AUTOSAR XML (schema 00044)
package /MICROSAR/NvM_swc/DataTypes
  impl type NvM_RequestResultType: compu {0=NVM_REQ_OK, 1=NVM_REQ_NOT_OK, 2=NVM_REQ_PENDING, 3=NVM_REQ_INTEGRITY_FAILED, 4=NVM_REQ_BLOCK_SKIPPED, 5=NVM_REQ_NV_INVALIDATED, 6=NVM_REQ_CANCELED, 7=NVM_REQ_REDUNDANCY_FAILED, 8=NVM_REQ_RESTORED_FROM_ROM}, range raw 0..8, implementation-data-type=uint8
  impl type NvM_BlockIdType: range raw 1..32767, implementation-data-type=uint16
  impl type NvM_ServiceIdType: compu {6=NVM_READ_BLOCK, 7=NVM_WRITE_BLOCK, 8=NVM_RESTORE_BLOCK_DEFAULTS, 9=NVM_ERASE_BLOCK, 11=NVM_INVALIDATE_NV_BLOCK, 12=NVM_READ_ALL}, range raw 6..12, implementation-data-type=uint8
package /MICROSAR/NvM_swc/Interfaces
  client server interface NvMAdministration: is-service=true, service-kind=NON-VOLATILE-RAM-MANAGER
    operation SetBlockProtection: possible-error=NvMAdministration/E_NOT_OK
      arg ProtectionEnabled: type=boolean, direction=IN
    error E_NOT_OK: error-code=1
  client server interface NvMService_AC3_SRBS_DS_Defs: is-service=true, service-kind=NON-VOLATILE-RAM-MANAGER
    9 x operation, all with possible-error=NvMService_AC3_SRBS_DS_Defs/E_NOT_OK:
      GetErrorStatus
        arg ErrorStatus: type=NvM_RequestResultType, direction=OUT
      SetRamBlockStatus
        arg RamBlockStatus: type=boolean, direction=IN
      ReadBlock
        arg DstPtr: type=dtRef_VOID, direction=IN
      WriteBlock
        arg SrcPtr: type=dtRef_const_VOID, direction=IN
      RestoreBlockDefaults
        arg DstPtr: type=dtRef_VOID, direction=IN
      SetDataIndex
        arg DataIndex: type=uint8, direction=IN
      GetDataIndex
        arg DataIndex: type=uint8, direction=OUT
      InvalidateNvBlock
      EraseBlock
    error E_NOT_OK: error-code=1
  client server interface NvMNotifyJobFinished: is-service=true, service-kind=NON-VOLATILE-RAM-MANAGER
    operation JobFinished
      arg ServiceId: type=NvM_ServiceIdType, direction=IN
      arg JobResult: type=NvM_RequestResultType, direction=IN
package /MICROSAR/NvM_swc/ComponentTypes
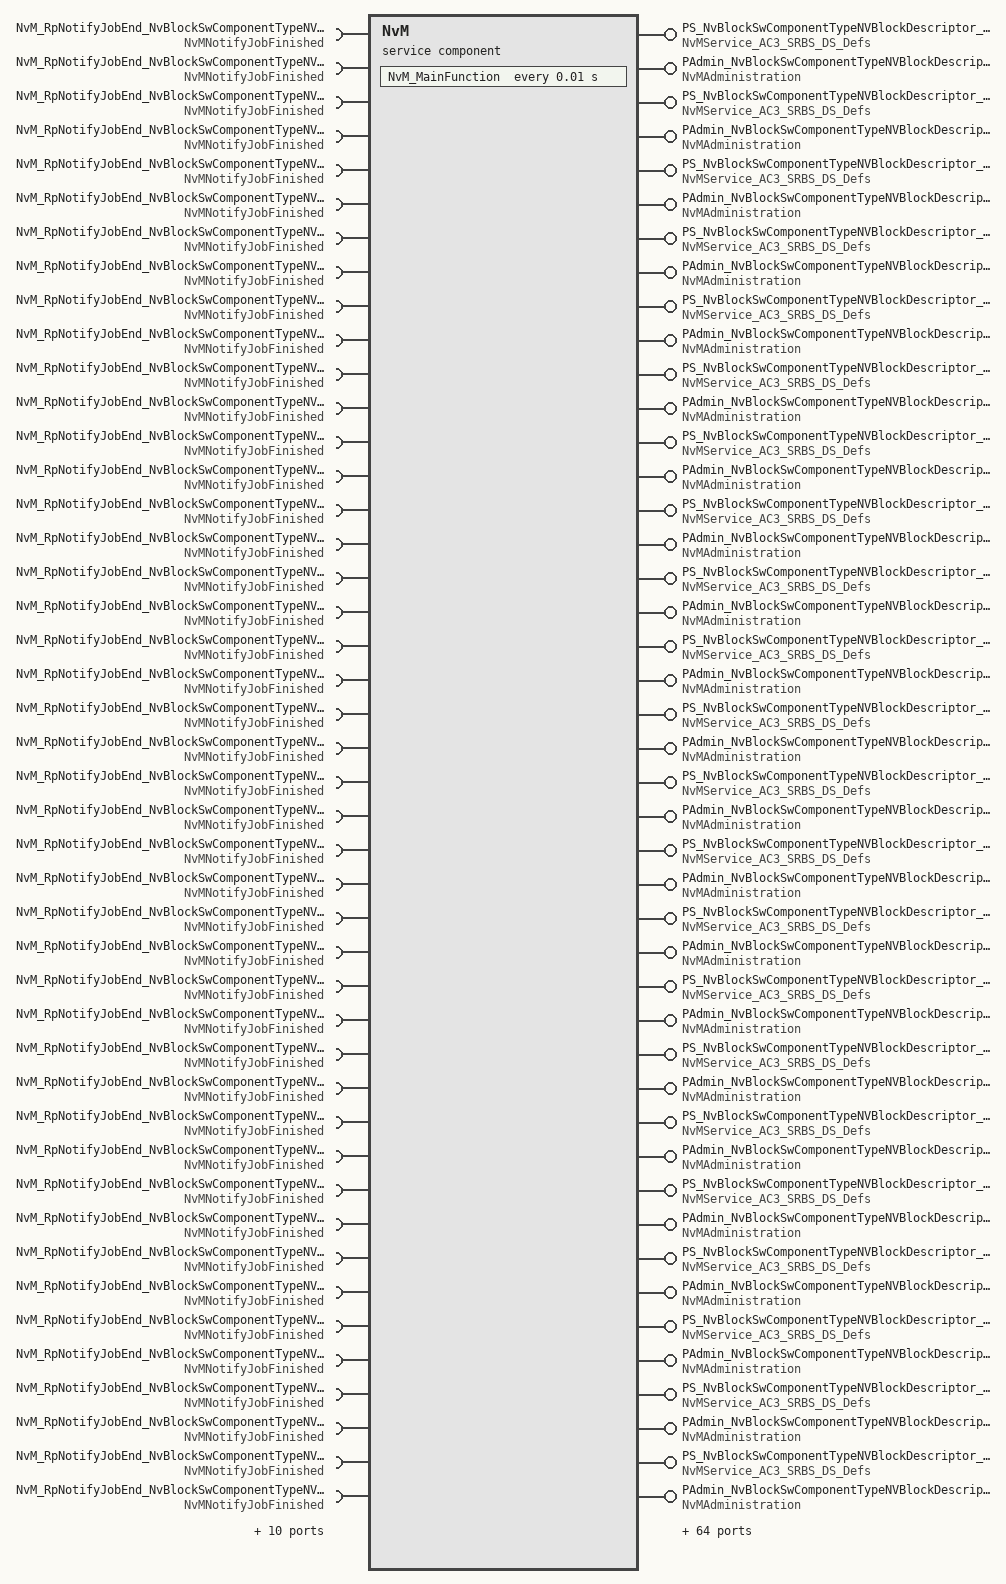
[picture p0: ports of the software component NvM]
  service sw component type NvM: category=SERVICE_COMPONENT
    108 x provide port:
      PS_NvBlockSwComponentTypeNVBlockDescriptor_BsConst_Audio: provided-interface=NvMService_AC3_SRBS_DS_Defs
      PAdmin_NvBlockSwComponentTypeNVBlockDescriptor_BsConst_Audio: provided-interface=NvMAdministration
      PS_NvBlockSwComponentTypeNVBlockDescriptor_BsConst_Communication: provided-interface=NvMService_AC3_SRBS_DS_Defs
      PAdmin_NvBlockSwComponentTypeNVBlockDescriptor_BsConst_Communication: provided-interface=NvMAdministration
      PS_NvBlockSwComponentTypeNVBlockDescriptor_BsConst_EngOffTimer: provided-interface=NvMService_AC3_SRBS_DS_Defs
      PAdmin_NvBlockSwComponentTypeNVBlockDescriptor_BsConst_EngOffTimer: provided-interface=NvMAdministration
      PS_NvBlockSwComponentTypeNVBlockDescriptor_BsConst_FuelGauge: provided-interface=NvMService_AC3_SRBS_DS_Defs
      PAdmin_NvBlockSwComponentTypeNVBlockDescriptor_BsConst_FuelGauge: provided-interface=NvMAdministration
      PS_NvBlockSwComponentTypeNVBlockDescriptor_BsConst_OilGauge: provided-interface=NvMService_AC3_SRBS_DS_Defs
      PAdmin_NvBlockSwComponentTypeNVBlockDescriptor_BsConst_OilGauge: provided-interface=NvMAdministration
      PS_NvBlockSwComponentTypeNVBlockDescriptor_BsConst_Power: provided-interface=NvMService_AC3_SRBS_DS_Defs
      PAdmin_NvBlockSwComponentTypeNVBlockDescriptor_BsConst_Power: provided-interface=NvMAdministration
      PS_NvBlockSwComponentTypeNVBlockDescriptor_BsConst_PowerGauge: provided-interface=NvMService_AC3_SRBS_DS_Defs
      PAdmin_NvBlockSwComponentTypeNVBlockDescriptor_BsConst_PowerGauge: provided-interface=NvMAdministration
      PS_NvBlockSwComponentTypeNVBlockDescriptor_BsConst_RealTimeClock: provided-interface=NvMService_AC3_SRBS_DS_Defs
      PAdmin_NvBlockSwComponentTypeNVBlockDescriptor_BsConst_RealTimeClock: provided-interface=NvMAdministration
      PS_NvBlockSwComponentTypeNVBlockDescriptor_BsConst_ServiceReminder: provided-interface=NvMService_AC3_SRBS_DS_Defs
      PAdmin_NvBlockSwComponentTypeNVBlockDescriptor_BsConst_ServiceReminder: provided-interface=NvMAdministration
      PS_NvBlockSwComponentTypeNVBlockDescriptor_BsConst_SpeedoGauge: provided-interface=NvMService_AC3_SRBS_DS_Defs
      PAdmin_NvBlockSwComponentTypeNVBlockDescriptor_BsConst_SpeedoGauge: provided-interface=NvMAdministration
      PS_NvBlockSwComponentTypeNVBlockDescriptor_BsConst_TachoGauge: provided-interface=NvMService_AC3_SRBS_DS_Defs
      PAdmin_NvBlockSwComponentTypeNVBlockDescriptor_BsConst_TachoGauge: provided-interface=NvMAdministration
      PS_NvBlockSwComponentTypeNVBlockDescriptor_BsConst_TempGauge: provided-interface=NvMService_AC3_SRBS_DS_Defs
      PAdmin_NvBlockSwComponentTypeNVBlockDescriptor_BsConst_TempGauge: provided-interface=NvMAdministration
      PS_NvBlockSwComponentTypeNVBlockDescriptor_BsConst_TripComputer: provided-interface=NvMService_AC3_SRBS_DS_Defs
      PAdmin_NvBlockSwComponentTypeNVBlockDescriptor_BsConst_TripComputer: provided-interface=NvMAdministration
      PS_NvBlockSwComponentTypeNVBlockDescriptor_BsConst_Warning: provided-interface=NvMService_AC3_SRBS_DS_Defs
      PAdmin_NvBlockSwComponentTypeNVBlockDescriptor_BsConst_Warning: provided-interface=NvMAdministration
      PS_NvBlockSwComponentTypeNVBlockDescriptor_BsCys_Certicificate: provided-interface=NvMService_AC3_SRBS_DS_Defs
      PAdmin_NvBlockSwComponentTypeNVBlockDescriptor_BsCys_Certicificate: provided-interface=NvMAdministration
      PS_NvBlockSwComponentTypeNVBlockDescriptor_BsDiag_Dtc: provided-interface=NvMService_AC3_SRBS_DS_Defs
      PAdmin_NvBlockSwComponentTypeNVBlockDescriptor_BsDiag_Dtc: provided-interface=NvMAdministration
      PS_NvBlockSwComponentTypeNVBlockDescriptor_BsDiag_ErrorRecord: provided-interface=NvMService_AC3_SRBS_DS_Defs
      PAdmin_NvBlockSwComponentTypeNVBlockDescriptor_BsDiag_ErrorRecord: provided-interface=NvMAdministration
      PS_NvBlockSwComponentTypeNVBlockDescriptor_BsReten_Audio: provided-interface=NvMService_AC3_SRBS_DS_Defs
      PAdmin_NvBlockSwComponentTypeNVBlockDescriptor_BsReten_Audio: provided-interface=NvMAdministration
      PS_NvBlockSwComponentTypeNVBlockDescriptor_BsReten_Communication: provided-interface=NvMService_AC3_SRBS_DS_Defs
      PAdmin_NvBlockSwComponentTypeNVBlockDescriptor_BsReten_Communication: provided-interface=NvMAdministration
      PS_NvBlockSwComponentTypeNVBlockDescriptor_BsReten_Display: provided-interface=NvMService_AC3_SRBS_DS_Defs
      PAdmin_NvBlockSwComponentTypeNVBlockDescriptor_BsReten_Display: provided-interface=NvMAdministration
      PS_NvBlockSwComponentTypeNVBlockDescriptor_BsReten_Gauges: provided-interface=NvMService_AC3_SRBS_DS_Defs
      PAdmin_NvBlockSwComponentTypeNVBlockDescriptor_BsReten_Gauges: provided-interface=NvMAdministration
      PS_NvBlockSwComponentTypeNVBlockDescriptor_BsReten_Illumination: provided-interface=NvMService_AC3_SRBS_DS_Defs
      PAdmin_NvBlockSwComponentTypeNVBlockDescriptor_BsReten_Illumination: provided-interface=NvMAdministration
      PS_NvBlockSwComponentTypeNVBlockDescriptor_BsReten_Odometer: provided-interface=NvMService_AC3_SRBS_DS_Defs
      PAdmin_NvBlockSwComponentTypeNVBlockDescriptor_BsReten_Odometer: provided-interface=NvMAdministration
      PS_NvBlockSwComponentTypeNVBlockDescriptor_BsReten_Personalization: provided-interface=NvMService_AC3_SRBS_DS_Defs
      PAdmin_NvBlockSwComponentTypeNVBlockDescriptor_BsReten_Personalization: provided-interface=NvMAdministration
      PS_NvBlockSwComponentTypeNVBlockDescriptor_BsReten_Power: provided-interface=NvMService_AC3_SRBS_DS_Defs
      PAdmin_NvBlockSwComponentTypeNVBlockDescriptor_BsReten_Power: provided-interface=NvMAdministration
      PS_NvBlockSwComponentTypeNVBlockDescriptor_BsReten_RealTimeClock: provided-interface=NvMService_AC3_SRBS_DS_Defs
      PAdmin_NvBlockSwComponentTypeNVBlockDescriptor_BsReten_RealTimeClock: provided-interface=NvMAdministration
      PS_NvBlockSwComponentTypeNVBlockDescriptor_BsReten_Tripcomputer: provided-interface=NvMService_AC3_SRBS_DS_Defs
      PAdmin_NvBlockSwComponentTypeNVBlockDescriptor_BsReten_Tripcomputer: provided-interface=NvMAdministration
      PS_NvBlockSwComponentTypeNVBlockDescriptor_BsReten_Warning: provided-interface=NvMService_AC3_SRBS_DS_Defs
      PAdmin_NvBlockSwComponentTypeNVBlockDescriptor_BsReten_Warning: provided-interface=NvMAdministration
      PS_NvBlockSwComponentTypeNVBlockDescriptor_BsRt_CusDlt: provided-interface=NvMService_AC3_SRBS_DS_Defs
      PAdmin_NvBlockSwComponentTypeNVBlockDescriptor_BsRt_CusDlt: provided-interface=NvMAdministration
      PS_NvBlockSwComponentTypeNVBlockDescriptor_BsRt_FuelGauge: provided-interface=NvMService_AC3_SRBS_DS_Defs
      PAdmin_NvBlockSwComponentTypeNVBlockDescriptor_BsRt_FuelGauge: provided-interface=NvMAdministration
      PS_NvBlockSwComponentTypeNVBlockDescriptor_BsRt_Illumination: provided-interface=NvMService_AC3_SRBS_DS_Defs
      PAdmin_NvBlockSwComponentTypeNVBlockDescriptor_BsRt_Illumination: provided-interface=NvMAdministration
      PS_NvBlockSwComponentTypeNVBlockDescriptor_BsRt_Odometer: provided-interface=NvMService_AC3_SRBS_DS_Defs
      PAdmin_NvBlockSwComponentTypeNVBlockDescriptor_BsRt_Odometer: provided-interface=NvMAdministration
      PS_NvBlockSwComponentTypeNVBlockDescriptor_BsRt_OilGauge: provided-interface=NvMService_AC3_SRBS_DS_Defs
      PAdmin_NvBlockSwComponentTypeNVBlockDescriptor_BsRt_OilGauge: provided-interface=NvMAdministration
      PS_NvBlockSwComponentTypeNVBlockDescriptor_BsRt_Personalization: provided-interface=NvMService_AC3_SRBS_DS_Defs
      PAdmin_NvBlockSwComponentTypeNVBlockDescriptor_BsRt_Personalization: provided-interface=NvMAdministration
      PS_NvBlockSwComponentTypeNVBlockDescriptor_BsRt_PowerGauge: provided-interface=NvMService_AC3_SRBS_DS_Defs
      PAdmin_NvBlockSwComponentTypeNVBlockDescriptor_BsRt_PowerGauge: provided-interface=NvMAdministration
      PS_NvBlockSwComponentTypeNVBlockDescriptor_BsRt_RealTimeClock: provided-interface=NvMService_AC3_SRBS_DS_Defs
      PAdmin_NvBlockSwComponentTypeNVBlockDescriptor_BsRt_RealTimeClock: provided-interface=NvMAdministration
      PS_NvBlockSwComponentTypeNVBlockDescriptor_BsRt_SpeedoGauge: provided-interface=NvMService_AC3_SRBS_DS_Defs
      PAdmin_NvBlockSwComponentTypeNVBlockDescriptor_BsRt_SpeedoGauge: provided-interface=NvMAdministration
      PS_NvBlockSwComponentTypeNVBlockDescriptor_BsRt_TachoGauge: provided-interface=NvMService_AC3_SRBS_DS_Defs
      PAdmin_NvBlockSwComponentTypeNVBlockDescriptor_BsRt_TachoGauge: provided-interface=NvMAdministration
      PS_NvBlockSwComponentTypeNVBlockDescriptor_BsRt_TempGauge: provided-interface=NvMService_AC3_SRBS_DS_Defs
      PAdmin_NvBlockSwComponentTypeNVBlockDescriptor_BsRt_TempGauge: provided-interface=NvMAdministration
      PS_NvBlockSwComponentTypeNVBlockDescriptor_BsRt_TripComputer: provided-interface=NvMService_AC3_SRBS_DS_Defs
      PAdmin_NvBlockSwComponentTypeNVBlockDescriptor_BsRt_TripComputer: provided-interface=NvMAdministration
      PS_NvBlockSwComponentTypeNVBlockDescriptor_BsRt_Warning: provided-interface=NvMService_AC3_SRBS_DS_Defs
      PAdmin_NvBlockSwComponentTypeNVBlockDescriptor_BsRt_Warning: provided-interface=NvMAdministration
      PS_NvBlockSwComponentTypeNVBlockDescriptor_BsShare_EcuPartNumber: provided-interface=NvMService_AC3_SRBS_DS_Defs
      PAdmin_NvBlockSwComponentTypeNVBlockDescriptor_BsShare_EcuPartNumber: provided-interface=NvMAdministration
      PS_NvBlockSwComponentTypeNVBlockDescriptor_BsShare_SwUpdFotaFinPrint: provided-interface=NvMService_AC3_SRBS_DS_Defs
      PAdmin_NvBlockSwComponentTypeNVBlockDescriptor_BsShare_SwUpdFotaFinPrint: provided-interface=NvMAdministration
      PS_NvBlockSwComponentTypeNVBlockDescriptor_BsShare_SwUpdFotaMode: provided-interface=NvMService_AC3_SRBS_DS_Defs
      PAdmin_NvBlockSwComponentTypeNVBlockDescriptor_BsShare_SwUpdFotaMode: provided-interface=NvMAdministration
      PS_NvBlockSwComponentTypeNVBlockDescriptor_BsShare_SwUpdFotaStatus: provided-interface=NvMService_AC3_SRBS_DS_Defs
      PAdmin_NvBlockSwComponentTypeNVBlockDescriptor_BsShare_SwUpdFotaStatus: provided-interface=NvMAdministration
      PS_NvBlockSwComponentTypeNVBlockDescriptor_BsShare_SwUpdFotadecrypt: provided-interface=NvMService_AC3_SRBS_DS_Defs
      PAdmin_NvBlockSwComponentTypeNVBlockDescriptor_BsShare_SwUpdFotadecrypt: provided-interface=NvMAdministration
      PS_NvBlockSwComponentTypeNVBlockDescriptor_BsShare_SwUpdReflash: provided-interface=NvMService_AC3_SRBS_DS_Defs
      PAdmin_NvBlockSwComponentTypeNVBlockDescriptor_BsShare_SwUpdReflash: provided-interface=NvMAdministration
      PS_NvBlockSwComponentTypeNVBlockDescriptor_BsShare_VehicleConfig: provided-interface=NvMService_AC3_SRBS_DS_Defs
      PAdmin_NvBlockSwComponentTypeNVBlockDescriptor_BsShare_VehicleConfig: provided-interface=NvMAdministration
      PS_NvBlockSwComponentTypeNVBlockDescriptor_BsShare_VisMeet: provided-interface=NvMService_AC3_SRBS_DS_Defs
      PAdmin_NvBlockSwComponentTypeNVBlockDescriptor_BsShare_VisMeet: provided-interface=NvMAdministration
      PS_NvBlockSwComponentTypeNVBlockDescriptor_RefCys_Certicificate: provided-interface=NvMService_AC3_SRBS_DS_Defs
      PAdmin_NvBlockSwComponentTypeNVBlockDescriptor_RefCys_Certicificate: provided-interface=NvMAdministration
      PS_NvBlockSwComponentTypeNVBlockDescriptor_RefCys_Certicificate1: provided-interface=NvMService_AC3_SRBS_DS_Defs
      PAdmin_NvBlockSwComponentTypeNVBlockDescriptor_RefCys_Certicificate1: provided-interface=NvMAdministration
      PS_NvBlockSwComponentTypeNVBlockDescriptor_BsConst_Illumination: provided-interface=NvMService_AC3_SRBS_DS_Defs
      PAdmin_NvBlockSwComponentTypeNVBlockDescriptor_BsConst_Illumination: provided-interface=NvMAdministration
      PS_NvBlockSwComponentTypeNVBlockDescriptor_BsConst_Illumination_Copy1: provided-interface=NvMService_AC3_SRBS_DS_Defs
      PAdmin_NvBlockSwComponentTypeNVBlockDescriptor_BsConst_Illumination_Copy1: provided-interface=NvMAdministration
      PS_NvBlockSwComponentTypeNVBlockDescriptor_BsConst_Illumination_Copy2: provided-interface=NvMService_AC3_SRBS_DS_Defs
      PAdmin_NvBlockSwComponentTypeNVBlockDescriptor_BsConst_Illumination_Copy2: provided-interface=NvMAdministration
    54 x require port, all with required-interface=NvMNotifyJobFinished:
      NvM_RpNotifyJobEnd_NvBlockSwComponentTypeNVBlockDescriptor_BsConst_Audio
      NvM_RpNotifyJobEnd_NvBlockSwComponentTypeNVBlockDescriptor_BsConst_Communication
      NvM_RpNotifyJobEnd_NvBlockSwComponentTypeNVBlockDescriptor_BsConst_EngOffTimer
      NvM_RpNotifyJobEnd_NvBlockSwComponentTypeNVBlockDescriptor_BsConst_FuelGauge
      NvM_RpNotifyJobEnd_NvBlockSwComponentTypeNVBlockDescriptor_BsConst_Illumination
      NvM_RpNotifyJobEnd_NvBlockSwComponentTypeNVBlockDescriptor_BsConst_Illumination_Copy1
      NvM_RpNotifyJobEnd_NvBlockSwComponentTypeNVBlockDescriptor_BsConst_Illumination_Copy2
      NvM_RpNotifyJobEnd_NvBlockSwComponentTypeNVBlockDescriptor_BsConst_OilGauge
      NvM_RpNotifyJobEnd_NvBlockSwComponentTypeNVBlockDescriptor_BsConst_Power
      NvM_RpNotifyJobEnd_NvBlockSwComponentTypeNVBlockDescriptor_BsConst_PowerGauge
      NvM_RpNotifyJobEnd_NvBlockSwComponentTypeNVBlockDescriptor_BsConst_RealTimeClock
      NvM_RpNotifyJobEnd_NvBlockSwComponentTypeNVBlockDescriptor_BsConst_ServiceReminder
      NvM_RpNotifyJobEnd_NvBlockSwComponentTypeNVBlockDescriptor_BsConst_SpeedoGauge
      NvM_RpNotifyJobEnd_NvBlockSwComponentTypeNVBlockDescriptor_BsConst_TachoGauge
      NvM_RpNotifyJobEnd_NvBlockSwComponentTypeNVBlockDescriptor_BsConst_TempGauge
      NvM_RpNotifyJobEnd_NvBlockSwComponentTypeNVBlockDescriptor_BsConst_TripComputer
      NvM_RpNotifyJobEnd_NvBlockSwComponentTypeNVBlockDescriptor_BsConst_Warning
      NvM_RpNotifyJobEnd_NvBlockSwComponentTypeNVBlockDescriptor_BsCys_Certicificate
      NvM_RpNotifyJobEnd_NvBlockSwComponentTypeNVBlockDescriptor_BsDiag_Dtc
      NvM_RpNotifyJobEnd_NvBlockSwComponentTypeNVBlockDescriptor_BsDiag_ErrorRecord
      NvM_RpNotifyJobEnd_NvBlockSwComponentTypeNVBlockDescriptor_BsReten_Audio
      NvM_RpNotifyJobEnd_NvBlockSwComponentTypeNVBlockDescriptor_BsReten_Communication
      NvM_RpNotifyJobEnd_NvBlockSwComponentTypeNVBlockDescriptor_BsReten_Display
      NvM_RpNotifyJobEnd_NvBlockSwComponentTypeNVBlockDescriptor_BsReten_Gauges
      NvM_RpNotifyJobEnd_NvBlockSwComponentTypeNVBlockDescriptor_BsReten_Illumination
      NvM_RpNotifyJobEnd_NvBlockSwComponentTypeNVBlockDescriptor_BsReten_Odometer
      NvM_RpNotifyJobEnd_NvBlockSwComponentTypeNVBlockDescriptor_BsReten_Personalization
      NvM_RpNotifyJobEnd_NvBlockSwComponentTypeNVBlockDescriptor_BsReten_Power
      NvM_RpNotifyJobEnd_NvBlockSwComponentTypeNVBlockDescriptor_BsReten_RealTimeClock
      NvM_RpNotifyJobEnd_NvBlockSwComponentTypeNVBlockDescriptor_BsReten_Tripcomputer
      NvM_RpNotifyJobEnd_NvBlockSwComponentTypeNVBlockDescriptor_BsReten_Warning
      NvM_RpNotifyJobEnd_NvBlockSwComponentTypeNVBlockDescriptor_BsRt_CusDlt
      NvM_RpNotifyJobEnd_NvBlockSwComponentTypeNVBlockDescriptor_BsRt_FuelGauge
      NvM_RpNotifyJobEnd_NvBlockSwComponentTypeNVBlockDescriptor_BsRt_Illumination
      NvM_RpNotifyJobEnd_NvBlockSwComponentTypeNVBlockDescriptor_BsRt_Odometer
      NvM_RpNotifyJobEnd_NvBlockSwComponentTypeNVBlockDescriptor_BsRt_OilGauge
      NvM_RpNotifyJobEnd_NvBlockSwComponentTypeNVBlockDescriptor_BsRt_Personalization
      NvM_RpNotifyJobEnd_NvBlockSwComponentTypeNVBlockDescriptor_BsRt_PowerGauge
      NvM_RpNotifyJobEnd_NvBlockSwComponentTypeNVBlockDescriptor_BsRt_RealTimeClock
      NvM_RpNotifyJobEnd_NvBlockSwComponentTypeNVBlockDescriptor_BsRt_SpeedoGauge
      NvM_RpNotifyJobEnd_NvBlockSwComponentTypeNVBlockDescriptor_BsRt_TachoGauge
      NvM_RpNotifyJobEnd_NvBlockSwComponentTypeNVBlockDescriptor_BsRt_TempGauge
      NvM_RpNotifyJobEnd_NvBlockSwComponentTypeNVBlockDescriptor_BsRt_TripComputer
      NvM_RpNotifyJobEnd_NvBlockSwComponentTypeNVBlockDescriptor_BsRt_Warning
      NvM_RpNotifyJobEnd_NvBlockSwComponentTypeNVBlockDescriptor_BsShare_EcuPartNumber
      NvM_RpNotifyJobEnd_NvBlockSwComponentTypeNVBlockDescriptor_BsShare_SwUpdFotaFinPrint
      NvM_RpNotifyJobEnd_NvBlockSwComponentTypeNVBlockDescriptor_BsShare_SwUpdFotaMode
      NvM_RpNotifyJobEnd_NvBlockSwComponentTypeNVBlockDescriptor_BsShare_SwUpdFotaStatus
      NvM_RpNotifyJobEnd_NvBlockSwComponentTypeNVBlockDescriptor_BsShare_SwUpdFotadecrypt
      NvM_RpNotifyJobEnd_NvBlockSwComponentTypeNVBlockDescriptor_BsShare_SwUpdReflash
      NvM_RpNotifyJobEnd_NvBlockSwComponentTypeNVBlockDescriptor_BsShare_VehicleConfig
      NvM_RpNotifyJobEnd_NvBlockSwComponentTypeNVBlockDescriptor_BsShare_VisMeet
      NvM_RpNotifyJobEnd_NvBlockSwComponentTypeNVBlockDescriptor_RefCys_Certicificate
      NvM_RpNotifyJobEnd_NvBlockSwComponentTypeNVBlockDescriptor_RefCys_Certicificate1
    behavior NvMInternalBehavior: handle-termination-and-restart=NO-SUPPORT
      timing event Timer_NvM_MainFunction: start-on-event=NvM_MainFunction, period=0.01
      540 x operation invoked event:
        OpEventGetErrorStatus_GetErrorStatus_PS_NvBlockSwComponentTypeNVBlockDescriptor_BsConst_Audio: start-on-event=GetErrorStatus, operation=PS_NvBlockSwComponentTypeNVBlockDescriptor_BsConst_Audio.GetErrorStatus
        OpEventGetErrorStatus_GetErrorStatus_PS_NvBlockSwComponentTypeNVBlockDescriptor_BsConst_Communication: start-on-event=GetErrorStatus, operation=PS_NvBlockSwComponentTypeNVBlockDescriptor_BsConst_Communication.GetErrorStatus
        OpEventGetErrorStatus_GetErrorStatus_PS_NvBlockSwComponentTypeNVBlockDescriptor_BsConst_EngOffTimer: start-on-event=GetErrorStatus, operation=PS_NvBlockSwComponentTypeNVBlockDescriptor_BsConst_EngOffTimer.GetErrorStatus
        OpEventGetErrorStatus_GetErrorStatus_PS_NvBlockSwComponentTypeNVBlockDescriptor_BsConst_FuelGauge: start-on-event=GetErrorStatus, operation=PS_NvBlockSwComponentTypeNVBlockDescriptor_BsConst_FuelGauge.GetErrorStatus
        OpEventGetErrorStatus_GetErrorStatus_PS_NvBlockSwComponentTypeNVBlockDescriptor_BsConst_OilGauge: start-on-event=GetErrorStatus, operation=PS_NvBlockSwComponentTypeNVBlockDescriptor_BsConst_OilGauge.GetErrorStatus
        OpEventGetErrorStatus_GetErrorStatus_PS_NvBlockSwComponentTypeNVBlockDescriptor_BsConst_Power: start-on-event=GetErrorStatus, operation=PS_NvBlockSwComponentTypeNVBlockDescriptor_BsConst_Power.GetErrorStatus
        OpEventGetErrorStatus_GetErrorStatus_PS_NvBlockSwComponentTypeNVBlockDescriptor_BsConst_PowerGauge: start-on-event=GetErrorStatus, operation=PS_NvBlockSwComponentTypeNVBlockDescriptor_BsConst_PowerGauge.GetErrorStatus
        OpEventGetErrorStatus_GetErrorStatus_PS_NvBlockSwComponentTypeNVBlockDescriptor_BsConst_RealTimeClock: start-on-event=GetErrorStatus, operation=PS_NvBlockSwComponentTypeNVBlockDescriptor_BsConst_RealTimeClock.GetErrorStatus
        OpEventGetErrorStatus_GetErrorStatus_PS_NvBlockSwComponentTypeNVBlockDescriptor_BsConst_ServiceReminder: start-on-event=GetErrorStatus, operation=PS_NvBlockSwComponentTypeNVBlockDescriptor_BsConst_ServiceReminder.GetErrorStatus
        OpEventGetErrorStatus_GetErrorStatus_PS_NvBlockSwComponentTypeNVBlockDescriptor_BsConst_SpeedoGauge: start-on-event=GetErrorStatus, operation=PS_NvBlockSwComponentTypeNVBlockDescriptor_BsConst_SpeedoGauge.GetErrorStatus
        OpEventGetErrorStatus_GetErrorStatus_PS_NvBlockSwComponentTypeNVBlockDescriptor_BsConst_TachoGauge: start-on-event=GetErrorStatus, operation=PS_NvBlockSwComponentTypeNVBlockDescriptor_BsConst_TachoGauge.GetErrorStatus
        OpEventGetErrorStatus_GetErrorStatus_PS_NvBlockSwComponentTypeNVBlockDescriptor_BsConst_TempGauge: start-on-event=GetErrorStatus, operation=PS_NvBlockSwComponentTypeNVBlockDescriptor_BsConst_TempGauge.GetErrorStatus
        OpEventGetErrorStatus_GetErrorStatus_PS_NvBlockSwComponentTypeNVBlockDescriptor_BsConst_TripComputer: start-on-event=GetErrorStatus, operation=PS_NvBlockSwComponentTypeNVBlockDescriptor_BsConst_TripComputer.GetErrorStatus
        OpEventGetErrorStatus_GetErrorStatus_PS_NvBlockSwComponentTypeNVBlockDescriptor_BsConst_Warning: start-on-event=GetErrorStatus, operation=PS_NvBlockSwComponentTypeNVBlockDescriptor_BsConst_Warning.GetErrorStatus
        OpEventGetErrorStatus_GetErrorStatus_PS_NvBlockSwComponentTypeNVBlockDescriptor_BsCys_Certicificate: start-on-event=GetErrorStatus, operation=PS_NvBlockSwComponentTypeNVBlockDescriptor_BsCys_Certicificate.GetErrorStatus
        OpEventGetErrorStatus_GetErrorStatus_PS_NvBlockSwComponentTypeNVBlockDescriptor_BsDiag_Dtc: start-on-event=GetErrorStatus, operation=PS_NvBlockSwComponentTypeNVBlockDescriptor_BsDiag_Dtc.GetErrorStatus
        OpEventGetErrorStatus_GetErrorStatus_PS_NvBlockSwComponentTypeNVBlockDescriptor_BsDiag_ErrorRecord: start-on-event=GetErrorStatus, operation=PS_NvBlockSwComponentTypeNVBlockDescriptor_BsDiag_ErrorRecord.GetErrorStatus
        OpEventGetErrorStatus_GetErrorStatus_PS_NvBlockSwComponentTypeNVBlockDescriptor_BsReten_Audio: start-on-event=GetErrorStatus, operation=PS_NvBlockSwComponentTypeNVBlockDescriptor_BsReten_Audio.GetErrorStatus
        OpEventGetErrorStatus_GetErrorStatus_PS_NvBlockSwComponentTypeNVBlockDescriptor_BsReten_Communication: start-on-event=GetErrorStatus, operation=PS_NvBlockSwComponentTypeNVBlockDescriptor_BsReten_Communication.GetErrorStatus
        OpEventGetErrorStatus_GetErrorStatus_PS_NvBlockSwComponentTypeNVBlockDescriptor_BsReten_Display: start-on-event=GetErrorStatus, operation=PS_NvBlockSwComponentTypeNVBlockDescriptor_BsReten_Display.GetErrorStatus
        OpEventGetErrorStatus_GetErrorStatus_PS_NvBlockSwComponentTypeNVBlockDescriptor_BsReten_Gauges: start-on-event=GetErrorStatus, operation=PS_NvBlockSwComponentTypeNVBlockDescriptor_BsReten_Gauges.GetErrorStatus
        OpEventGetErrorStatus_GetErrorStatus_PS_NvBlockSwComponentTypeNVBlockDescriptor_BsReten_Illumination: start-on-event=GetErrorStatus, operation=PS_NvBlockSwComponentTypeNVBlockDescriptor_BsReten_Illumination.GetErrorStatus
        OpEventGetErrorStatus_GetErrorStatus_PS_NvBlockSwComponentTypeNVBlockDescriptor_BsReten_Odometer: start-on-event=GetErrorStatus, operation=PS_NvBlockSwComponentTypeNVBlockDescriptor_BsReten_Odometer.GetErrorStatus
        OpEventGetErrorStatus_GetErrorStatus_PS_NvBlockSwComponentTypeNVBlockDescriptor_BsReten_Personalization: start-on-event=GetErrorStatus, operation=PS_NvBlockSwComponentTypeNVBlockDescriptor_BsReten_Personalization.GetErrorStatus
        OpEventGetErrorStatus_GetErrorStatus_PS_NvBlockSwComponentTypeNVBlockDescriptor_BsReten_Power: start-on-event=GetErrorStatus, operation=PS_NvBlockSwComponentTypeNVBlockDescriptor_BsReten_Power.GetErrorStatus
        OpEventGetErrorStatus_GetErrorStatus_PS_NvBlockSwComponentTypeNVBlockDescriptor_BsReten_RealTimeClock: start-on-event=GetErrorStatus, operation=PS_NvBlockSwComponentTypeNVBlockDescriptor_BsReten_RealTimeClock.GetErrorStatus
        OpEventGetErrorStatus_GetErrorStatus_PS_NvBlockSwComponentTypeNVBlockDescriptor_BsReten_Tripcomputer: start-on-event=GetErrorStatus, operation=PS_NvBlockSwComponentTypeNVBlockDescriptor_BsReten_Tripcomputer.GetErrorStatus
        OpEventGetErrorStatus_GetErrorStatus_PS_NvBlockSwComponentTypeNVBlockDescriptor_BsReten_Warning: start-on-event=GetErrorStatus, operation=PS_NvBlockSwComponentTypeNVBlockDescriptor_BsReten_Warning.GetErrorStatus
        OpEventGetErrorStatus_GetErrorStatus_PS_NvBlockSwComponentTypeNVBlockDescriptor_BsRt_CusDlt: start-on-event=GetErrorStatus, operation=PS_NvBlockSwComponentTypeNVBlockDescriptor_BsRt_CusDlt.GetErrorStatus
        OpEventGetErrorStatus_GetErrorStatus_PS_NvBlockSwComponentTypeNVBlockDescriptor_BsRt_FuelGauge: start-on-event=GetErrorStatus, operation=PS_NvBlockSwComponentTypeNVBlockDescriptor_BsRt_FuelGauge.GetErrorStatus
        OpEventGetErrorStatus_GetErrorStatus_PS_NvBlockSwComponentTypeNVBlockDescriptor_BsRt_Illumination: start-on-event=GetErrorStatus, operation=PS_NvBlockSwComponentTypeNVBlockDescriptor_BsRt_Illumination.GetErrorStatus
        OpEventGetErrorStatus_GetErrorStatus_PS_NvBlockSwComponentTypeNVBlockDescriptor_BsRt_Odometer: start-on-event=GetErrorStatus, operation=PS_NvBlockSwComponentTypeNVBlockDescriptor_BsRt_Odometer.GetErrorStatus
        OpEventGetErrorStatus_GetErrorStatus_PS_NvBlockSwComponentTypeNVBlockDescriptor_BsRt_OilGauge: start-on-event=GetErrorStatus, operation=PS_NvBlockSwComponentTypeNVBlockDescriptor_BsRt_OilGauge.GetErrorStatus
        OpEventGetErrorStatus_GetErrorStatus_PS_NvBlockSwComponentTypeNVBlockDescriptor_BsRt_Personalization: start-on-event=GetErrorStatus, operation=PS_NvBlockSwComponentTypeNVBlockDescriptor_BsRt_Personalization.GetErrorStatus
        OpEventGetErrorStatus_GetErrorStatus_PS_NvBlockSwComponentTypeNVBlockDescriptor_BsRt_PowerGauge: start-on-event=GetErrorStatus, operation=PS_NvBlockSwComponentTypeNVBlockDescriptor_BsRt_PowerGauge.GetErrorStatus
        OpEventGetErrorStatus_GetErrorStatus_PS_NvBlockSwComponentTypeNVBlockDescriptor_BsRt_RealTimeClock: start-on-event=GetErrorStatus, operation=PS_NvBlockSwComponentTypeNVBlockDescriptor_BsRt_RealTimeClock.GetErrorStatus
        OpEventGetErrorStatus_GetErrorStatus_PS_NvBlockSwComponentTypeNVBlockDescriptor_BsRt_SpeedoGauge: start-on-event=GetErrorStatus, operation=PS_NvBlockSwComponentTypeNVBlockDescriptor_BsRt_SpeedoGauge.GetErrorStatus
        OpEventGetErrorStatus_GetErrorStatus_PS_NvBlockSwComponentTypeNVBlockDescriptor_BsRt_TachoGauge: start-on-event=GetErrorStatus, operation=PS_NvBlockSwComponentTypeNVBlockDescriptor_BsRt_TachoGauge.GetErrorStatus
        OpEventGetErrorStatus_GetErrorStatus_PS_NvBlockSwComponentTypeNVBlockDescriptor_BsRt_TempGauge: start-on-event=GetErrorStatus, operation=PS_NvBlockSwComponentTypeNVBlockDescriptor_BsRt_TempGauge.GetErrorStatus
        OpEventGetErrorStatus_GetErrorStatus_PS_NvBlockSwComponentTypeNVBlockDescriptor_BsRt_TripComputer: start-on-event=GetErrorStatus, operation=PS_NvBlockSwComponentTypeNVBlockDescriptor_BsRt_TripComputer.GetErrorStatus
        OpEventGetErrorStatus_GetErrorStatus_PS_NvBlockSwComponentTypeNVBlockDescriptor_BsRt_Warning: start-on-event=GetErrorStatus, operation=PS_NvBlockSwComponentTypeNVBlockDescriptor_BsRt_Warning.GetErrorStatus
        OpEventGetErrorStatus_GetErrorStatus_PS_NvBlockSwComponentTypeNVBlockDescriptor_BsShare_EcuPartNumber: start-on-event=GetErrorStatus, operation=PS_NvBlockSwComponentTypeNVBlockDescriptor_BsShare_EcuPartNumber.GetErrorStatus
        OpEventGetErrorStatus_GetErrorStatus_PS_NvBlockSwComponentTypeNVBlockDescriptor_BsShare_SwUpdFotaFinPrint: start-on-event=GetErrorStatus, operation=PS_NvBlockSwComponentTypeNVBlockDescriptor_BsShare_SwUpdFotaFinPrint.GetErrorStatus
        OpEventGetErrorStatus_GetErrorStatus_PS_NvBlockSwComponentTypeNVBlockDescriptor_BsShare_SwUpdFotaMode: start-on-event=GetErrorStatus, operation=PS_NvBlockSwComponentTypeNVBlockDescriptor_BsShare_SwUpdFotaMode.GetErrorStatus
        OpEventGetErrorStatus_GetErrorStatus_PS_NvBlockSwComponentTypeNVBlockDescriptor_BsShare_SwUpdFotaStatus: start-on-event=GetErrorStatus, operation=PS_NvBlockSwComponentTypeNVBlockDescriptor_BsShare_SwUpdFotaStatus.GetErrorStatus
        OpEventGetErrorStatus_GetErrorStatus_PS_NvBlockSwComponentTypeNVBlockDescriptor_BsShare_SwUpdFotadecrypt: start-on-event=GetErrorStatus, operation=PS_NvBlockSwComponentTypeNVBlockDescriptor_BsShare_SwUpdFotadecrypt.GetErrorStatus
        OpEventGetErrorStatus_GetErrorStatus_PS_NvBlockSwComponentTypeNVBlockDescriptor_BsShare_SwUpdReflash: start-on-event=GetErrorStatus, operation=PS_NvBlockSwComponentTypeNVBlockDescriptor_BsShare_SwUpdReflash.GetErrorStatus
        OpEventGetErrorStatus_GetErrorStatus_PS_NvBlockSwComponentTypeNVBlockDescriptor_BsShare_VehicleConfig: start-on-event=GetErrorStatus, operation=PS_NvBlockSwComponentTypeNVBlockDescriptor_BsShare_VehicleConfig.GetErrorStatus
        OpEventGetErrorStatus_GetErrorStatus_PS_NvBlockSwComponentTypeNVBlockDescriptor_BsShare_VisMeet: start-on-event=GetErrorStatus, operation=PS_NvBlockSwComponentTypeNVBlockDescriptor_BsShare_VisMeet.GetErrorStatus
        OpEventGetErrorStatus_GetErrorStatus_PS_NvBlockSwComponentTypeNVBlockDescriptor_RefCys_Certicificate: start-on-event=GetErrorStatus, operation=PS_NvBlockSwComponentTypeNVBlockDescriptor_RefCys_Certicificate.GetErrorStatus
        OpEventGetErrorStatus_GetErrorStatus_PS_NvBlockSwComponentTypeNVBlockDescriptor_RefCys_Certicificate1: start-on-event=GetErrorStatus, operation=PS_NvBlockSwComponentTypeNVBlockDescriptor_RefCys_Certicificate1.GetErrorStatus
        OpEventSetRamBlockStatus_SetRamBlockStatus_PS_NvBlockSwComponentTypeNVBlockDescriptor_BsConst_Audio: start-on-event=SetRamBlockStatus, operation=PS_NvBlockSwComponentTypeNVBlockDescriptor_BsConst_Audio.SetRamBlockStatus
        OpEventSetRamBlockStatus_SetRamBlockStatus_PS_NvBlockSwComponentTypeNVBlockDescriptor_BsConst_Communication: start-on-event=SetRamBlockStatus, operation=PS_NvBlockSwComponentTypeNVBlockDescriptor_BsConst_Communication.SetRamBlockStatus
        OpEventSetRamBlockStatus_SetRamBlockStatus_PS_NvBlockSwComponentTypeNVBlockDescriptor_BsConst_EngOffTimer: start-on-event=SetRamBlockStatus, operation=PS_NvBlockSwComponentTypeNVBlockDescriptor_BsConst_EngOffTimer.SetRamBlockStatus
        OpEventSetRamBlockStatus_SetRamBlockStatus_PS_NvBlockSwComponentTypeNVBlockDescriptor_BsConst_FuelGauge: start-on-event=SetRamBlockStatus, operation=PS_NvBlockSwComponentTypeNVBlockDescriptor_BsConst_FuelGauge.SetRamBlockStatus
        OpEventSetRamBlockStatus_SetRamBlockStatus_PS_NvBlockSwComponentTypeNVBlockDescriptor_BsConst_OilGauge: start-on-event=SetRamBlockStatus, operation=PS_NvBlockSwComponentTypeNVBlockDescriptor_BsConst_OilGauge.SetRamBlockStatus
        OpEventSetRamBlockStatus_SetRamBlockStatus_PS_NvBlockSwComponentTypeNVBlockDescriptor_BsConst_Power: start-on-event=SetRamBlockStatus, operation=PS_NvBlockSwComponentTypeNVBlockDescriptor_BsConst_Power.SetRamBlockStatus
        OpEventSetRamBlockStatus_SetRamBlockStatus_PS_NvBlockSwComponentTypeNVBlockDescriptor_BsConst_PowerGauge: start-on-event=SetRamBlockStatus, operation=PS_NvBlockSwComponentTypeNVBlockDescriptor_BsConst_PowerGauge.SetRamBlockStatus
        OpEventSetRamBlockStatus_SetRamBlockStatus_PS_NvBlockSwComponentTypeNVBlockDescriptor_BsConst_RealTimeClock: start-on-event=SetRamBlockStatus, operation=PS_NvBlockSwComponentTypeNVBlockDescriptor_BsConst_RealTimeClock.SetRamBlockStatus
        OpEventSetRamBlockStatus_SetRamBlockStatus_PS_NvBlockSwComponentTypeNVBlockDescriptor_BsConst_ServiceReminder: start-on-event=SetRamBlockStatus, operation=PS_NvBlockSwComponentTypeNVBlockDescriptor_BsConst_ServiceReminder.SetRamBlockStatus
        OpEventSetRamBlockStatus_SetRamBlockStatus_PS_NvBlockSwComponentTypeNVBlockDescriptor_BsConst_SpeedoGauge: start-on-event=SetRamBlockStatus, operation=PS_NvBlockSwComponentTypeNVBlockDescriptor_BsConst_SpeedoGauge.SetRamBlockStatus
        OpEventSetRamBlockStatus_SetRamBlockStatus_PS_NvBlockSwComponentTypeNVBlockDescriptor_BsConst_TachoGauge: start-on-event=SetRamBlockStatus, operation=PS_NvBlockSwComponentTypeNVBlockDescriptor_BsConst_TachoGauge.SetRamBlockStatus
        OpEventSetRamBlockStatus_SetRamBlockStatus_PS_NvBlockSwComponentTypeNVBlockDescriptor_BsConst_TempGauge: start-on-event=SetRamBlockStatus, operation=PS_NvBlockSwComponentTypeNVBlockDescriptor_BsConst_TempGauge.SetRamBlockStatus
        OpEventSetRamBlockStatus_SetRamBlockStatus_PS_NvBlockSwComponentTypeNVBlockDescriptor_BsConst_TripComputer: start-on-event=SetRamBlockStatus, operation=PS_NvBlockSwComponentTypeNVBlockDescriptor_BsConst_TripComputer.SetRamBlockStatus
        OpEventSetRamBlockStatus_SetRamBlockStatus_PS_NvBlockSwComponentTypeNVBlockDescriptor_BsConst_Warning: start-on-event=SetRamBlockStatus, operation=PS_NvBlockSwComponentTypeNVBlockDescriptor_BsConst_Warning.SetRamBlockStatus
        OpEventSetRamBlockStatus_SetRamBlockStatus_PS_NvBlockSwComponentTypeNVBlockDescriptor_BsCys_Certicificate: start-on-event=SetRamBlockStatus, operation=PS_NvBlockSwComponentTypeNVBlockDescriptor_BsCys_Certicificate.SetRamBlockStatus
        OpEventSetRamBlockStatus_SetRamBlockStatus_PS_NvBlockSwComponentTypeNVBlockDescriptor_BsDiag_Dtc: start-on-event=SetRamBlockStatus, operation=PS_NvBlockSwComponentTypeNVBlockDescriptor_BsDiag_Dtc.SetRamBlockStatus
        OpEventSetRamBlockStatus_SetRamBlockStatus_PS_NvBlockSwComponentTypeNVBlockDescriptor_BsDiag_ErrorRecord: start-on-event=SetRamBlockStatus, operation=PS_NvBlockSwComponentTypeNVBlockDescriptor_BsDiag_ErrorRecord.SetRamBlockStatus
        OpEventSetRamBlockStatus_SetRamBlockStatus_PS_NvBlockSwComponentTypeNVBlockDescriptor_BsReten_Audio: start-on-event=SetRamBlockStatus, operation=PS_NvBlockSwComponentTypeNVBlockDescriptor_BsReten_Audio.SetRamBlockStatus
        OpEventSetRamBlockStatus_SetRamBlockStatus_PS_NvBlockSwComponentTypeNVBlockDescriptor_BsReten_Communication: start-on-event=SetRamBlockStatus, operation=PS_NvBlockSwComponentTypeNVBlockDescriptor_BsReten_Communication.SetRamBlockStatus
        OpEventSetRamBlockStatus_SetRamBlockStatus_PS_NvBlockSwComponentTypeNVBlockDescriptor_BsReten_Display: start-on-event=SetRamBlockStatus, operation=PS_NvBlockSwComponentTypeNVBlockDescriptor_BsReten_Display.SetRamBlockStatus
        OpEventSetRamBlockStatus_SetRamBlockStatus_PS_NvBlockSwComponentTypeNVBlockDescriptor_BsReten_Gauges: start-on-event=SetRamBlockStatus, operation=PS_NvBlockSwComponentTypeNVBlockDescriptor_BsReten_Gauges.SetRamBlockStatus
        OpEventSetRamBlockStatus_SetRamBlockStatus_PS_NvBlockSwComponentTypeNVBlockDescriptor_BsReten_Illumination: start-on-event=SetRamBlockStatus, operation=PS_NvBlockSwComponentTypeNVBlockDescriptor_BsReten_Illumination.SetRamBlockStatus
        OpEventSetRamBlockStatus_SetRamBlockStatus_PS_NvBlockSwComponentTypeNVBlockDescriptor_BsReten_Odometer: start-on-event=SetRamBlockStatus, operation=PS_NvBlockSwComponentTypeNVBlockDescriptor_BsReten_Odometer.SetRamBlockStatus
        OpEventSetRamBlockStatus_SetRamBlockStatus_PS_NvBlockSwComponentTypeNVBlockDescriptor_BsReten_Personalization: start-on-event=SetRamBlockStatus, operation=PS_NvBlockSwComponentTypeNVBlockDescriptor_BsReten_Personalization.SetRamBlockStatus
        OpEventSetRamBlockStatus_SetRamBlockStatus_PS_NvBlockSwComponentTypeNVBlockDescriptor_BsReten_Power: start-on-event=SetRamBlockStatus, operation=PS_NvBlockSwComponentTypeNVBlockDescriptor_BsReten_Power.SetRamBlockStatus
        OpEventSetRamBlockStatus_SetRamBlockStatus_PS_NvBlockSwComponentTypeNVBlockDescriptor_BsReten_RealTimeClock: start-on-event=SetRamBlockStatus, operation=PS_NvBlockSwComponentTypeNVBlockDescriptor_BsReten_RealTimeClock.SetRamBlockStatus
        OpEventSetRamBlockStatus_SetRamBlockStatus_PS_NvBlockSwComponentTypeNVBlockDescriptor_BsReten_Tripcomputer: start-on-event=SetRamBlockStatus, operation=PS_NvBlockSwComponentTypeNVBlockDescriptor_BsReten_Tripcomputer.SetRamBlockStatus
        OpEventSetRamBlockStatus_SetRamBlockStatus_PS_NvBlockSwComponentTypeNVBlockDescriptor_BsReten_Warning: start-on-event=SetRamBlockStatus, operation=PS_NvBlockSwComponentTypeNVBlockDescriptor_BsReten_Warning.SetRamBlockStatus
        OpEventSetRamBlockStatus_SetRamBlockStatus_PS_NvBlockSwComponentTypeNVBlockDescriptor_BsRt_CusDlt: start-on-event=SetRamBlockStatus, operation=PS_NvBlockSwComponentTypeNVBlockDescriptor_BsRt_CusDlt.SetRamBlockStatus
        OpEventSetRamBlockStatus_SetRamBlockStatus_PS_NvBlockSwComponentTypeNVBlockDescriptor_BsRt_FuelGauge: start-on-event=SetRamBlockStatus, operation=PS_NvBlockSwComponentTypeNVBlockDescriptor_BsRt_FuelGauge.SetRamBlockStatus
        OpEventSetRamBlockStatus_SetRamBlockStatus_PS_NvBlockSwComponentTypeNVBlockDescriptor_BsRt_Illumination: start-on-event=SetRamBlockStatus, operation=PS_NvBlockSwComponentTypeNVBlockDescriptor_BsRt_Illumination.SetRamBlockStatus
        OpEventSetRamBlockStatus_SetRamBlockStatus_PS_NvBlockSwComponentTypeNVBlockDescriptor_BsRt_Odometer: start-on-event=SetRamBlockStatus, operation=PS_NvBlockSwComponentTypeNVBlockDescriptor_BsRt_Odometer.SetRamBlockStatus
        OpEventSetRamBlockStatus_SetRamBlockStatus_PS_NvBlockSwComponentTypeNVBlockDescriptor_BsRt_OilGauge: start-on-event=SetRamBlockStatus, operation=PS_NvBlockSwComponentTypeNVBlockDescriptor_BsRt_OilGauge.SetRamBlockStatus
        OpEventSetRamBlockStatus_SetRamBlockStatus_PS_NvBlockSwComponentTypeNVBlockDescriptor_BsRt_Personalization: start-on-event=SetRamBlockStatus, operation=PS_NvBlockSwComponentTypeNVBlockDescriptor_BsRt_Personalization.SetRamBlockStatus
        OpEventSetRamBlockStatus_SetRamBlockStatus_PS_NvBlockSwComponentTypeNVBlockDescriptor_BsRt_PowerGauge: start-on-event=SetRamBlockStatus, operation=PS_NvBlockSwComponentTypeNVBlockDescriptor_BsRt_PowerGauge.SetRamBlockStatus
        OpEventSetRamBlockStatus_SetRamBlockStatus_PS_NvBlockSwComponentTypeNVBlockDescriptor_BsRt_RealTimeClock: start-on-event=SetRamBlockStatus, operation=PS_NvBlockSwComponentTypeNVBlockDescriptor_BsRt_RealTimeClock.SetRamBlockStatus
        OpEventSetRamBlockStatus_SetRamBlockStatus_PS_NvBlockSwComponentTypeNVBlockDescriptor_BsRt_SpeedoGauge: start-on-event=SetRamBlockStatus, operation=PS_NvBlockSwComponentTypeNVBlockDescriptor_BsRt_SpeedoGauge.SetRamBlockStatus
        OpEventSetRamBlockStatus_SetRamBlockStatus_PS_NvBlockSwComponentTypeNVBlockDescriptor_BsRt_TachoGauge: start-on-event=SetRamBlockStatus, operation=PS_NvBlockSwComponentTypeNVBlockDescriptor_BsRt_TachoGauge.SetRamBlockStatus
        OpEventSetRamBlockStatus_SetRamBlockStatus_PS_NvBlockSwComponentTypeNVBlockDescriptor_BsRt_TempGauge: start-on-event=SetRamBlockStatus, operation=PS_NvBlockSwComponentTypeNVBlockDescriptor_BsRt_TempGauge.SetRamBlockStatus
        OpEventSetRamBlockStatus_SetRamBlockStatus_PS_NvBlockSwComponentTypeNVBlockDescriptor_BsRt_TripComputer: start-on-event=SetRamBlockStatus, operation=PS_NvBlockSwComponentTypeNVBlockDescriptor_BsRt_TripComputer.SetRamBlockStatus
        OpEventSetRamBlockStatus_SetRamBlockStatus_PS_NvBlockSwComponentTypeNVBlockDescriptor_BsRt_Warning: start-on-event=SetRamBlockStatus, operation=PS_NvBlockSwComponentTypeNVBlockDescriptor_BsRt_Warning.SetRamBlockStatus
        OpEventSetRamBlockStatus_SetRamBlockStatus_PS_NvBlockSwComponentTypeNVBlockDescriptor_BsShare_EcuPartNumber: start-on-event=SetRamBlockStatus, operation=PS_NvBlockSwComponentTypeNVBlockDescriptor_BsShare_EcuPartNumber.SetRamBlockStatus
        OpEventSetRamBlockStatus_SetRamBlockStatus_PS_NvBlockSwComponentTypeNVBlockDescriptor_BsShare_SwUpdFotaFinPrint: start-on-event=SetRamBlockStatus, operation=PS_NvBlockSwComponentTypeNVBlockDescriptor_BsShare_SwUpdFotaFinPrint.SetRamBlockStatus
        OpEventSetRamBlockStatus_SetRamBlockStatus_PS_NvBlockSwComponentTypeNVBlockDescriptor_BsShare_SwUpdFotaMode: start-on-event=SetRamBlockStatus, operation=PS_NvBlockSwComponentTypeNVBlockDescriptor_BsShare_SwUpdFotaMode.SetRamBlockStatus
        OpEventSetRamBlockStatus_SetRamBlockStatus_PS_NvBlockSwComponentTypeNVBlockDescriptor_BsShare_SwUpdFotaStatus: start-on-event=SetRamBlockStatus, operation=PS_NvBlockSwComponentTypeNVBlockDescriptor_BsShare_SwUpdFotaStatus.SetRamBlockStatus
        OpEventSetRamBlockStatus_SetRamBlockStatus_PS_NvBlockSwComponentTypeNVBlockDescriptor_BsShare_SwUpdFotadecrypt: start-on-event=SetRamBlockStatus, operation=PS_NvBlockSwComponentTypeNVBlockDescriptor_BsShare_SwUpdFotadecrypt.SetRamBlockStatus
        OpEventSetRamBlockStatus_SetRamBlockStatus_PS_NvBlockSwComponentTypeNVBlockDescriptor_BsShare_SwUpdReflash: start-on-event=SetRamBlockStatus, operation=PS_NvBlockSwComponentTypeNVBlockDescriptor_BsShare_SwUpdReflash.SetRamBlockStatus
        OpEventSetRamBlockStatus_SetRamBlockStatus_PS_NvBlockSwComponentTypeNVBlockDescriptor_BsShare_VehicleConfig: start-on-event=SetRamBlockStatus, operation=PS_NvBlockSwComponentTypeNVBlockDescriptor_BsShare_VehicleConfig.SetRamBlockStatus
        OpEventSetRamBlockStatus_SetRamBlockStatus_PS_NvBlockSwComponentTypeNVBlockDescriptor_BsShare_VisMeet: start-on-event=SetRamBlockStatus, operation=PS_NvBlockSwComponentTypeNVBlockDescriptor_BsShare_VisMeet.SetRamBlockStatus
        OpEventSetRamBlockStatus_SetRamBlockStatus_PS_NvBlockSwComponentTypeNVBlockDescriptor_RefCys_Certicificate: start-on-event=SetRamBlockStatus, operation=PS_NvBlockSwComponentTypeNVBlockDescriptor_RefCys_Certicificate.SetRamBlockStatus
        OpEventSetRamBlockStatus_SetRamBlockStatus_PS_NvBlockSwComponentTypeNVBlockDescriptor_RefCys_Certicificate1: start-on-event=SetRamBlockStatus, operation=PS_NvBlockSwComponentTypeNVBlockDescriptor_RefCys_Certicificate1.SetRamBlockStatus
        OpEventReadBlock_ReadBlock_PS_NvBlockSwComponentTypeNVBlockDescriptor_BsConst_Audio: start-on-event=ReadBlock, operation=PS_NvBlockSwComponentTypeNVBlockDescriptor_BsConst_Audio.ReadBlock
        OpEventReadBlock_ReadBlock_PS_NvBlockSwComponentTypeNVBlockDescriptor_BsConst_Communication: start-on-event=ReadBlock, operation=PS_NvBlockSwComponentTypeNVBlockDescriptor_BsConst_Communication.ReadBlock
        OpEventReadBlock_ReadBlock_PS_NvBlockSwComponentTypeNVBlockDescriptor_BsConst_EngOffTimer: start-on-event=ReadBlock, operation=PS_NvBlockSwComponentTypeNVBlockDescriptor_BsConst_EngOffTimer.ReadBlock
        OpEventReadBlock_ReadBlock_PS_NvBlockSwComponentTypeNVBlockDescriptor_BsConst_FuelGauge: start-on-event=ReadBlock, operation=PS_NvBlockSwComponentTypeNVBlockDescriptor_BsConst_FuelGauge.ReadBlock
        OpEventReadBlock_ReadBlock_PS_NvBlockSwComponentTypeNVBlockDescriptor_BsConst_OilGauge: start-on-event=ReadBlock, operation=PS_NvBlockSwComponentTypeNVBlockDescriptor_BsConst_OilGauge.ReadBlock
        OpEventReadBlock_ReadBlock_PS_NvBlockSwComponentTypeNVBlockDescriptor_BsConst_Power: start-on-event=ReadBlock, operation=PS_NvBlockSwComponentTypeNVBlockDescriptor_BsConst_Power.ReadBlock
        OpEventReadBlock_ReadBlock_PS_NvBlockSwComponentTypeNVBlockDescriptor_BsConst_PowerGauge: start-on-event=ReadBlock, operation=PS_NvBlockSwComponentTypeNVBlockDescriptor_BsConst_PowerGauge.ReadBlock
        OpEventReadBlock_ReadBlock_PS_NvBlockSwComponentTypeNVBlockDescriptor_BsConst_RealTimeClock: start-on-event=ReadBlock, operation=PS_NvBlockSwComponentTypeNVBlockDescriptor_BsConst_RealTimeClock.ReadBlock
        OpEventReadBlock_ReadBlock_PS_NvBlockSwComponentTypeNVBlockDescriptor_BsConst_ServiceReminder: start-on-event=ReadBlock, operation=PS_NvBlockSwComponentTypeNVBlockDescriptor_BsConst_ServiceReminder.ReadBlock
        OpEventReadBlock_ReadBlock_PS_NvBlockSwComponentTypeNVBlockDescriptor_BsConst_SpeedoGauge: start-on-event=ReadBlock, operation=PS_NvBlockSwComponentTypeNVBlockDescriptor_BsConst_SpeedoGauge.ReadBlock
        OpEventReadBlock_ReadBlock_PS_NvBlockSwComponentTypeNVBlockDescriptor_BsConst_TachoGauge: start-on-event=ReadBlock, operation=PS_NvBlockSwComponentTypeNVBlockDescriptor_BsConst_TachoGauge.ReadBlock
        OpEventReadBlock_ReadBlock_PS_NvBlockSwComponentTypeNVBlockDescriptor_BsConst_TempGauge: start-on-event=ReadBlock, operation=PS_NvBlockSwComponentTypeNVBlockDescriptor_BsConst_TempGauge.ReadBlock
        OpEventReadBlock_ReadBlock_PS_NvBlockSwComponentTypeNVBlockDescriptor_BsConst_TripComputer: start-on-event=ReadBlock, operation=PS_NvBlockSwComponentTypeNVBlockDescriptor_BsConst_TripComputer.ReadBlock
        OpEventReadBlock_ReadBlock_PS_NvBlockSwComponentTypeNVBlockDescriptor_BsConst_Warning: start-on-event=ReadBlock, operation=PS_NvBlockSwComponentTypeNVBlockDescriptor_BsConst_Warning.ReadBlock
        OpEventReadBlock_ReadBlock_PS_NvBlockSwComponentTypeNVBlockDescriptor_BsCys_Certicificate: start-on-event=ReadBlock, operation=PS_NvBlockSwComponentTypeNVBlockDescriptor_BsCys_Certicificate.ReadBlock
        OpEventReadBlock_ReadBlock_PS_NvBlockSwComponentTypeNVBlockDescriptor_BsDiag_Dtc: start-on-event=ReadBlock, operation=PS_NvBlockSwComponentTypeNVBlockDescriptor_BsDiag_Dtc.ReadBlock
        OpEventReadBlock_ReadBlock_PS_NvBlockSwComponentTypeNVBlockDescriptor_BsDiag_ErrorRecord: start-on-event=ReadBlock, operation=PS_NvBlockSwComponentTypeNVBlockDescriptor_BsDiag_ErrorRecord.ReadBlock
        OpEventReadBlock_ReadBlock_PS_NvBlockSwComponentTypeNVBlockDescriptor_BsReten_Audio: start-on-event=ReadBlock, operation=PS_NvBlockSwComponentTypeNVBlockDescriptor_BsReten_Audio.ReadBlock
        OpEventReadBlock_ReadBlock_PS_NvBlockSwComponentTypeNVBlockDescriptor_BsReten_Communication: start-on-event=ReadBlock, operation=PS_NvBlockSwComponentTypeNVBlockDescriptor_BsReten_Communication.ReadBlock
        OpEventReadBlock_ReadBlock_PS_NvBlockSwComponentTypeNVBlockDescriptor_BsReten_Display: start-on-event=ReadBlock, operation=PS_NvBlockSwComponentTypeNVBlockDescriptor_BsReten_Display.ReadBlock
        OpEventReadBlock_ReadBlock_PS_NvBlockSwComponentTypeNVBlockDescriptor_BsReten_Gauges: start-on-event=ReadBlock, operation=PS_NvBlockSwComponentTypeNVBlockDescriptor_BsReten_Gauges.ReadBlock
        OpEventReadBlock_ReadBlock_PS_NvBlockSwComponentTypeNVBlockDescriptor_BsReten_Illumination: start-on-event=ReadBlock, operation=PS_NvBlockSwComponentTypeNVBlockDescriptor_BsReten_Illumination.ReadBlock
        OpEventReadBlock_ReadBlock_PS_NvBlockSwComponentTypeNVBlockDescriptor_BsReten_Odometer: start-on-event=ReadBlock, operation=PS_NvBlockSwComponentTypeNVBlockDescriptor_BsReten_Odometer.ReadBlock
        OpEventReadBlock_ReadBlock_PS_NvBlockSwComponentTypeNVBlockDescriptor_BsReten_Personalization: start-on-event=ReadBlock, operation=PS_NvBlockSwComponentTypeNVBlockDescriptor_BsReten_Personalization.ReadBlock
        OpEventReadBlock_ReadBlock_PS_NvBlockSwComponentTypeNVBlockDescriptor_BsReten_Power: start-on-event=ReadBlock, operation=PS_NvBlockSwComponentTypeNVBlockDescriptor_BsReten_Power.ReadBlock
        OpEventReadBlock_ReadBlock_PS_NvBlockSwComponentTypeNVBlockDescriptor_BsReten_RealTimeClock: start-on-event=ReadBlock, operation=PS_NvBlockSwComponentTypeNVBlockDescriptor_BsReten_RealTimeClock.ReadBlock
        OpEventReadBlock_ReadBlock_PS_NvBlockSwComponentTypeNVBlockDescriptor_BsReten_Tripcomputer: start-on-event=ReadBlock, operation=PS_NvBlockSwComponentTypeNVBlockDescriptor_BsReten_Tripcomputer.ReadBlock
        OpEventReadBlock_ReadBlock_PS_NvBlockSwComponentTypeNVBlockDescriptor_BsReten_Warning: start-on-event=ReadBlock, operation=PS_NvBlockSwComponentTypeNVBlockDescriptor_BsReten_Warning.ReadBlock
        OpEventReadBlock_ReadBlock_PS_NvBlockSwComponentTypeNVBlockDescriptor_BsRt_CusDlt: start-on-event=ReadBlock, operation=PS_NvBlockSwComponentTypeNVBlockDescriptor_BsRt_CusDlt.ReadBlock
        OpEventReadBlock_ReadBlock_PS_NvBlockSwComponentTypeNVBlockDescriptor_BsRt_FuelGauge: start-on-event=ReadBlock, operation=PS_NvBlockSwComponentTypeNVBlockDescriptor_BsRt_FuelGauge.ReadBlock
        OpEventReadBlock_ReadBlock_PS_NvBlockSwComponentTypeNVBlockDescriptor_BsRt_Illumination: start-on-event=ReadBlock, operation=PS_NvBlockSwComponentTypeNVBlockDescriptor_BsRt_Illumination.ReadBlock
        OpEventReadBlock_ReadBlock_PS_NvBlockSwComponentTypeNVBlockDescriptor_BsRt_Odometer: start-on-event=ReadBlock, operation=PS_NvBlockSwComponentTypeNVBlockDescriptor_BsRt_Odometer.ReadBlock
        OpEventReadBlock_ReadBlock_PS_NvBlockSwComponentTypeNVBlockDescriptor_BsRt_OilGauge: start-on-event=ReadBlock, operation=PS_NvBlockSwComponentTypeNVBlockDescriptor_BsRt_OilGauge.ReadBlock
        OpEventReadBlock_ReadBlock_PS_NvBlockSwComponentTypeNVBlockDescriptor_BsRt_Personalization: start-on-event=ReadBlock, operation=PS_NvBlockSwComponentTypeNVBlockDescriptor_BsRt_Personalization.ReadBlock
        OpEventReadBlock_ReadBlock_PS_NvBlockSwComponentTypeNVBlockDescriptor_BsRt_PowerGauge: start-on-event=ReadBlock, operation=PS_NvBlockSwComponentTypeNVBlockDescriptor_BsRt_PowerGauge.ReadBlock
        OpEventReadBlock_ReadBlock_PS_NvBlockSwComponentTypeNVBlockDescriptor_BsRt_RealTimeClock: start-on-event=ReadBlock, operation=PS_NvBlockSwComponentTypeNVBlockDescriptor_BsRt_RealTimeClock.ReadBlock
        OpEventReadBlock_ReadBlock_PS_NvBlockSwComponentTypeNVBlockDescriptor_BsRt_SpeedoGauge: start-on-event=ReadBlock, operation=PS_NvBlockSwComponentTypeNVBlockDescriptor_BsRt_SpeedoGauge.ReadBlock
        OpEventReadBlock_ReadBlock_PS_NvBlockSwComponentTypeNVBlockDescriptor_BsRt_TachoGauge: start-on-event=ReadBlock, operation=PS_NvBlockSwComponentTypeNVBlockDescriptor_BsRt_TachoGauge.ReadBlock
        OpEventReadBlock_ReadBlock_PS_NvBlockSwComponentTypeNVBlockDescriptor_BsRt_TempGauge: start-on-event=ReadBlock, operation=PS_NvBlockSwComponentTypeNVBlockDescriptor_BsRt_TempGauge.ReadBlock
        OpEventReadBlock_ReadBlock_PS_NvBlockSwComponentTypeNVBlockDescriptor_BsRt_TripComputer: start-on-event=ReadBlock, operation=PS_NvBlockSwComponentTypeNVBlockDescriptor_BsRt_TripComputer.ReadBlock
        OpEventReadBlock_ReadBlock_PS_NvBlockSwComponentTypeNVBlockDescriptor_BsRt_Warning: start-on-event=ReadBlock, operation=PS_NvBlockSwComponentTypeNVBlockDescriptor_BsRt_Warning.ReadBlock
        OpEventReadBlock_ReadBlock_PS_NvBlockSwComponentTypeNVBlockDescriptor_BsShare_EcuPartNumber: start-on-event=ReadBlock, operation=PS_NvBlockSwComponentTypeNVBlockDescriptor_BsShare_EcuPartNumber.ReadBlock
        OpEventReadBlock_ReadBlock_PS_NvBlockSwComponentTypeNVBlockDescriptor_BsShare_SwUpdFotaFinPrint: start-on-event=ReadBlock, operation=PS_NvBlockSwComponentTypeNVBlockDescriptor_BsShare_SwUpdFotaFinPrint.ReadBlock
        OpEventReadBlock_ReadBlock_PS_NvBlockSwComponentTypeNVBlockDescriptor_BsShare_SwUpdFotaMode: start-on-event=ReadBlock, operation=PS_NvBlockSwComponentTypeNVBlockDescriptor_BsShare_SwUpdFotaMode.ReadBlock
        OpEventReadBlock_ReadBlock_PS_NvBlockSwComponentTypeNVBlockDescriptor_BsShare_SwUpdFotaStatus: start-on-event=ReadBlock, operation=PS_NvBlockSwComponentTypeNVBlockDescriptor_BsShare_SwUpdFotaStatus.ReadBlock
        OpEventReadBlock_ReadBlock_PS_NvBlockSwComponentTypeNVBlockDescriptor_BsShare_SwUpdFotadecrypt: start-on-event=ReadBlock, operation=PS_NvBlockSwComponentTypeNVBlockDescriptor_BsShare_SwUpdFotadecrypt.ReadBlock
        OpEventReadBlock_ReadBlock_PS_NvBlockSwComponentTypeNVBlockDescriptor_BsShare_SwUpdReflash: start-on-event=ReadBlock, operation=PS_NvBlockSwComponentTypeNVBlockDescriptor_BsShare_SwUpdReflash.ReadBlock
        OpEventReadBlock_ReadBlock_PS_NvBlockSwComponentTypeNVBlockDescriptor_BsShare_VehicleConfig: start-on-event=ReadBlock, operation=PS_NvBlockSwComponentTypeNVBlockDescriptor_BsShare_VehicleConfig.ReadBlock
        OpEventReadBlock_ReadBlock_PS_NvBlockSwComponentTypeNVBlockDescriptor_BsShare_VisMeet: start-on-event=ReadBlock, operation=PS_NvBlockSwComponentTypeNVBlockDescriptor_BsShare_VisMeet.ReadBlock
        OpEventReadBlock_ReadBlock_PS_NvBlockSwComponentTypeNVBlockDescriptor_RefCys_Certicificate: start-on-event=ReadBlock, operation=PS_NvBlockSwComponentTypeNVBlockDescriptor_RefCys_Certicificate.ReadBlock
        OpEventReadBlock_ReadBlock_PS_NvBlockSwComponentTypeNVBlockDescriptor_RefCys_Certicificate1: start-on-event=ReadBlock, operation=PS_NvBlockSwComponentTypeNVBlockDescriptor_RefCys_Certicificate1.ReadBlock
        OpEventWriteBlock_WriteBlock_PS_NvBlockSwComponentTypeNVBlockDescriptor_BsConst_Audio: start-on-event=WriteBlock, operation=PS_NvBlockSwComponentTypeNVBlockDescriptor_BsConst_Audio.WriteBlock
        OpEventWriteBlock_WriteBlock_PS_NvBlockSwComponentTypeNVBlockDescriptor_BsConst_Communication: start-on-event=WriteBlock, operation=PS_NvBlockSwComponentTypeNVBlockDescriptor_BsConst_Communication.WriteBlock
        OpEventWriteBlock_WriteBlock_PS_NvBlockSwComponentTypeNVBlockDescriptor_BsConst_EngOffTimer: start-on-event=WriteBlock, operation=PS_NvBlockSwComponentTypeNVBlockDescriptor_BsConst_EngOffTimer.WriteBlock
        OpEventWriteBlock_WriteBlock_PS_NvBlockSwComponentTypeNVBlockDescriptor_BsConst_FuelGauge: start-on-event=WriteBlock, operation=PS_NvBlockSwComponentTypeNVBlockDescriptor_BsConst_FuelGauge.WriteBlock
        OpEventWriteBlock_WriteBlock_PS_NvBlockSwComponentTypeNVBlockDescriptor_BsConst_OilGauge: start-on-event=WriteBlock, operation=PS_NvBlockSwComponentTypeNVBlockDescriptor_BsConst_OilGauge.WriteBlock
        OpEventWriteBlock_WriteBlock_PS_NvBlockSwComponentTypeNVBlockDescriptor_BsConst_Power: start-on-event=WriteBlock, operation=PS_NvBlockSwComponentTypeNVBlockDescriptor_BsConst_Power.WriteBlock
        OpEventWriteBlock_WriteBlock_PS_NvBlockSwComponentTypeNVBlockDescriptor_BsConst_PowerGauge: start-on-event=WriteBlock, operation=PS_NvBlockSwComponentTypeNVBlockDescriptor_BsConst_PowerGauge.WriteBlock
        OpEventWriteBlock_WriteBlock_PS_NvBlockSwComponentTypeNVBlockDescriptor_BsConst_RealTimeClock: start-on-event=WriteBlock, operation=PS_NvBlockSwComponentTypeNVBlockDescriptor_BsConst_RealTimeClock.WriteBlock
        OpEventWriteBlock_WriteBlock_PS_NvBlockSwComponentTypeNVBlockDescriptor_BsConst_ServiceReminder: start-on-event=WriteBlock, operation=PS_NvBlockSwComponentTypeNVBlockDescriptor_BsConst_ServiceReminder.WriteBlock
        OpEventWriteBlock_WriteBlock_PS_NvBlockSwComponentTypeNVBlockDescriptor_BsConst_SpeedoGauge: start-on-event=WriteBlock, operation=PS_NvBlockSwComponentTypeNVBlockDescriptor_BsConst_SpeedoGauge.WriteBlock
        OpEventWriteBlock_WriteBlock_PS_NvBlockSwComponentTypeNVBlockDescriptor_BsConst_TachoGauge: start-on-event=WriteBlock, operation=PS_NvBlockSwComponentTypeNVBlockDescriptor_BsConst_TachoGauge.WriteBlock
        OpEventWriteBlock_WriteBlock_PS_NvBlockSwComponentTypeNVBlockDescriptor_BsConst_TempGauge: start-on-event=WriteBlock, operation=PS_NvBlockSwComponentTypeNVBlockDescriptor_BsConst_TempGauge.WriteBlock
        OpEventWriteBlock_WriteBlock_PS_NvBlockSwComponentTypeNVBlockDescriptor_BsConst_TripComputer: start-on-event=WriteBlock, operation=PS_NvBlockSwComponentTypeNVBlockDescriptor_BsConst_TripComputer.WriteBlock
        OpEventWriteBlock_WriteBlock_PS_NvBlockSwComponentTypeNVBlockDescriptor_BsConst_Warning: start-on-event=WriteBlock, operation=PS_NvBlockSwComponentTypeNVBlockDescriptor_BsConst_Warning.WriteBlock
        OpEventWriteBlock_WriteBlock_PS_NvBlockSwComponentTypeNVBlockDescriptor_BsCys_Certicificate: start-on-event=WriteBlock, operation=PS_NvBlockSwComponentTypeNVBlockDescriptor_BsCys_Certicificate.WriteBlock
        OpEventWriteBlock_WriteBlock_PS_NvBlockSwComponentTypeNVBlockDescriptor_BsDiag_Dtc: start-on-event=WriteBlock, operation=PS_NvBlockSwComponentTypeNVBlockDescriptor_BsDiag_Dtc.WriteBlock
        OpEventWriteBlock_WriteBlock_PS_NvBlockSwComponentTypeNVBlockDescriptor_BsDiag_ErrorRecord: start-on-event=WriteBlock, operation=PS_NvBlockSwComponentTypeNVBlockDescriptor_BsDiag_ErrorRecord.WriteBlock
        OpEventWriteBlock_WriteBlock_PS_NvBlockSwComponentTypeNVBlockDescriptor_BsReten_Audio: start-on-event=WriteBlock, operation=PS_NvBlockSwComponentTypeNVBlockDescriptor_BsReten_Audio.WriteBlock
        OpEventWriteBlock_WriteBlock_PS_NvBlockSwComponentTypeNVBlockDescriptor_BsReten_Communication: start-on-event=WriteBlock, operation=PS_NvBlockSwComponentTypeNVBlockDescriptor_BsReten_Communication.WriteBlock
        OpEventWriteBlock_WriteBlock_PS_NvBlockSwComponentTypeNVBlockDescriptor_BsReten_Display: start-on-event=WriteBlock, operation=PS_NvBlockSwComponentTypeNVBlockDescriptor_BsReten_Display.WriteBlock
        OpEventWriteBlock_WriteBlock_PS_NvBlockSwComponentTypeNVBlockDescriptor_BsReten_Gauges: start-on-event=WriteBlock, operation=PS_NvBlockSwComponentTypeNVBlockDescriptor_BsReten_Gauges.WriteBlock
        OpEventWriteBlock_WriteBlock_PS_NvBlockSwComponentTypeNVBlockDescriptor_BsReten_Illumination: start-on-event=WriteBlock, operation=PS_NvBlockSwComponentTypeNVBlockDescriptor_BsReten_Illumination.WriteBlock
        OpEventWriteBlock_WriteBlock_PS_NvBlockSwComponentTypeNVBlockDescriptor_BsReten_Odometer: start-on-event=WriteBlock, operation=PS_NvBlockSwComponentTypeNVBlockDescriptor_BsReten_Odometer.WriteBlock
        OpEventWriteBlock_WriteBlock_PS_NvBlockSwComponentTypeNVBlockDescriptor_BsReten_Personalization: start-on-event=WriteBlock, operation=PS_NvBlockSwComponentTypeNVBlockDescriptor_BsReten_Personalization.WriteBlock
        OpEventWriteBlock_WriteBlock_PS_NvBlockSwComponentTypeNVBlockDescriptor_BsReten_Power: start-on-event=WriteBlock, operation=PS_NvBlockSwComponentTypeNVBlockDescriptor_BsReten_Power.WriteBlock
        OpEventWriteBlock_WriteBlock_PS_NvBlockSwComponentTypeNVBlockDescriptor_BsReten_RealTimeClock: start-on-event=WriteBlock, operation=PS_NvBlockSwComponentTypeNVBlockDescriptor_BsReten_RealTimeClock.WriteBlock
        OpEventWriteBlock_WriteBlock_PS_NvBlockSwComponentTypeNVBlockDescriptor_BsReten_Tripcomputer: start-on-event=WriteBlock, operation=PS_NvBlockSwComponentTypeNVBlockDescriptor_BsReten_Tripcomputer.WriteBlock
        OpEventWriteBlock_WriteBlock_PS_NvBlockSwComponentTypeNVBlockDescriptor_BsReten_Warning: start-on-event=WriteBlock, operation=PS_NvBlockSwComponentTypeNVBlockDescriptor_BsReten_Warning.WriteBlock
        OpEventWriteBlock_WriteBlock_PS_NvBlockSwComponentTypeNVBlockDescriptor_BsRt_CusDlt: start-on-event=WriteBlock, operation=PS_NvBlockSwComponentTypeNVBlockDescriptor_BsRt_CusDlt.WriteBlock
        OpEventWriteBlock_WriteBlock_PS_NvBlockSwComponentTypeNVBlockDescriptor_BsRt_FuelGauge: start-on-event=WriteBlock, operation=PS_NvBlockSwComponentTypeNVBlockDescriptor_BsRt_FuelGauge.WriteBlock
        OpEventWriteBlock_WriteBlock_PS_NvBlockSwComponentTypeNVBlockDescriptor_BsRt_Illumination: start-on-event=WriteBlock, operation=PS_NvBlockSwComponentTypeNVBlockDescriptor_BsRt_Illumination.WriteBlock
        OpEventWriteBlock_WriteBlock_PS_NvBlockSwComponentTypeNVBlockDescriptor_BsRt_Odometer: start-on-event=WriteBlock, operation=PS_NvBlockSwComponentTypeNVBlockDescriptor_BsRt_Odometer.WriteBlock
        OpEventWriteBlock_WriteBlock_PS_NvBlockSwComponentTypeNVBlockDescriptor_BsRt_OilGauge: start-on-event=WriteBlock, operation=PS_NvBlockSwComponentTypeNVBlockDescriptor_BsRt_OilGauge.WriteBlock
        OpEventWriteBlock_WriteBlock_PS_NvBlockSwComponentTypeNVBlockDescriptor_BsRt_Personalization: start-on-event=WriteBlock, operation=PS_NvBlockSwComponentTypeNVBlockDescriptor_BsRt_Personalization.WriteBlock
        OpEventWriteBlock_WriteBlock_PS_NvBlockSwComponentTypeNVBlockDescriptor_BsRt_PowerGauge: start-on-event=WriteBlock, operation=PS_NvBlockSwComponentTypeNVBlockDescriptor_BsRt_PowerGauge.WriteBlock
        OpEventWriteBlock_WriteBlock_PS_NvBlockSwComponentTypeNVBlockDescriptor_BsRt_RealTimeClock: start-on-event=WriteBlock, operation=PS_NvBlockSwComponentTypeNVBlockDescriptor_BsRt_RealTimeClock.WriteBlock
        OpEventWriteBlock_WriteBlock_PS_NvBlockSwComponentTypeNVBlockDescriptor_BsRt_SpeedoGauge: start-on-event=WriteBlock, operation=PS_NvBlockSwComponentTypeNVBlockDescriptor_BsRt_SpeedoGauge.WriteBlock
        OpEventWriteBlock_WriteBlock_PS_NvBlockSwComponentTypeNVBlockDescriptor_BsRt_TachoGauge: start-on-event=WriteBlock, operation=PS_NvBlockSwComponentTypeNVBlockDescriptor_BsRt_TachoGauge.WriteBlock
        OpEventWriteBlock_WriteBlock_PS_NvBlockSwComponentTypeNVBlockDescriptor_BsRt_TempGauge: start-on-event=WriteBlock, operation=PS_NvBlockSwComponentTypeNVBlockDescriptor_BsRt_TempGauge.WriteBlock
        OpEventWriteBlock_WriteBlock_PS_NvBlockSwComponentTypeNVBlockDescriptor_BsRt_TripComputer: start-on-event=WriteBlock, operation=PS_NvBlockSwComponentTypeNVBlockDescriptor_BsRt_TripComputer.WriteBlock
        OpEventWriteBlock_WriteBlock_PS_NvBlockSwComponentTypeNVBlockDescriptor_BsRt_Warning: start-on-event=WriteBlock, operation=PS_NvBlockSwComponentTypeNVBlockDescriptor_BsRt_Warning.WriteBlock
        OpEventWriteBlock_WriteBlock_PS_NvBlockSwComponentTypeNVBlockDescriptor_BsShare_EcuPartNumber: start-on-event=WriteBlock, operation=PS_NvBlockSwComponentTypeNVBlockDescriptor_BsShare_EcuPartNumber.WriteBlock
        OpEventWriteBlock_WriteBlock_PS_NvBlockSwComponentTypeNVBlockDescriptor_BsShare_SwUpdFotaFinPrint: start-on-event=WriteBlock, operation=PS_NvBlockSwComponentTypeNVBlockDescriptor_BsShare_SwUpdFotaFinPrint.WriteBlock
        OpEventWriteBlock_WriteBlock_PS_NvBlockSwComponentTypeNVBlockDescriptor_BsShare_SwUpdFotaMode: start-on-event=WriteBlock, operation=PS_NvBlockSwComponentTypeNVBlockDescriptor_BsShare_SwUpdFotaMode.WriteBlock
        OpEventWriteBlock_WriteBlock_PS_NvBlockSwComponentTypeNVBlockDescriptor_BsShare_SwUpdFotaStatus: start-on-event=WriteBlock, operation=PS_NvBlockSwComponentTypeNVBlockDescriptor_BsShare_SwUpdFotaStatus.WriteBlock
        OpEventWriteBlock_WriteBlock_PS_NvBlockSwComponentTypeNVBlockDescriptor_BsShare_SwUpdFotadecrypt: start-on-event=WriteBlock, operation=PS_NvBlockSwComponentTypeNVBlockDescriptor_BsShare_SwUpdFotadecrypt.WriteBlock
        OpEventWriteBlock_WriteBlock_PS_NvBlockSwComponentTypeNVBlockDescriptor_BsShare_SwUpdReflash: start-on-event=WriteBlock, operation=PS_NvBlockSwComponentTypeNVBlockDescriptor_BsShare_SwUpdReflash.WriteBlock
        OpEventWriteBlock_WriteBlock_PS_NvBlockSwComponentTypeNVBlockDescriptor_BsShare_VehicleConfig: start-on-event=WriteBlock, operation=PS_NvBlockSwComponentTypeNVBlockDescriptor_BsShare_VehicleConfig.WriteBlock
        OpEventWriteBlock_WriteBlock_PS_NvBlockSwComponentTypeNVBlockDescriptor_BsShare_VisMeet: start-on-event=WriteBlock, operation=PS_NvBlockSwComponentTypeNVBlockDescriptor_BsShare_VisMeet.WriteBlock
        OpEventWriteBlock_WriteBlock_PS_NvBlockSwComponentTypeNVBlockDescriptor_RefCys_Certicificate: start-on-event=WriteBlock, operation=PS_NvBlockSwComponentTypeNVBlockDescriptor_RefCys_Certicificate.WriteBlock
        OpEventWriteBlock_WriteBlock_PS_NvBlockSwComponentTypeNVBlockDescriptor_RefCys_Certicificate1: start-on-event=WriteBlock, operation=PS_NvBlockSwComponentTypeNVBlockDescriptor_RefCys_Certicificate1.WriteBlock
        OpEventRestoreBlockDefaults_RestoreBlockDefaults_PS_NvBlockSwComponentTypeNVBlockDescriptor_BsConst_Audio: start-on-event=RestoreBlockDefaults, operation=PS_NvBlockSwComponentTypeNVBlockDescriptor_BsConst_Audio.RestoreBlockDefaults
        OpEventRestoreBlockDefaults_RestoreBlockDefaults_PS_NvBlockSwComponentTypeNVBlockDescriptor_BsConst_Communication: start-on-event=RestoreBlockDefaults, operation=PS_NvBlockSwComponentTypeNVBlockDescriptor_BsConst_Communication.RestoreBlockDefaults
        OpEventRestoreBlockDefaults_RestoreBlockDefaults_PS_NvBlockSwComponentTypeNVBlockDescriptor_BsConst_EngOffTimer: start-on-event=RestoreBlockDefaults, operation=PS_NvBlockSwComponentTypeNVBlockDescriptor_BsConst_EngOffTimer.RestoreBlockDefaults
        OpEventRestoreBlockDefaults_RestoreBlockDefaults_PS_NvBlockSwComponentTypeNVBlockDescriptor_BsConst_FuelGauge: start-on-event=RestoreBlockDefaults, operation=PS_NvBlockSwComponentTypeNVBlockDescriptor_BsConst_FuelGauge.RestoreBlockDefaults
        OpEventRestoreBlockDefaults_RestoreBlockDefaults_PS_NvBlockSwComponentTypeNVBlockDescriptor_BsConst_OilGauge: start-on-event=RestoreBlockDefaults, operation=PS_NvBlockSwComponentTypeNVBlockDescriptor_BsConst_OilGauge.RestoreBlockDefaults
        OpEventRestoreBlockDefaults_RestoreBlockDefaults_PS_NvBlockSwComponentTypeNVBlockDescriptor_BsConst_Power: start-on-event=RestoreBlockDefaults, operation=PS_NvBlockSwComponentTypeNVBlockDescriptor_BsConst_Power.RestoreBlockDefaults
        OpEventRestoreBlockDefaults_RestoreBlockDefaults_PS_NvBlockSwComponentTypeNVBlockDescriptor_BsConst_PowerGauge: start-on-event=RestoreBlockDefaults, operation=PS_NvBlockSwComponentTypeNVBlockDescriptor_BsConst_PowerGauge.RestoreBlockDefaults
        OpEventRestoreBlockDefaults_RestoreBlockDefaults_PS_NvBlockSwComponentTypeNVBlockDescriptor_BsConst_RealTimeClock: start-on-event=RestoreBlockDefaults, operation=PS_NvBlockSwComponentTypeNVBlockDescriptor_BsConst_RealTimeClock.RestoreBlockDefaults
        OpEventRestoreBlockDefaults_RestoreBlockDefaults_PS_NvBlockSwComponentTypeNVBlockDescriptor_BsConst_ServiceReminder: start-on-event=RestoreBlockDefaults, operation=PS_NvBlockSwComponentTypeNVBlockDescriptor_BsConst_ServiceReminder.RestoreBlockDefaults
        OpEventRestoreBlockDefaults_RestoreBlockDefaults_PS_NvBlockSwComponentTypeNVBlockDescriptor_BsConst_SpeedoGauge: start-on-event=RestoreBlockDefaults, operation=PS_NvBlockSwComponentTypeNVBlockDescriptor_BsConst_SpeedoGauge.RestoreBlockDefaults
        OpEventRestoreBlockDefaults_RestoreBlockDefaults_PS_NvBlockSwComponentTypeNVBlockDescriptor_BsConst_TachoGauge: start-on-event=RestoreBlockDefaults, operation=PS_NvBlockSwComponentTypeNVBlockDescriptor_BsConst_TachoGauge.RestoreBlockDefaults
        OpEventRestoreBlockDefaults_RestoreBlockDefaults_PS_NvBlockSwComponentTypeNVBlockDescriptor_BsConst_TempGauge: start-on-event=RestoreBlockDefaults, operation=PS_NvBlockSwComponentTypeNVBlockDescriptor_BsConst_TempGauge.RestoreBlockDefaults
        OpEventRestoreBlockDefaults_RestoreBlockDefaults_PS_NvBlockSwComponentTypeNVBlockDescriptor_BsConst_TripComputer: start-on-event=RestoreBlockDefaults, operation=PS_NvBlockSwComponentTypeNVBlockDescriptor_BsConst_TripComputer.RestoreBlockDefaults
        OpEventRestoreBlockDefaults_RestoreBlockDefaults_PS_NvBlockSwComponentTypeNVBlockDescriptor_BsConst_Warning: start-on-event=RestoreBlockDefaults, operation=PS_NvBlockSwComponentTypeNVBlockDescriptor_BsConst_Warning.RestoreBlockDefaults
        OpEventRestoreBlockDefaults_RestoreBlockDefaults_PS_NvBlockSwComponentTypeNVBlockDescriptor_BsCys_Certicificate: start-on-event=RestoreBlockDefaults, operation=PS_NvBlockSwComponentTypeNVBlockDescriptor_BsCys_Certicificate.RestoreBlockDefaults
        OpEventRestoreBlockDefaults_RestoreBlockDefaults_PS_NvBlockSwComponentTypeNVBlockDescriptor_BsDiag_Dtc: start-on-event=RestoreBlockDefaults, operation=PS_NvBlockSwComponentTypeNVBlockDescriptor_BsDiag_Dtc.RestoreBlockDefaults
        OpEventRestoreBlockDefaults_RestoreBlockDefaults_PS_NvBlockSwComponentTypeNVBlockDescriptor_BsDiag_ErrorRecord: start-on-event=RestoreBlockDefaults, operation=PS_NvBlockSwComponentTypeNVBlockDescriptor_BsDiag_ErrorRecord.RestoreBlockDefaults
        OpEventRestoreBlockDefaults_RestoreBlockDefaults_PS_NvBlockSwComponentTypeNVBlockDescriptor_BsReten_Audio: start-on-event=RestoreBlockDefaults, operation=PS_NvBlockSwComponentTypeNVBlockDescriptor_BsReten_Audio.RestoreBlockDefaults
        OpEventRestoreBlockDefaults_RestoreBlockDefaults_PS_NvBlockSwComponentTypeNVBlockDescriptor_BsReten_Communication: start-on-event=RestoreBlockDefaults, operation=PS_NvBlockSwComponentTypeNVBlockDescriptor_BsReten_Communication.RestoreBlockDefaults
        OpEventRestoreBlockDefaults_RestoreBlockDefaults_PS_NvBlockSwComponentTypeNVBlockDescriptor_BsReten_Display: start-on-event=RestoreBlockDefaults, operation=PS_NvBlockSwComponentTypeNVBlockDescriptor_BsReten_Display.RestoreBlockDefaults
        OpEventRestoreBlockDefaults_RestoreBlockDefaults_PS_NvBlockSwComponentTypeNVBlockDescriptor_BsReten_Gauges: start-on-event=RestoreBlockDefaults, operation=PS_NvBlockSwComponentTypeNVBlockDescriptor_BsReten_Gauges.RestoreBlockDefaults
        OpEventRestoreBlockDefaults_RestoreBlockDefaults_PS_NvBlockSwComponentTypeNVBlockDescriptor_BsReten_Illumination: start-on-event=RestoreBlockDefaults, operation=PS_NvBlockSwComponentTypeNVBlockDescriptor_BsReten_Illumination.RestoreBlockDefaults
        OpEventRestoreBlockDefaults_RestoreBlockDefaults_PS_NvBlockSwComponentTypeNVBlockDescriptor_BsReten_Odometer: start-on-event=RestoreBlockDefaults, operation=PS_NvBlockSwComponentTypeNVBlockDescriptor_BsReten_Odometer.RestoreBlockDefaults
        OpEventRestoreBlockDefaults_RestoreBlockDefaults_PS_NvBlockSwComponentTypeNVBlockDescriptor_BsReten_Personalization: start-on-event=RestoreBlockDefaults, operation=PS_NvBlockSwComponentTypeNVBlockDescriptor_BsReten_Personalization.RestoreBlockDefaults
        OpEventRestoreBlockDefaults_RestoreBlockDefaults_PS_NvBlockSwComponentTypeNVBlockDescriptor_BsReten_Power: start-on-event=RestoreBlockDefaults, operation=PS_NvBlockSwComponentTypeNVBlockDescriptor_BsReten_Power.RestoreBlockDefaults
        OpEventRestoreBlockDefaults_RestoreBlockDefaults_PS_NvBlockSwComponentTypeNVBlockDescriptor_BsReten_RealTimeClock: start-on-event=RestoreBlockDefaults, operation=PS_NvBlockSwComponentTypeNVBlockDescriptor_BsReten_RealTimeClock.RestoreBlockDefaults
        OpEventRestoreBlockDefaults_RestoreBlockDefaults_PS_NvBlockSwComponentTypeNVBlockDescriptor_BsReten_Tripcomputer: start-on-event=RestoreBlockDefaults, operation=PS_NvBlockSwComponentTypeNVBlockDescriptor_BsReten_Tripcomputer.RestoreBlockDefaults
        OpEventRestoreBlockDefaults_RestoreBlockDefaults_PS_NvBlockSwComponentTypeNVBlockDescriptor_BsReten_Warning: start-on-event=RestoreBlockDefaults, operation=PS_NvBlockSwComponentTypeNVBlockDescriptor_BsReten_Warning.RestoreBlockDefaults
        OpEventRestoreBlockDefaults_RestoreBlockDefaults_PS_NvBlockSwComponentTypeNVBlockDescriptor_BsRt_CusDlt: start-on-event=RestoreBlockDefaults, operation=PS_NvBlockSwComponentTypeNVBlockDescriptor_BsRt_CusDlt.RestoreBlockDefaults
        OpEventRestoreBlockDefaults_RestoreBlockDefaults_PS_NvBlockSwComponentTypeNVBlockDescriptor_BsRt_FuelGauge: start-on-event=RestoreBlockDefaults, operation=PS_NvBlockSwComponentTypeNVBlockDescriptor_BsRt_FuelGauge.RestoreBlockDefaults
        OpEventRestoreBlockDefaults_RestoreBlockDefaults_PS_NvBlockSwComponentTypeNVBlockDescriptor_BsRt_Illumination: start-on-event=RestoreBlockDefaults, operation=PS_NvBlockSwComponentTypeNVBlockDescriptor_BsRt_Illumination.RestoreBlockDefaults
        OpEventRestoreBlockDefaults_RestoreBlockDefaults_PS_NvBlockSwComponentTypeNVBlockDescriptor_BsRt_Odometer: start-on-event=RestoreBlockDefaults, operation=PS_NvBlockSwComponentTypeNVBlockDescriptor_BsRt_Odometer.RestoreBlockDefaults
        OpEventRestoreBlockDefaults_RestoreBlockDefaults_PS_NvBlockSwComponentTypeNVBlockDescriptor_BsRt_OilGauge: start-on-event=RestoreBlockDefaults, operation=PS_NvBlockSwComponentTypeNVBlockDescriptor_BsRt_OilGauge.RestoreBlockDefaults
        OpEventRestoreBlockDefaults_RestoreBlockDefaults_PS_NvBlockSwComponentTypeNVBlockDescriptor_BsRt_Personalization: start-on-event=RestoreBlockDefaults, operation=PS_NvBlockSwComponentTypeNVBlockDescriptor_BsRt_Personalization.RestoreBlockDefaults
        OpEventRestoreBlockDefaults_RestoreBlockDefaults_PS_NvBlockSwComponentTypeNVBlockDescriptor_BsRt_PowerGauge: start-on-event=RestoreBlockDefaults, operation=PS_NvBlockSwComponentTypeNVBlockDescriptor_BsRt_PowerGauge.RestoreBlockDefaults
        OpEventRestoreBlockDefaults_RestoreBlockDefaults_PS_NvBlockSwComponentTypeNVBlockDescriptor_BsRt_RealTimeClock: start-on-event=RestoreBlockDefaults, operation=PS_NvBlockSwComponentTypeNVBlockDescriptor_BsRt_RealTimeClock.RestoreBlockDefaults
        OpEventRestoreBlockDefaults_RestoreBlockDefaults_PS_NvBlockSwComponentTypeNVBlockDescriptor_BsRt_SpeedoGauge: start-on-event=RestoreBlockDefaults, operation=PS_NvBlockSwComponentTypeNVBlockDescriptor_BsRt_SpeedoGauge.RestoreBlockDefaults
        OpEventRestoreBlockDefaults_RestoreBlockDefaults_PS_NvBlockSwComponentTypeNVBlockDescriptor_BsRt_TachoGauge: start-on-event=RestoreBlockDefaults, operation=PS_NvBlockSwComponentTypeNVBlockDescriptor_BsRt_TachoGauge.RestoreBlockDefaults
        OpEventRestoreBlockDefaults_RestoreBlockDefaults_PS_NvBlockSwComponentTypeNVBlockDescriptor_BsRt_TempGauge: start-on-event=RestoreBlockDefaults, operation=PS_NvBlockSwComponentTypeNVBlockDescriptor_BsRt_TempGauge.RestoreBlockDefaults
        OpEventRestoreBlockDefaults_RestoreBlockDefaults_PS_NvBlockSwComponentTypeNVBlockDescriptor_BsRt_TripComputer: start-on-event=RestoreBlockDefaults, operation=PS_NvBlockSwComponentTypeNVBlockDescriptor_BsRt_TripComputer.RestoreBlockDefaults
        OpEventRestoreBlockDefaults_RestoreBlockDefaults_PS_NvBlockSwComponentTypeNVBlockDescriptor_BsRt_Warning: start-on-event=RestoreBlockDefaults, operation=PS_NvBlockSwComponentTypeNVBlockDescriptor_BsRt_Warning.RestoreBlockDefaults
        OpEventRestoreBlockDefaults_RestoreBlockDefaults_PS_NvBlockSwComponentTypeNVBlockDescriptor_BsShare_EcuPartNumber: start-on-event=RestoreBlockDefaults, operation=PS_NvBlockSwComponentTypeNVBlockDescriptor_BsShare_EcuPartNumber.RestoreBlockDefaults
        OpEventRestoreBlockDefaults_RestoreBlockDefaults_PS_NvBlockSwComponentTypeNVBlockDescriptor_BsShare_SwUpdFotaFinPrint: start-on-event=RestoreBlockDefaults, operation=PS_NvBlockSwComponentTypeNVBlockDescriptor_BsShare_SwUpdFotaFinPrint.RestoreBlockDefaults
        OpEventRestoreBlockDefaults_RestoreBlockDefaults_PS_NvBlockSwComponentTypeNVBlockDescriptor_BsShare_SwUpdFotaMode: start-on-event=RestoreBlockDefaults, operation=PS_NvBlockSwComponentTypeNVBlockDescriptor_BsShare_SwUpdFotaMode.RestoreBlockDefaults
        OpEventRestoreBlockDefaults_RestoreBlockDefaults_PS_NvBlockSwComponentTypeNVBlockDescriptor_BsShare_SwUpdFotaStatus: start-on-event=RestoreBlockDefaults, operation=PS_NvBlockSwComponentTypeNVBlockDescriptor_BsShare_SwUpdFotaStatus.RestoreBlockDefaults
        OpEventRestoreBlockDefaults_RestoreBlockDefaults_PS_NvBlockSwComponentTypeNVBlockDescriptor_BsShare_SwUpdFotadecrypt: start-on-event=RestoreBlockDefaults, operation=PS_NvBlockSwComponentTypeNVBlockDescriptor_BsShare_SwUpdFotadecrypt.RestoreBlockDefaults
        OpEventRestoreBlockDefaults_RestoreBlockDefaults_PS_NvBlockSwComponentTypeNVBlockDescriptor_BsShare_SwUpdReflash: start-on-event=RestoreBlockDefaults, operation=PS_NvBlockSwComponentTypeNVBlockDescriptor_BsShare_SwUpdReflash.RestoreBlockDefaults
        OpEventRestoreBlockDefaults_RestoreBlockDefaults_PS_NvBlockSwComponentTypeNVBlockDescriptor_BsShare_VehicleConfig: start-on-event=RestoreBlockDefaults, operation=PS_NvBlockSwComponentTypeNVBlockDescriptor_BsShare_VehicleConfig.RestoreBlockDefaults
        OpEventRestoreBlockDefaults_RestoreBlockDefaults_PS_NvBlockSwComponentTypeNVBlockDescriptor_BsShare_VisMeet: start-on-event=RestoreBlockDefaults, operation=PS_NvBlockSwComponentTypeNVBlockDescriptor_BsShare_VisMeet.RestoreBlockDefaults
        OpEventRestoreBlockDefaults_RestoreBlockDefaults_PS_NvBlockSwComponentTypeNVBlockDescriptor_RefCys_Certicificate: start-on-event=RestoreBlockDefaults, operation=PS_NvBlockSwComponentTypeNVBlockDescriptor_RefCys_Certicificate.RestoreBlockDefaults
        OpEventRestoreBlockDefaults_RestoreBlockDefaults_PS_NvBlockSwComponentTypeNVBlockDescriptor_RefCys_Certicificate1: start-on-event=RestoreBlockDefaults, operation=PS_NvBlockSwComponentTypeNVBlockDescriptor_RefCys_Certicificate1.RestoreBlockDefaults
        OpEventInvalidateNvBlock_InvalidateNvBlock_PS_NvBlockSwComponentTypeNVBlockDescriptor_BsConst_Audio: start-on-event=InvalidateNvBlock, operation=PS_NvBlockSwComponentTypeNVBlockDescriptor_BsConst_Audio.InvalidateNvBlock
        OpEventInvalidateNvBlock_InvalidateNvBlock_PS_NvBlockSwComponentTypeNVBlockDescriptor_BsConst_Communication: start-on-event=InvalidateNvBlock, operation=PS_NvBlockSwComponentTypeNVBlockDescriptor_BsConst_Communication.InvalidateNvBlock
        OpEventInvalidateNvBlock_InvalidateNvBlock_PS_NvBlockSwComponentTypeNVBlockDescriptor_BsConst_EngOffTimer: start-on-event=InvalidateNvBlock, operation=PS_NvBlockSwComponentTypeNVBlockDescriptor_BsConst_EngOffTimer.InvalidateNvBlock
        OpEventInvalidateNvBlock_InvalidateNvBlock_PS_NvBlockSwComponentTypeNVBlockDescriptor_BsConst_FuelGauge: start-on-event=InvalidateNvBlock, operation=PS_NvBlockSwComponentTypeNVBlockDescriptor_BsConst_FuelGauge.InvalidateNvBlock
        OpEventInvalidateNvBlock_InvalidateNvBlock_PS_NvBlockSwComponentTypeNVBlockDescriptor_BsConst_OilGauge: start-on-event=InvalidateNvBlock, operation=PS_NvBlockSwComponentTypeNVBlockDescriptor_BsConst_OilGauge.InvalidateNvBlock
        OpEventInvalidateNvBlock_InvalidateNvBlock_PS_NvBlockSwComponentTypeNVBlockDescriptor_BsConst_Power: start-on-event=InvalidateNvBlock, operation=PS_NvBlockSwComponentTypeNVBlockDescriptor_BsConst_Power.InvalidateNvBlock
        OpEventInvalidateNvBlock_InvalidateNvBlock_PS_NvBlockSwComponentTypeNVBlockDescriptor_BsConst_PowerGauge: start-on-event=InvalidateNvBlock, operation=PS_NvBlockSwComponentTypeNVBlockDescriptor_BsConst_PowerGauge.InvalidateNvBlock
        OpEventInvalidateNvBlock_InvalidateNvBlock_PS_NvBlockSwComponentTypeNVBlockDescriptor_BsConst_RealTimeClock: start-on-event=InvalidateNvBlock, operation=PS_NvBlockSwComponentTypeNVBlockDescriptor_BsConst_RealTimeClock.InvalidateNvBlock
        OpEventInvalidateNvBlock_InvalidateNvBlock_PS_NvBlockSwComponentTypeNVBlockDescriptor_BsConst_ServiceReminder: start-on-event=InvalidateNvBlock, operation=PS_NvBlockSwComponentTypeNVBlockDescriptor_BsConst_ServiceReminder.InvalidateNvBlock
        OpEventInvalidateNvBlock_InvalidateNvBlock_PS_NvBlockSwComponentTypeNVBlockDescriptor_BsConst_SpeedoGauge: start-on-event=InvalidateNvBlock, operation=PS_NvBlockSwComponentTypeNVBlockDescriptor_BsConst_SpeedoGauge.InvalidateNvBlock
        OpEventInvalidateNvBlock_InvalidateNvBlock_PS_NvBlockSwComponentTypeNVBlockDescriptor_BsConst_TachoGauge: start-on-event=InvalidateNvBlock, operation=PS_NvBlockSwComponentTypeNVBlockDescriptor_BsConst_TachoGauge.InvalidateNvBlock
        OpEventInvalidateNvBlock_InvalidateNvBlock_PS_NvBlockSwComponentTypeNVBlockDescriptor_BsConst_TempGauge: start-on-event=InvalidateNvBlock, operation=PS_NvBlockSwComponentTypeNVBlockDescriptor_BsConst_TempGauge.InvalidateNvBlock
        OpEventInvalidateNvBlock_InvalidateNvBlock_PS_NvBlockSwComponentTypeNVBlockDescriptor_BsConst_TripComputer: start-on-event=InvalidateNvBlock, operation=PS_NvBlockSwComponentTypeNVBlockDescriptor_BsConst_TripComputer.InvalidateNvBlock
        OpEventInvalidateNvBlock_InvalidateNvBlock_PS_NvBlockSwComponentTypeNVBlockDescriptor_BsConst_Warning: start-on-event=InvalidateNvBlock, operation=PS_NvBlockSwComponentTypeNVBlockDescriptor_BsConst_Warning.InvalidateNvBlock
        OpEventInvalidateNvBlock_InvalidateNvBlock_PS_NvBlockSwComponentTypeNVBlockDescriptor_BsCys_Certicificate: start-on-event=InvalidateNvBlock, operation=PS_NvBlockSwComponentTypeNVBlockDescriptor_BsCys_Certicificate.InvalidateNvBlock
        OpEventInvalidateNvBlock_InvalidateNvBlock_PS_NvBlockSwComponentTypeNVBlockDescriptor_BsDiag_Dtc: start-on-event=InvalidateNvBlock, operation=PS_NvBlockSwComponentTypeNVBlockDescriptor_BsDiag_Dtc.InvalidateNvBlock
        OpEventInvalidateNvBlock_InvalidateNvBlock_PS_NvBlockSwComponentTypeNVBlockDescriptor_BsDiag_ErrorRecord: start-on-event=InvalidateNvBlock, operation=PS_NvBlockSwComponentTypeNVBlockDescriptor_BsDiag_ErrorRecord.InvalidateNvBlock
        OpEventInvalidateNvBlock_InvalidateNvBlock_PS_NvBlockSwComponentTypeNVBlockDescriptor_BsReten_Audio: start-on-event=InvalidateNvBlock, operation=PS_NvBlockSwComponentTypeNVBlockDescriptor_BsReten_Audio.InvalidateNvBlock
        OpEventInvalidateNvBlock_InvalidateNvBlock_PS_NvBlockSwComponentTypeNVBlockDescriptor_BsReten_Communication: start-on-event=InvalidateNvBlock, operation=PS_NvBlockSwComponentTypeNVBlockDescriptor_BsReten_Communication.InvalidateNvBlock
        OpEventInvalidateNvBlock_InvalidateNvBlock_PS_NvBlockSwComponentTypeNVBlockDescriptor_BsReten_Display: start-on-event=InvalidateNvBlock, operation=PS_NvBlockSwComponentTypeNVBlockDescriptor_BsReten_Display.InvalidateNvBlock
        OpEventInvalidateNvBlock_InvalidateNvBlock_PS_NvBlockSwComponentTypeNVBlockDescriptor_BsReten_Gauges: start-on-event=InvalidateNvBlock, operation=PS_NvBlockSwComponentTypeNVBlockDescriptor_BsReten_Gauges.InvalidateNvBlock
        OpEventInvalidateNvBlock_InvalidateNvBlock_PS_NvBlockSwComponentTypeNVBlockDescriptor_BsReten_Illumination: start-on-event=InvalidateNvBlock, operation=PS_NvBlockSwComponentTypeNVBlockDescriptor_BsReten_Illumination.InvalidateNvBlock
        OpEventInvalidateNvBlock_InvalidateNvBlock_PS_NvBlockSwComponentTypeNVBlockDescriptor_BsReten_Odometer: start-on-event=InvalidateNvBlock, operation=PS_NvBlockSwComponentTypeNVBlockDescriptor_BsReten_Odometer.InvalidateNvBlock
        OpEventInvalidateNvBlock_InvalidateNvBlock_PS_NvBlockSwComponentTypeNVBlockDescriptor_BsReten_Personalization: start-on-event=InvalidateNvBlock, operation=PS_NvBlockSwComponentTypeNVBlockDescriptor_BsReten_Personalization.InvalidateNvBlock
        OpEventInvalidateNvBlock_InvalidateNvBlock_PS_NvBlockSwComponentTypeNVBlockDescriptor_BsReten_Power: start-on-event=InvalidateNvBlock, operation=PS_NvBlockSwComponentTypeNVBlockDescriptor_BsReten_Power.InvalidateNvBlock
        OpEventInvalidateNvBlock_InvalidateNvBlock_PS_NvBlockSwComponentTypeNVBlockDescriptor_BsReten_RealTimeClock: start-on-event=InvalidateNvBlock, operation=PS_NvBlockSwComponentTypeNVBlockDescriptor_BsReten_RealTimeClock.InvalidateNvBlock
        OpEventInvalidateNvBlock_InvalidateNvBlock_PS_NvBlockSwComponentTypeNVBlockDescriptor_BsReten_Tripcomputer: start-on-event=InvalidateNvBlock, operation=PS_NvBlockSwComponentTypeNVBlockDescriptor_BsReten_Tripcomputer.InvalidateNvBlock
        OpEventInvalidateNvBlock_InvalidateNvBlock_PS_NvBlockSwComponentTypeNVBlockDescriptor_BsReten_Warning: start-on-event=InvalidateNvBlock, operation=PS_NvBlockSwComponentTypeNVBlockDescriptor_BsReten_Warning.InvalidateNvBlock
        OpEventInvalidateNvBlock_InvalidateNvBlock_PS_NvBlockSwComponentTypeNVBlockDescriptor_BsRt_CusDlt: start-on-event=InvalidateNvBlock, operation=PS_NvBlockSwComponentTypeNVBlockDescriptor_BsRt_CusDlt.InvalidateNvBlock
        OpEventInvalidateNvBlock_InvalidateNvBlock_PS_NvBlockSwComponentTypeNVBlockDescriptor_BsRt_FuelGauge: start-on-event=InvalidateNvBlock, operation=PS_NvBlockSwComponentTypeNVBlockDescriptor_BsRt_FuelGauge.InvalidateNvBlock
        OpEventInvalidateNvBlock_InvalidateNvBlock_PS_NvBlockSwComponentTypeNVBlockDescriptor_BsRt_Illumination: start-on-event=InvalidateNvBlock, operation=PS_NvBlockSwComponentTypeNVBlockDescriptor_BsRt_Illumination.InvalidateNvBlock
        OpEventInvalidateNvBlock_InvalidateNvBlock_PS_NvBlockSwComponentTypeNVBlockDescriptor_BsRt_Odometer: start-on-event=InvalidateNvBlock, operation=PS_NvBlockSwComponentTypeNVBlockDescriptor_BsRt_Odometer.InvalidateNvBlock
        OpEventInvalidateNvBlock_InvalidateNvBlock_PS_NvBlockSwComponentTypeNVBlockDescriptor_BsRt_OilGauge: start-on-event=InvalidateNvBlock, operation=PS_NvBlockSwComponentTypeNVBlockDescriptor_BsRt_OilGauge.InvalidateNvBlock
        OpEventInvalidateNvBlock_InvalidateNvBlock_PS_NvBlockSwComponentTypeNVBlockDescriptor_BsRt_Personalization: start-on-event=InvalidateNvBlock, operation=PS_NvBlockSwComponentTypeNVBlockDescriptor_BsRt_Personalization.InvalidateNvBlock
        OpEventInvalidateNvBlock_InvalidateNvBlock_PS_NvBlockSwComponentTypeNVBlockDescriptor_BsRt_PowerGauge: start-on-event=InvalidateNvBlock, operation=PS_NvBlockSwComponentTypeNVBlockDescriptor_BsRt_PowerGauge.InvalidateNvBlock
        OpEventInvalidateNvBlock_InvalidateNvBlock_PS_NvBlockSwComponentTypeNVBlockDescriptor_BsRt_RealTimeClock: start-on-event=InvalidateNvBlock, operation=PS_NvBlockSwComponentTypeNVBlockDescriptor_BsRt_RealTimeClock.InvalidateNvBlock
        OpEventInvalidateNvBlock_InvalidateNvBlock_PS_NvBlockSwComponentTypeNVBlockDescriptor_BsRt_SpeedoGauge: start-on-event=InvalidateNvBlock, operation=PS_NvBlockSwComponentTypeNVBlockDescriptor_BsRt_SpeedoGauge.InvalidateNvBlock
        OpEventInvalidateNvBlock_InvalidateNvBlock_PS_NvBlockSwComponentTypeNVBlockDescriptor_BsRt_TachoGauge: start-on-event=InvalidateNvBlock, operation=PS_NvBlockSwComponentTypeNVBlockDescriptor_BsRt_TachoGauge.InvalidateNvBlock
        OpEventInvalidateNvBlock_InvalidateNvBlock_PS_NvBlockSwComponentTypeNVBlockDescriptor_BsRt_TempGauge: start-on-event=InvalidateNvBlock, operation=PS_NvBlockSwComponentTypeNVBlockDescriptor_BsRt_TempGauge.InvalidateNvBlock
        OpEventInvalidateNvBlock_InvalidateNvBlock_PS_NvBlockSwComponentTypeNVBlockDescriptor_BsRt_TripComputer: start-on-event=InvalidateNvBlock, operation=PS_NvBlockSwComponentTypeNVBlockDescriptor_BsRt_TripComputer.InvalidateNvBlock
        OpEventInvalidateNvBlock_InvalidateNvBlock_PS_NvBlockSwComponentTypeNVBlockDescriptor_BsRt_Warning: start-on-event=InvalidateNvBlock, operation=PS_NvBlockSwComponentTypeNVBlockDescriptor_BsRt_Warning.InvalidateNvBlock
        OpEventInvalidateNvBlock_InvalidateNvBlock_PS_NvBlockSwComponentTypeNVBlockDescriptor_BsShare_EcuPartNumber: start-on-event=InvalidateNvBlock, operation=PS_NvBlockSwComponentTypeNVBlockDescriptor_BsShare_EcuPartNumber.InvalidateNvBlock
        OpEventInvalidateNvBlock_InvalidateNvBlock_PS_NvBlockSwComponentTypeNVBlockDescriptor_BsShare_SwUpdFotaFinPrint: start-on-event=InvalidateNvBlock, operation=PS_NvBlockSwComponentTypeNVBlockDescriptor_BsShare_SwUpdFotaFinPrint.InvalidateNvBlock
        OpEventInvalidateNvBlock_InvalidateNvBlock_PS_NvBlockSwComponentTypeNVBlockDescriptor_BsShare_SwUpdFotaMode: start-on-event=InvalidateNvBlock, operation=PS_NvBlockSwComponentTypeNVBlockDescriptor_BsShare_SwUpdFotaMode.InvalidateNvBlock
        OpEventInvalidateNvBlock_InvalidateNvBlock_PS_NvBlockSwComponentTypeNVBlockDescriptor_BsShare_SwUpdFotaStatus: start-on-event=InvalidateNvBlock, operation=PS_NvBlockSwComponentTypeNVBlockDescriptor_BsShare_SwUpdFotaStatus.InvalidateNvBlock
        OpEventInvalidateNvBlock_InvalidateNvBlock_PS_NvBlockSwComponentTypeNVBlockDescriptor_BsShare_SwUpdFotadecrypt: start-on-event=InvalidateNvBlock, operation=PS_NvBlockSwComponentTypeNVBlockDescriptor_BsShare_SwUpdFotadecrypt.InvalidateNvBlock
        OpEventInvalidateNvBlock_InvalidateNvBlock_PS_NvBlockSwComponentTypeNVBlockDescriptor_BsShare_SwUpdReflash: start-on-event=InvalidateNvBlock, operation=PS_NvBlockSwComponentTypeNVBlockDescriptor_BsShare_SwUpdReflash.InvalidateNvBlock
        OpEventInvalidateNvBlock_InvalidateNvBlock_PS_NvBlockSwComponentTypeNVBlockDescriptor_BsShare_VehicleConfig: start-on-event=InvalidateNvBlock, operation=PS_NvBlockSwComponentTypeNVBlockDescriptor_BsShare_VehicleConfig.InvalidateNvBlock
        OpEventInvalidateNvBlock_InvalidateNvBlock_PS_NvBlockSwComponentTypeNVBlockDescriptor_BsShare_VisMeet: start-on-event=InvalidateNvBlock, operation=PS_NvBlockSwComponentTypeNVBlockDescriptor_BsShare_VisMeet.InvalidateNvBlock
        OpEventInvalidateNvBlock_InvalidateNvBlock_PS_NvBlockSwComponentTypeNVBlockDescriptor_RefCys_Certicificate: start-on-event=InvalidateNvBlock, operation=PS_NvBlockSwComponentTypeNVBlockDescriptor_RefCys_Certicificate.InvalidateNvBlock
        OpEventInvalidateNvBlock_InvalidateNvBlock_PS_NvBlockSwComponentTypeNVBlockDescriptor_RefCys_Certicificate1: start-on-event=InvalidateNvBlock, operation=PS_NvBlockSwComponentTypeNVBlockDescriptor_RefCys_Certicificate1.InvalidateNvBlock
        OpEventEraseBlock_EraseBlock_PS_NvBlockSwComponentTypeNVBlockDescriptor_BsConst_Audio: start-on-event=EraseBlock, operation=PS_NvBlockSwComponentTypeNVBlockDescriptor_BsConst_Audio.EraseBlock
        OpEventEraseBlock_EraseBlock_PS_NvBlockSwComponentTypeNVBlockDescriptor_BsConst_Communication: start-on-event=EraseBlock, operation=PS_NvBlockSwComponentTypeNVBlockDescriptor_BsConst_Communication.EraseBlock
        OpEventEraseBlock_EraseBlock_PS_NvBlockSwComponentTypeNVBlockDescriptor_BsConst_EngOffTimer: start-on-event=EraseBlock, operation=PS_NvBlockSwComponentTypeNVBlockDescriptor_BsConst_EngOffTimer.EraseBlock
        OpEventEraseBlock_EraseBlock_PS_NvBlockSwComponentTypeNVBlockDescriptor_BsConst_FuelGauge: start-on-event=EraseBlock, operation=PS_NvBlockSwComponentTypeNVBlockDescriptor_BsConst_FuelGauge.EraseBlock
        OpEventEraseBlock_EraseBlock_PS_NvBlockSwComponentTypeNVBlockDescriptor_BsConst_OilGauge: start-on-event=EraseBlock, operation=PS_NvBlockSwComponentTypeNVBlockDescriptor_BsConst_OilGauge.EraseBlock
        OpEventEraseBlock_EraseBlock_PS_NvBlockSwComponentTypeNVBlockDescriptor_BsConst_Power: start-on-event=EraseBlock, operation=PS_NvBlockSwComponentTypeNVBlockDescriptor_BsConst_Power.EraseBlock
        OpEventEraseBlock_EraseBlock_PS_NvBlockSwComponentTypeNVBlockDescriptor_BsConst_PowerGauge: start-on-event=EraseBlock, operation=PS_NvBlockSwComponentTypeNVBlockDescriptor_BsConst_PowerGauge.EraseBlock
        OpEventEraseBlock_EraseBlock_PS_NvBlockSwComponentTypeNVBlockDescriptor_BsConst_RealTimeClock: start-on-event=EraseBlock, operation=PS_NvBlockSwComponentTypeNVBlockDescriptor_BsConst_RealTimeClock.EraseBlock
        OpEventEraseBlock_EraseBlock_PS_NvBlockSwComponentTypeNVBlockDescriptor_BsConst_ServiceReminder: start-on-event=EraseBlock, operation=PS_NvBlockSwComponentTypeNVBlockDescriptor_BsConst_ServiceReminder.EraseBlock
        OpEventEraseBlock_EraseBlock_PS_NvBlockSwComponentTypeNVBlockDescriptor_BsConst_SpeedoGauge: start-on-event=EraseBlock, operation=PS_NvBlockSwComponentTypeNVBlockDescriptor_BsConst_SpeedoGauge.EraseBlock
        OpEventEraseBlock_EraseBlock_PS_NvBlockSwComponentTypeNVBlockDescriptor_BsConst_TachoGauge: start-on-event=EraseBlock, operation=PS_NvBlockSwComponentTypeNVBlockDescriptor_BsConst_TachoGauge.EraseBlock
        OpEventEraseBlock_EraseBlock_PS_NvBlockSwComponentTypeNVBlockDescriptor_BsConst_TempGauge: start-on-event=EraseBlock, operation=PS_NvBlockSwComponentTypeNVBlockDescriptor_BsConst_TempGauge.EraseBlock
        OpEventEraseBlock_EraseBlock_PS_NvBlockSwComponentTypeNVBlockDescriptor_BsConst_TripComputer: start-on-event=EraseBlock, operation=PS_NvBlockSwComponentTypeNVBlockDescriptor_BsConst_TripComputer.EraseBlock
        OpEventEraseBlock_EraseBlock_PS_NvBlockSwComponentTypeNVBlockDescriptor_BsConst_Warning: start-on-event=EraseBlock, operation=PS_NvBlockSwComponentTypeNVBlockDescriptor_BsConst_Warning.EraseBlock
        OpEventEraseBlock_EraseBlock_PS_NvBlockSwComponentTypeNVBlockDescriptor_BsCys_Certicificate: start-on-event=EraseBlock, operation=PS_NvBlockSwComponentTypeNVBlockDescriptor_BsCys_Certicificate.EraseBlock
        OpEventEraseBlock_EraseBlock_PS_NvBlockSwComponentTypeNVBlockDescriptor_BsDiag_Dtc: start-on-event=EraseBlock, operation=PS_NvBlockSwComponentTypeNVBlockDescriptor_BsDiag_Dtc.EraseBlock
        OpEventEraseBlock_EraseBlock_PS_NvBlockSwComponentTypeNVBlockDescriptor_BsDiag_ErrorRecord: start-on-event=EraseBlock, operation=PS_NvBlockSwComponentTypeNVBlockDescriptor_BsDiag_ErrorRecord.EraseBlock
        OpEventEraseBlock_EraseBlock_PS_NvBlockSwComponentTypeNVBlockDescriptor_BsReten_Audio: start-on-event=EraseBlock, operation=PS_NvBlockSwComponentTypeNVBlockDescriptor_BsReten_Audio.EraseBlock
        OpEventEraseBlock_EraseBlock_PS_NvBlockSwComponentTypeNVBlockDescriptor_BsReten_Communication: start-on-event=EraseBlock, operation=PS_NvBlockSwComponentTypeNVBlockDescriptor_BsReten_Communication.EraseBlock
        OpEventEraseBlock_EraseBlock_PS_NvBlockSwComponentTypeNVBlockDescriptor_BsReten_Display: start-on-event=EraseBlock, operation=PS_NvBlockSwComponentTypeNVBlockDescriptor_BsReten_Display.EraseBlock
        OpEventEraseBlock_EraseBlock_PS_NvBlockSwComponentTypeNVBlockDescriptor_BsReten_Gauges: start-on-event=EraseBlock, operation=PS_NvBlockSwComponentTypeNVBlockDescriptor_BsReten_Gauges.EraseBlock
        OpEventEraseBlock_EraseBlock_PS_NvBlockSwComponentTypeNVBlockDescriptor_BsReten_Illumination: start-on-event=EraseBlock, operation=PS_NvBlockSwComponentTypeNVBlockDescriptor_BsReten_Illumination.EraseBlock
        OpEventEraseBlock_EraseBlock_PS_NvBlockSwComponentTypeNVBlockDescriptor_BsReten_Odometer: start-on-event=EraseBlock, operation=PS_NvBlockSwComponentTypeNVBlockDescriptor_BsReten_Odometer.EraseBlock
        OpEventEraseBlock_EraseBlock_PS_NvBlockSwComponentTypeNVBlockDescriptor_BsReten_Personalization: start-on-event=EraseBlock, operation=PS_NvBlockSwComponentTypeNVBlockDescriptor_BsReten_Personalization.EraseBlock
        OpEventEraseBlock_EraseBlock_PS_NvBlockSwComponentTypeNVBlockDescriptor_BsReten_Power: start-on-event=EraseBlock, operation=PS_NvBlockSwComponentTypeNVBlockDescriptor_BsReten_Power.EraseBlock
        OpEventEraseBlock_EraseBlock_PS_NvBlockSwComponentTypeNVBlockDescriptor_BsReten_RealTimeClock: start-on-event=EraseBlock, operation=PS_NvBlockSwComponentTypeNVBlockDescriptor_BsReten_RealTimeClock.EraseBlock
        OpEventEraseBlock_EraseBlock_PS_NvBlockSwComponentTypeNVBlockDescriptor_BsReten_Tripcomputer: start-on-event=EraseBlock, operation=PS_NvBlockSwComponentTypeNVBlockDescriptor_BsReten_Tripcomputer.EraseBlock
        OpEventEraseBlock_EraseBlock_PS_NvBlockSwComponentTypeNVBlockDescriptor_BsReten_Warning: start-on-event=EraseBlock, operation=PS_NvBlockSwComponentTypeNVBlockDescriptor_BsReten_Warning.EraseBlock
        OpEventEraseBlock_EraseBlock_PS_NvBlockSwComponentTypeNVBlockDescriptor_BsRt_CusDlt: start-on-event=EraseBlock, operation=PS_NvBlockSwComponentTypeNVBlockDescriptor_BsRt_CusDlt.EraseBlock
        OpEventEraseBlock_EraseBlock_PS_NvBlockSwComponentTypeNVBlockDescriptor_BsRt_FuelGauge: start-on-event=EraseBlock, operation=PS_NvBlockSwComponentTypeNVBlockDescriptor_BsRt_FuelGauge.EraseBlock
        OpEventEraseBlock_EraseBlock_PS_NvBlockSwComponentTypeNVBlockDescriptor_BsRt_Illumination: start-on-event=EraseBlock, operation=PS_NvBlockSwComponentTypeNVBlockDescriptor_BsRt_Illumination.EraseBlock
        OpEventEraseBlock_EraseBlock_PS_NvBlockSwComponentTypeNVBlockDescriptor_BsRt_Odometer: start-on-event=EraseBlock, operation=PS_NvBlockSwComponentTypeNVBlockDescriptor_BsRt_Odometer.EraseBlock
        OpEventEraseBlock_EraseBlock_PS_NvBlockSwComponentTypeNVBlockDescriptor_BsRt_OilGauge: start-on-event=EraseBlock, operation=PS_NvBlockSwComponentTypeNVBlockDescriptor_BsRt_OilGauge.EraseBlock
        OpEventEraseBlock_EraseBlock_PS_NvBlockSwComponentTypeNVBlockDescriptor_BsRt_Personalization: start-on-event=EraseBlock, operation=PS_NvBlockSwComponentTypeNVBlockDescriptor_BsRt_Personalization.EraseBlock
        OpEventEraseBlock_EraseBlock_PS_NvBlockSwComponentTypeNVBlockDescriptor_BsRt_PowerGauge: start-on-event=EraseBlock, operation=PS_NvBlockSwComponentTypeNVBlockDescriptor_BsRt_PowerGauge.EraseBlock
        OpEventEraseBlock_EraseBlock_PS_NvBlockSwComponentTypeNVBlockDescriptor_BsRt_RealTimeClock: start-on-event=EraseBlock, operation=PS_NvBlockSwComponentTypeNVBlockDescriptor_BsRt_RealTimeClock.EraseBlock
        OpEventEraseBlock_EraseBlock_PS_NvBlockSwComponentTypeNVBlockDescriptor_BsRt_SpeedoGauge: start-on-event=EraseBlock, operation=PS_NvBlockSwComponentTypeNVBlockDescriptor_BsRt_SpeedoGauge.EraseBlock
        OpEventEraseBlock_EraseBlock_PS_NvBlockSwComponentTypeNVBlockDescriptor_BsRt_TachoGauge: start-on-event=EraseBlock, operation=PS_NvBlockSwComponentTypeNVBlockDescriptor_BsRt_TachoGauge.EraseBlock
        OpEventEraseBlock_EraseBlock_PS_NvBlockSwComponentTypeNVBlockDescriptor_BsRt_TempGauge: start-on-event=EraseBlock, operation=PS_NvBlockSwComponentTypeNVBlockDescriptor_BsRt_TempGauge.EraseBlock
        OpEventEraseBlock_EraseBlock_PS_NvBlockSwComponentTypeNVBlockDescriptor_BsRt_TripComputer: start-on-event=EraseBlock, operation=PS_NvBlockSwComponentTypeNVBlockDescriptor_BsRt_TripComputer.EraseBlock
        OpEventEraseBlock_EraseBlock_PS_NvBlockSwComponentTypeNVBlockDescriptor_BsRt_Warning: start-on-event=EraseBlock, operation=PS_NvBlockSwComponentTypeNVBlockDescriptor_BsRt_Warning.EraseBlock
        OpEventEraseBlock_EraseBlock_PS_NvBlockSwComponentTypeNVBlockDescriptor_BsShare_EcuPartNumber: start-on-event=EraseBlock, operation=PS_NvBlockSwComponentTypeNVBlockDescriptor_BsShare_EcuPartNumber.EraseBlock
        OpEventEraseBlock_EraseBlock_PS_NvBlockSwComponentTypeNVBlockDescriptor_BsShare_SwUpdFotaFinPrint: start-on-event=EraseBlock, operation=PS_NvBlockSwComponentTypeNVBlockDescriptor_BsShare_SwUpdFotaFinPrint.EraseBlock
        OpEventEraseBlock_EraseBlock_PS_NvBlockSwComponentTypeNVBlockDescriptor_BsShare_SwUpdFotaMode: start-on-event=EraseBlock, operation=PS_NvBlockSwComponentTypeNVBlockDescriptor_BsShare_SwUpdFotaMode.EraseBlock
        OpEventEraseBlock_EraseBlock_PS_NvBlockSwComponentTypeNVBlockDescriptor_BsShare_SwUpdFotaStatus: start-on-event=EraseBlock, operation=PS_NvBlockSwComponentTypeNVBlockDescriptor_BsShare_SwUpdFotaStatus.EraseBlock
        OpEventEraseBlock_EraseBlock_PS_NvBlockSwComponentTypeNVBlockDescriptor_BsShare_SwUpdFotadecrypt: start-on-event=EraseBlock, operation=PS_NvBlockSwComponentTypeNVBlockDescriptor_BsShare_SwUpdFotadecrypt.EraseBlock
        OpEventEraseBlock_EraseBlock_PS_NvBlockSwComponentTypeNVBlockDescriptor_BsShare_SwUpdReflash: start-on-event=EraseBlock, operation=PS_NvBlockSwComponentTypeNVBlockDescriptor_BsShare_SwUpdReflash.EraseBlock
        OpEventEraseBlock_EraseBlock_PS_NvBlockSwComponentTypeNVBlockDescriptor_BsShare_VehicleConfig: start-on-event=EraseBlock, operation=PS_NvBlockSwComponentTypeNVBlockDescriptor_BsShare_VehicleConfig.EraseBlock
        OpEventEraseBlock_EraseBlock_PS_NvBlockSwComponentTypeNVBlockDescriptor_BsShare_VisMeet: start-on-event=EraseBlock, operation=PS_NvBlockSwComponentTypeNVBlockDescriptor_BsShare_VisMeet.EraseBlock
        OpEventEraseBlock_EraseBlock_PS_NvBlockSwComponentTypeNVBlockDescriptor_RefCys_Certicificate: start-on-event=EraseBlock, operation=PS_NvBlockSwComponentTypeNVBlockDescriptor_RefCys_Certicificate.EraseBlock
        OpEventEraseBlock_EraseBlock_PS_NvBlockSwComponentTypeNVBlockDescriptor_RefCys_Certicificate1: start-on-event=EraseBlock, operation=PS_NvBlockSwComponentTypeNVBlockDescriptor_RefCys_Certicificate1.EraseBlock
        OpEventSetBlockProtection_SetBlockProtection_PAdmin_NvBlockSwComponentTypeNVBlockDescriptor_BsConst_Audio: start-on-event=SetBlockProtection, operation=PAdmin_NvBlockSwComponentTypeNVBlockDescriptor_BsConst_Audio.SetBlockProtection
        OpEventSetBlockProtection_SetBlockProtection_PAdmin_NvBlockSwComponentTypeNVBlockDescriptor_BsConst_Communication: start-on-event=SetBlockProtection, operation=PAdmin_NvBlockSwComponentTypeNVBlockDescriptor_BsConst_Communication.SetBlockProtection
        OpEventSetBlockProtection_SetBlockProtection_PAdmin_NvBlockSwComponentTypeNVBlockDescriptor_BsConst_EngOffTimer: start-on-event=SetBlockProtection, operation=PAdmin_NvBlockSwComponentTypeNVBlockDescriptor_BsConst_EngOffTimer.SetBlockProtection
        OpEventSetBlockProtection_SetBlockProtection_PAdmin_NvBlockSwComponentTypeNVBlockDescriptor_BsConst_FuelGauge: start-on-event=SetBlockProtection, operation=PAdmin_NvBlockSwComponentTypeNVBlockDescriptor_BsConst_FuelGauge.SetBlockProtection
        OpEventSetBlockProtection_SetBlockProtection_PAdmin_NvBlockSwComponentTypeNVBlockDescriptor_BsConst_OilGauge: start-on-event=SetBlockProtection, operation=PAdmin_NvBlockSwComponentTypeNVBlockDescriptor_BsConst_OilGauge.SetBlockProtection
        OpEventSetBlockProtection_SetBlockProtection_PAdmin_NvBlockSwComponentTypeNVBlockDescriptor_BsConst_Power: start-on-event=SetBlockProtection, operation=PAdmin_NvBlockSwComponentTypeNVBlockDescriptor_BsConst_Power.SetBlockProtection
        OpEventSetBlockProtection_SetBlockProtection_PAdmin_NvBlockSwComponentTypeNVBlockDescriptor_BsConst_PowerGauge: start-on-event=SetBlockProtection, operation=PAdmin_NvBlockSwComponentTypeNVBlockDescriptor_BsConst_PowerGauge.SetBlockProtection
        OpEventSetBlockProtection_SetBlockProtection_PAdmin_NvBlockSwComponentTypeNVBlockDescriptor_BsConst_RealTimeClock: start-on-event=SetBlockProtection, operation=PAdmin_NvBlockSwComponentTypeNVBlockDescriptor_BsConst_RealTimeClock.SetBlockProtection
        OpEventSetBlockProtection_SetBlockProtection_PAdmin_NvBlockSwComponentTypeNVBlockDescriptor_BsConst_ServiceReminder: start-on-event=SetBlockProtection, operation=PAdmin_NvBlockSwComponentTypeNVBlockDescriptor_BsConst_ServiceReminder.SetBlockProtection
        OpEventSetBlockProtection_SetBlockProtection_PAdmin_NvBlockSwComponentTypeNVBlockDescriptor_BsConst_SpeedoGauge: start-on-event=SetBlockProtection, operation=PAdmin_NvBlockSwComponentTypeNVBlockDescriptor_BsConst_SpeedoGauge.SetBlockProtection
        OpEventSetBlockProtection_SetBlockProtection_PAdmin_NvBlockSwComponentTypeNVBlockDescriptor_BsConst_TachoGauge: start-on-event=SetBlockProtection, operation=PAdmin_NvBlockSwComponentTypeNVBlockDescriptor_BsConst_TachoGauge.SetBlockProtection
        OpEventSetBlockProtection_SetBlockProtection_PAdmin_NvBlockSwComponentTypeNVBlockDescriptor_BsConst_TempGauge: start-on-event=SetBlockProtection, operation=PAdmin_NvBlockSwComponentTypeNVBlockDescriptor_BsConst_TempGauge.SetBlockProtection
        OpEventSetBlockProtection_SetBlockProtection_PAdmin_NvBlockSwComponentTypeNVBlockDescriptor_BsConst_TripComputer: start-on-event=SetBlockProtection, operation=PAdmin_NvBlockSwComponentTypeNVBlockDescriptor_BsConst_TripComputer.SetBlockProtection
        OpEventSetBlockProtection_SetBlockProtection_PAdmin_NvBlockSwComponentTypeNVBlockDescriptor_BsConst_Warning: start-on-event=SetBlockProtection, operation=PAdmin_NvBlockSwComponentTypeNVBlockDescriptor_BsConst_Warning.SetBlockProtection
        OpEventSetBlockProtection_SetBlockProtection_PAdmin_NvBlockSwComponentTypeNVBlockDescriptor_BsCys_Certicificate: start-on-event=SetBlockProtection, operation=PAdmin_NvBlockSwComponentTypeNVBlockDescriptor_BsCys_Certicificate.SetBlockProtection
        OpEventSetBlockProtection_SetBlockProtection_PAdmin_NvBlockSwComponentTypeNVBlockDescriptor_BsDiag_Dtc: start-on-event=SetBlockProtection, operation=PAdmin_NvBlockSwComponentTypeNVBlockDescriptor_BsDiag_Dtc.SetBlockProtection
        OpEventSetBlockProtection_SetBlockProtection_PAdmin_NvBlockSwComponentTypeNVBlockDescriptor_BsDiag_ErrorRecord: start-on-event=SetBlockProtection, operation=PAdmin_NvBlockSwComponentTypeNVBlockDescriptor_BsDiag_ErrorRecord.SetBlockProtection
        OpEventSetBlockProtection_SetBlockProtection_PAdmin_NvBlockSwComponentTypeNVBlockDescriptor_BsReten_Audio: start-on-event=SetBlockProtection, operation=PAdmin_NvBlockSwComponentTypeNVBlockDescriptor_BsReten_Audio.SetBlockProtection
        OpEventSetBlockProtection_SetBlockProtection_PAdmin_NvBlockSwComponentTypeNVBlockDescriptor_BsReten_Communication: start-on-event=SetBlockProtection, operation=PAdmin_NvBlockSwComponentTypeNVBlockDescriptor_BsReten_Communication.SetBlockProtection
        OpEventSetBlockProtection_SetBlockProtection_PAdmin_NvBlockSwComponentTypeNVBlockDescriptor_BsReten_Display: start-on-event=SetBlockProtection, operation=PAdmin_NvBlockSwComponentTypeNVBlockDescriptor_BsReten_Display.SetBlockProtection
        OpEventSetBlockProtection_SetBlockProtection_PAdmin_NvBlockSwComponentTypeNVBlockDescriptor_BsReten_Gauges: start-on-event=SetBlockProtection, operation=PAdmin_NvBlockSwComponentTypeNVBlockDescriptor_BsReten_Gauges.SetBlockProtection
        OpEventSetBlockProtection_SetBlockProtection_PAdmin_NvBlockSwComponentTypeNVBlockDescriptor_BsReten_Illumination: start-on-event=SetBlockProtection, operation=PAdmin_NvBlockSwComponentTypeNVBlockDescriptor_BsReten_Illumination.SetBlockProtection
        OpEventSetBlockProtection_SetBlockProtection_PAdmin_NvBlockSwComponentTypeNVBlockDescriptor_BsReten_Odometer: start-on-event=SetBlockProtection, operation=PAdmin_NvBlockSwComponentTypeNVBlockDescriptor_BsReten_Odometer.SetBlockProtection
        OpEventSetBlockProtection_SetBlockProtection_PAdmin_NvBlockSwComponentTypeNVBlockDescriptor_BsReten_Personalization: start-on-event=SetBlockProtection, operation=PAdmin_NvBlockSwComponentTypeNVBlockDescriptor_BsReten_Personalization.SetBlockProtection
        OpEventSetBlockProtection_SetBlockProtection_PAdmin_NvBlockSwComponentTypeNVBlockDescriptor_BsReten_Power: start-on-event=SetBlockProtection, operation=PAdmin_NvBlockSwComponentTypeNVBlockDescriptor_BsReten_Power.SetBlockProtection
        OpEventSetBlockProtection_SetBlockProtection_PAdmin_NvBlockSwComponentTypeNVBlockDescriptor_BsReten_RealTimeClock: start-on-event=SetBlockProtection, operation=PAdmin_NvBlockSwComponentTypeNVBlockDescriptor_BsReten_RealTimeClock.SetBlockProtection
        OpEventSetBlockProtection_SetBlockProtection_PAdmin_NvBlockSwComponentTypeNVBlockDescriptor_BsReten_Tripcomputer: start-on-event=SetBlockProtection, operation=PAdmin_NvBlockSwComponentTypeNVBlockDescriptor_BsReten_Tripcomputer.SetBlockProtection
        OpEventSetBlockProtection_SetBlockProtection_PAdmin_NvBlockSwComponentTypeNVBlockDescriptor_BsReten_Warning: start-on-event=SetBlockProtection, operation=PAdmin_NvBlockSwComponentTypeNVBlockDescriptor_BsReten_Warning.SetBlockProtection
        OpEventSetBlockProtection_SetBlockProtection_PAdmin_NvBlockSwComponentTypeNVBlockDescriptor_BsRt_CusDlt: start-on-event=SetBlockProtection, operation=PAdmin_NvBlockSwComponentTypeNVBlockDescriptor_BsRt_CusDlt.SetBlockProtection
        OpEventSetBlockProtection_SetBlockProtection_PAdmin_NvBlockSwComponentTypeNVBlockDescriptor_BsRt_FuelGauge: start-on-event=SetBlockProtection, operation=PAdmin_NvBlockSwComponentTypeNVBlockDescriptor_BsRt_FuelGauge.SetBlockProtection
        OpEventSetBlockProtection_SetBlockProtection_PAdmin_NvBlockSwComponentTypeNVBlockDescriptor_BsRt_Illumination: start-on-event=SetBlockProtection, operation=PAdmin_NvBlockSwComponentTypeNVBlockDescriptor_BsRt_Illumination.SetBlockProtection
        OpEventSetBlockProtection_SetBlockProtection_PAdmin_NvBlockSwComponentTypeNVBlockDescriptor_BsRt_Odometer: start-on-event=SetBlockProtection, operation=PAdmin_NvBlockSwComponentTypeNVBlockDescriptor_BsRt_Odometer.SetBlockProtection
        OpEventSetBlockProtection_SetBlockProtection_PAdmin_NvBlockSwComponentTypeNVBlockDescriptor_BsRt_OilGauge: start-on-event=SetBlockProtection, operation=PAdmin_NvBlockSwComponentTypeNVBlockDescriptor_BsRt_OilGauge.SetBlockProtection
        OpEventSetBlockProtection_SetBlockProtection_PAdmin_NvBlockSwComponentTypeNVBlockDescriptor_BsRt_Personalization: start-on-event=SetBlockProtection, operation=PAdmin_NvBlockSwComponentTypeNVBlockDescriptor_BsRt_Personalization.SetBlockProtection
        OpEventSetBlockProtection_SetBlockProtection_PAdmin_NvBlockSwComponentTypeNVBlockDescriptor_BsRt_PowerGauge: start-on-event=SetBlockProtection, operation=PAdmin_NvBlockSwComponentTypeNVBlockDescriptor_BsRt_PowerGauge.SetBlockProtection
        OpEventSetBlockProtection_SetBlockProtection_PAdmin_NvBlockSwComponentTypeNVBlockDescriptor_BsRt_RealTimeClock: start-on-event=SetBlockProtection, operation=PAdmin_NvBlockSwComponentTypeNVBlockDescriptor_BsRt_RealTimeClock.SetBlockProtection
        OpEventSetBlockProtection_SetBlockProtection_PAdmin_NvBlockSwComponentTypeNVBlockDescriptor_BsRt_SpeedoGauge: start-on-event=SetBlockProtection, operation=PAdmin_NvBlockSwComponentTypeNVBlockDescriptor_BsRt_SpeedoGauge.SetBlockProtection
        OpEventSetBlockProtection_SetBlockProtection_PAdmin_NvBlockSwComponentTypeNVBlockDescriptor_BsRt_TachoGauge: start-on-event=SetBlockProtection, operation=PAdmin_NvBlockSwComponentTypeNVBlockDescriptor_BsRt_TachoGauge.SetBlockProtection
        OpEventSetBlockProtection_SetBlockProtection_PAdmin_NvBlockSwComponentTypeNVBlockDescriptor_BsRt_TempGauge: start-on-event=SetBlockProtection, operation=PAdmin_NvBlockSwComponentTypeNVBlockDescriptor_BsRt_TempGauge.SetBlockProtection
        OpEventSetBlockProtection_SetBlockProtection_PAdmin_NvBlockSwComponentTypeNVBlockDescriptor_BsRt_TripComputer: start-on-event=SetBlockProtection, operation=PAdmin_NvBlockSwComponentTypeNVBlockDescriptor_BsRt_TripComputer.SetBlockProtection
        OpEventSetBlockProtection_SetBlockProtection_PAdmin_NvBlockSwComponentTypeNVBlockDescriptor_BsRt_Warning: start-on-event=SetBlockProtection, operation=PAdmin_NvBlockSwComponentTypeNVBlockDescriptor_BsRt_Warning.SetBlockProtection
        OpEventSetBlockProtection_SetBlockProtection_PAdmin_NvBlockSwComponentTypeNVBlockDescriptor_BsShare_EcuPartNumber: start-on-event=SetBlockProtection, operation=PAdmin_NvBlockSwComponentTypeNVBlockDescriptor_BsShare_EcuPartNumber.SetBlockProtection
        OpEventSetBlockProtection_SetBlockProtection_PAdmin_NvBlockSwComponentTypeNVBlockDescriptor_BsShare_SwUpdFotaFinPrint: start-on-event=SetBlockProtection, operation=PAdmin_NvBlockSwComponentTypeNVBlockDescriptor_BsShare_SwUpdFotaFinPrint.SetBlockProtection
        OpEventSetBlockProtection_SetBlockProtection_PAdmin_NvBlockSwComponentTypeNVBlockDescriptor_BsShare_SwUpdFotaMode: start-on-event=SetBlockProtection, operation=PAdmin_NvBlockSwComponentTypeNVBlockDescriptor_BsShare_SwUpdFotaMode.SetBlockProtection
        OpEventSetBlockProtection_SetBlockProtection_PAdmin_NvBlockSwComponentTypeNVBlockDescriptor_BsShare_SwUpdFotaStatus: start-on-event=SetBlockProtection, operation=PAdmin_NvBlockSwComponentTypeNVBlockDescriptor_BsShare_SwUpdFotaStatus.SetBlockProtection
        OpEventSetBlockProtection_SetBlockProtection_PAdmin_NvBlockSwComponentTypeNVBlockDescriptor_BsShare_SwUpdFotadecrypt: start-on-event=SetBlockProtection, operation=PAdmin_NvBlockSwComponentTypeNVBlockDescriptor_BsShare_SwUpdFotadecrypt.SetBlockProtection
        OpEventSetBlockProtection_SetBlockProtection_PAdmin_NvBlockSwComponentTypeNVBlockDescriptor_BsShare_SwUpdReflash: start-on-event=SetBlockProtection, operation=PAdmin_NvBlockSwComponentTypeNVBlockDescriptor_BsShare_SwUpdReflash.SetBlockProtection
        OpEventSetBlockProtection_SetBlockProtection_PAdmin_NvBlockSwComponentTypeNVBlockDescriptor_BsShare_VehicleConfig: start-on-event=SetBlockProtection, operation=PAdmin_NvBlockSwComponentTypeNVBlockDescriptor_BsShare_VehicleConfig.SetBlockProtection
        OpEventSetBlockProtection_SetBlockProtection_PAdmin_NvBlockSwComponentTypeNVBlockDescriptor_BsShare_VisMeet: start-on-event=SetBlockProtection, operation=PAdmin_NvBlockSwComponentTypeNVBlockDescriptor_BsShare_VisMeet.SetBlockProtection
        OpEventSetBlockProtection_SetBlockProtection_PAdmin_NvBlockSwComponentTypeNVBlockDescriptor_RefCys_Certicificate: start-on-event=SetBlockProtection, operation=PAdmin_NvBlockSwComponentTypeNVBlockDescriptor_RefCys_Certicificate.SetBlockProtection
        OpEventSetBlockProtection_SetBlockProtection_PAdmin_NvBlockSwComponentTypeNVBlockDescriptor_RefCys_Certicificate1: start-on-event=SetBlockProtection, operation=PAdmin_NvBlockSwComponentTypeNVBlockDescriptor_RefCys_Certicificate1.SetBlockProtection
        OpEventGetErrorStatus_GetErrorStatus_PS_NvBlockSwComponentTypeNVBlockDescriptor_BsConst_Illumination: start-on-event=GetErrorStatus, operation=PS_NvBlockSwComponentTypeNVBlockDescriptor_BsConst_Illumination.GetErrorStatus
        OpEventGetErrorStatus_GetErrorStatus_PS_NvBlockSwComponentTypeNVBlockDescriptor_BsConst_Illumination_Copy1: start-on-event=GetErrorStatus, operation=PS_NvBlockSwComponentTypeNVBlockDescriptor_BsConst_Illumination_Copy1.GetErrorStatus
        OpEventGetErrorStatus_GetErrorStatus_PS_NvBlockSwComponentTypeNVBlockDescriptor_BsConst_Illumination_Copy2: start-on-event=GetErrorStatus, operation=PS_NvBlockSwComponentTypeNVBlockDescriptor_BsConst_Illumination_Copy2.GetErrorStatus
        OpEventSetRamBlockStatus_SetRamBlockStatus_PS_NvBlockSwComponentTypeNVBlockDescriptor_BsConst_Illumination: start-on-event=SetRamBlockStatus, operation=PS_NvBlockSwComponentTypeNVBlockDescriptor_BsConst_Illumination.SetRamBlockStatus
        OpEventSetRamBlockStatus_SetRamBlockStatus_PS_NvBlockSwComponentTypeNVBlockDescriptor_BsConst_Illumination_Copy1: start-on-event=SetRamBlockStatus, operation=PS_NvBlockSwComponentTypeNVBlockDescriptor_BsConst_Illumination_Copy1.SetRamBlockStatus
        OpEventSetRamBlockStatus_SetRamBlockStatus_PS_NvBlockSwComponentTypeNVBlockDescriptor_BsConst_Illumination_Copy2: start-on-event=SetRamBlockStatus, operation=PS_NvBlockSwComponentTypeNVBlockDescriptor_BsConst_Illumination_Copy2.SetRamBlockStatus
        OpEventReadBlock_ReadBlock_PS_NvBlockSwComponentTypeNVBlockDescriptor_BsConst_Illumination: start-on-event=ReadBlock, operation=PS_NvBlockSwComponentTypeNVBlockDescriptor_BsConst_Illumination.ReadBlock
        OpEventReadBlock_ReadBlock_PS_NvBlockSwComponentTypeNVBlockDescriptor_BsConst_Illumination_Copy1: start-on-event=ReadBlock, operation=PS_NvBlockSwComponentTypeNVBlockDescriptor_BsConst_Illumination_Copy1.ReadBlock
        OpEventReadBlock_ReadBlock_PS_NvBlockSwComponentTypeNVBlockDescriptor_BsConst_Illumination_Copy2: start-on-event=ReadBlock, operation=PS_NvBlockSwComponentTypeNVBlockDescriptor_BsConst_Illumination_Copy2.ReadBlock
        OpEventWriteBlock_WriteBlock_PS_NvBlockSwComponentTypeNVBlockDescriptor_BsConst_Illumination: start-on-event=WriteBlock, operation=PS_NvBlockSwComponentTypeNVBlockDescriptor_BsConst_Illumination.WriteBlock
        OpEventWriteBlock_WriteBlock_PS_NvBlockSwComponentTypeNVBlockDescriptor_BsConst_Illumination_Copy1: start-on-event=WriteBlock, operation=PS_NvBlockSwComponentTypeNVBlockDescriptor_BsConst_Illumination_Copy1.WriteBlock
        OpEventWriteBlock_WriteBlock_PS_NvBlockSwComponentTypeNVBlockDescriptor_BsConst_Illumination_Copy2: start-on-event=WriteBlock, operation=PS_NvBlockSwComponentTypeNVBlockDescriptor_BsConst_Illumination_Copy2.WriteBlock
        OpEventInvalidateNvBlock_InvalidateNvBlock_PS_NvBlockSwComponentTypeNVBlockDescriptor_BsConst_Illumination: start-on-event=InvalidateNvBlock, operation=PS_NvBlockSwComponentTypeNVBlockDescriptor_BsConst_Illumination.InvalidateNvBlock
        OpEventInvalidateNvBlock_InvalidateNvBlock_PS_NvBlockSwComponentTypeNVBlockDescriptor_BsConst_Illumination_Copy1: start-on-event=InvalidateNvBlock, operation=PS_NvBlockSwComponentTypeNVBlockDescriptor_BsConst_Illumination_Copy1.InvalidateNvBlock
        OpEventInvalidateNvBlock_InvalidateNvBlock_PS_NvBlockSwComponentTypeNVBlockDescriptor_BsConst_Illumination_Copy2: start-on-event=InvalidateNvBlock, operation=PS_NvBlockSwComponentTypeNVBlockDescriptor_BsConst_Illumination_Copy2.InvalidateNvBlock
        OpEventEraseBlock_EraseBlock_PS_NvBlockSwComponentTypeNVBlockDescriptor_BsConst_Illumination: start-on-event=EraseBlock, operation=PS_NvBlockSwComponentTypeNVBlockDescriptor_BsConst_Illumination.EraseBlock
        OpEventEraseBlock_EraseBlock_PS_NvBlockSwComponentTypeNVBlockDescriptor_BsConst_Illumination_Copy1: start-on-event=EraseBlock, operation=PS_NvBlockSwComponentTypeNVBlockDescriptor_BsConst_Illumination_Copy1.EraseBlock
        OpEventEraseBlock_EraseBlock_PS_NvBlockSwComponentTypeNVBlockDescriptor_BsConst_Illumination_Copy2: start-on-event=EraseBlock, operation=PS_NvBlockSwComponentTypeNVBlockDescriptor_BsConst_Illumination_Copy2.EraseBlock
        OpEventSetBlockProtection_SetBlockProtection_PAdmin_NvBlockSwComponentTypeNVBlockDescriptor_BsConst_Illumination: start-on-event=SetBlockProtection, operation=PAdmin_NvBlockSwComponentTypeNVBlockDescriptor_BsConst_Illumination.SetBlockProtection
        OpEventSetBlockProtection_SetBlockProtection_PAdmin_NvBlockSwComponentTypeNVBlockDescriptor_BsConst_Illumination_Copy1: start-on-event=SetBlockProtection, operation=PAdmin_NvBlockSwComponentTypeNVBlockDescriptor_BsConst_Illumination_Copy1.SetBlockProtection
        OpEventSetBlockProtection_SetBlockProtection_PAdmin_NvBlockSwComponentTypeNVBlockDescriptor_BsConst_Illumination_Copy2: start-on-event=SetBlockProtection, operation=PAdmin_NvBlockSwComponentTypeNVBlockDescriptor_BsConst_Illumination_Copy2.SetBlockProtection
        OpEventRestoreBlockDefaults_RestoreBlockDefaults_PS_NvBlockSwComponentTypeNVBlockDescriptor_BsConst_Illumination: start-on-event=RestoreBlockDefaults, operation=PS_NvBlockSwComponentTypeNVBlockDescriptor_BsConst_Illumination.RestoreBlockDefaults
        OpEventRestoreBlockDefaults_RestoreBlockDefaults_PS_NvBlockSwComponentTypeNVBlockDescriptor_BsConst_Illumination_Copy1: start-on-event=RestoreBlockDefaults, operation=PS_NvBlockSwComponentTypeNVBlockDescriptor_BsConst_Illumination_Copy1.RestoreBlockDefaults
        OpEventRestoreBlockDefaults_RestoreBlockDefaults_PS_NvBlockSwComponentTypeNVBlockDescriptor_BsConst_Illumination_Copy2: start-on-event=RestoreBlockDefaults, operation=PS_NvBlockSwComponentTypeNVBlockDescriptor_BsConst_Illumination_Copy2.RestoreBlockDefaults
        OpEventSetDataIndex_SetDataIndex_PS_NvBlockSwComponentTypeNVBlockDescriptor_BsConst_Audio: start-on-event=SetDataIndex, operation=PS_NvBlockSwComponentTypeNVBlockDescriptor_BsConst_Audio.SetDataIndex
        OpEventSetDataIndex_SetDataIndex_PS_NvBlockSwComponentTypeNVBlockDescriptor_BsConst_Communication: start-on-event=SetDataIndex, operation=PS_NvBlockSwComponentTypeNVBlockDescriptor_BsConst_Communication.SetDataIndex
        OpEventSetDataIndex_SetDataIndex_PS_NvBlockSwComponentTypeNVBlockDescriptor_BsConst_EngOffTimer: start-on-event=SetDataIndex, operation=PS_NvBlockSwComponentTypeNVBlockDescriptor_BsConst_EngOffTimer.SetDataIndex
        OpEventSetDataIndex_SetDataIndex_PS_NvBlockSwComponentTypeNVBlockDescriptor_BsConst_FuelGauge: start-on-event=SetDataIndex, operation=PS_NvBlockSwComponentTypeNVBlockDescriptor_BsConst_FuelGauge.SetDataIndex
        OpEventSetDataIndex_SetDataIndex_PS_NvBlockSwComponentTypeNVBlockDescriptor_BsConst_Illumination: start-on-event=SetDataIndex, operation=PS_NvBlockSwComponentTypeNVBlockDescriptor_BsConst_Illumination.SetDataIndex
        OpEventSetDataIndex_SetDataIndex_PS_NvBlockSwComponentTypeNVBlockDescriptor_BsConst_Illumination_Copy1: start-on-event=SetDataIndex, operation=PS_NvBlockSwComponentTypeNVBlockDescriptor_BsConst_Illumination_Copy1.SetDataIndex
        OpEventSetDataIndex_SetDataIndex_PS_NvBlockSwComponentTypeNVBlockDescriptor_BsConst_Illumination_Copy2: start-on-event=SetDataIndex, operation=PS_NvBlockSwComponentTypeNVBlockDescriptor_BsConst_Illumination_Copy2.SetDataIndex
        OpEventSetDataIndex_SetDataIndex_PS_NvBlockSwComponentTypeNVBlockDescriptor_BsConst_OilGauge: start-on-event=SetDataIndex, operation=PS_NvBlockSwComponentTypeNVBlockDescriptor_BsConst_OilGauge.SetDataIndex
        OpEventSetDataIndex_SetDataIndex_PS_NvBlockSwComponentTypeNVBlockDescriptor_BsConst_Power: start-on-event=SetDataIndex, operation=PS_NvBlockSwComponentTypeNVBlockDescriptor_BsConst_Power.SetDataIndex
        OpEventSetDataIndex_SetDataIndex_PS_NvBlockSwComponentTypeNVBlockDescriptor_BsConst_PowerGauge: start-on-event=SetDataIndex, operation=PS_NvBlockSwComponentTypeNVBlockDescriptor_BsConst_PowerGauge.SetDataIndex
        OpEventSetDataIndex_SetDataIndex_PS_NvBlockSwComponentTypeNVBlockDescriptor_BsConst_RealTimeClock: start-on-event=SetDataIndex, operation=PS_NvBlockSwComponentTypeNVBlockDescriptor_BsConst_RealTimeClock.SetDataIndex
        OpEventSetDataIndex_SetDataIndex_PS_NvBlockSwComponentTypeNVBlockDescriptor_BsConst_ServiceReminder: start-on-event=SetDataIndex, operation=PS_NvBlockSwComponentTypeNVBlockDescriptor_BsConst_ServiceReminder.SetDataIndex
        OpEventSetDataIndex_SetDataIndex_PS_NvBlockSwComponentTypeNVBlockDescriptor_BsConst_SpeedoGauge: start-on-event=SetDataIndex, operation=PS_NvBlockSwComponentTypeNVBlockDescriptor_BsConst_SpeedoGauge.SetDataIndex
        OpEventSetDataIndex_SetDataIndex_PS_NvBlockSwComponentTypeNVBlockDescriptor_BsConst_TachoGauge: start-on-event=SetDataIndex, operation=PS_NvBlockSwComponentTypeNVBlockDescriptor_BsConst_TachoGauge.SetDataIndex
        OpEventSetDataIndex_SetDataIndex_PS_NvBlockSwComponentTypeNVBlockDescriptor_BsConst_TempGauge: start-on-event=SetDataIndex, operation=PS_NvBlockSwComponentTypeNVBlockDescriptor_BsConst_TempGauge.SetDataIndex
        OpEventSetDataIndex_SetDataIndex_PS_NvBlockSwComponentTypeNVBlockDescriptor_BsConst_TripComputer: start-on-event=SetDataIndex, operation=PS_NvBlockSwComponentTypeNVBlockDescriptor_BsConst_TripComputer.SetDataIndex
        OpEventSetDataIndex_SetDataIndex_PS_NvBlockSwComponentTypeNVBlockDescriptor_BsConst_Warning: start-on-event=SetDataIndex, operation=PS_NvBlockSwComponentTypeNVBlockDescriptor_BsConst_Warning.SetDataIndex
        OpEventSetDataIndex_SetDataIndex_PS_NvBlockSwComponentTypeNVBlockDescriptor_BsCys_Certicificate: start-on-event=SetDataIndex, operation=PS_NvBlockSwComponentTypeNVBlockDescriptor_BsCys_Certicificate.SetDataIndex
        OpEventSetDataIndex_SetDataIndex_PS_NvBlockSwComponentTypeNVBlockDescriptor_BsDiag_Dtc: start-on-event=SetDataIndex, operation=PS_NvBlockSwComponentTypeNVBlockDescriptor_BsDiag_Dtc.SetDataIndex
        OpEventSetDataIndex_SetDataIndex_PS_NvBlockSwComponentTypeNVBlockDescriptor_BsDiag_ErrorRecord: start-on-event=SetDataIndex, operation=PS_NvBlockSwComponentTypeNVBlockDescriptor_BsDiag_ErrorRecord.SetDataIndex
        OpEventSetDataIndex_SetDataIndex_PS_NvBlockSwComponentTypeNVBlockDescriptor_BsReten_Audio: start-on-event=SetDataIndex, operation=PS_NvBlockSwComponentTypeNVBlockDescriptor_BsReten_Audio.SetDataIndex
        OpEventSetDataIndex_SetDataIndex_PS_NvBlockSwComponentTypeNVBlockDescriptor_BsReten_Communication: start-on-event=SetDataIndex, operation=PS_NvBlockSwComponentTypeNVBlockDescriptor_BsReten_Communication.SetDataIndex
        OpEventSetDataIndex_SetDataIndex_PS_NvBlockSwComponentTypeNVBlockDescriptor_BsReten_Display: start-on-event=SetDataIndex, operation=PS_NvBlockSwComponentTypeNVBlockDescriptor_BsReten_Display.SetDataIndex
        OpEventSetDataIndex_SetDataIndex_PS_NvBlockSwComponentTypeNVBlockDescriptor_BsReten_Gauges: start-on-event=SetDataIndex, operation=PS_NvBlockSwComponentTypeNVBlockDescriptor_BsReten_Gauges.SetDataIndex
        OpEventSetDataIndex_SetDataIndex_PS_NvBlockSwComponentTypeNVBlockDescriptor_BsReten_Illumination: start-on-event=SetDataIndex, operation=PS_NvBlockSwComponentTypeNVBlockDescriptor_BsReten_Illumination.SetDataIndex
        OpEventSetDataIndex_SetDataIndex_PS_NvBlockSwComponentTypeNVBlockDescriptor_BsReten_Odometer: start-on-event=SetDataIndex, operation=PS_NvBlockSwComponentTypeNVBlockDescriptor_BsReten_Odometer.SetDataIndex
        OpEventSetDataIndex_SetDataIndex_PS_NvBlockSwComponentTypeNVBlockDescriptor_BsReten_Personalization: start-on-event=SetDataIndex, operation=PS_NvBlockSwComponentTypeNVBlockDescriptor_BsReten_Personalization.SetDataIndex
        OpEventSetDataIndex_SetDataIndex_PS_NvBlockSwComponentTypeNVBlockDescriptor_BsReten_Power: start-on-event=SetDataIndex, operation=PS_NvBlockSwComponentTypeNVBlockDescriptor_BsReten_Power.SetDataIndex
        OpEventSetDataIndex_SetDataIndex_PS_NvBlockSwComponentTypeNVBlockDescriptor_BsReten_RealTimeClock: start-on-event=SetDataIndex, operation=PS_NvBlockSwComponentTypeNVBlockDescriptor_BsReten_RealTimeClock.SetDataIndex
        OpEventSetDataIndex_SetDataIndex_PS_NvBlockSwComponentTypeNVBlockDescriptor_BsReten_Tripcomputer: start-on-event=SetDataIndex, operation=PS_NvBlockSwComponentTypeNVBlockDescriptor_BsReten_Tripcomputer.SetDataIndex
        OpEventSetDataIndex_SetDataIndex_PS_NvBlockSwComponentTypeNVBlockDescriptor_BsReten_Warning: start-on-event=SetDataIndex, operation=PS_NvBlockSwComponentTypeNVBlockDescriptor_BsReten_Warning.SetDataIndex
        OpEventSetDataIndex_SetDataIndex_PS_NvBlockSwComponentTypeNVBlockDescriptor_BsRt_CusDlt: start-on-event=SetDataIndex, operation=PS_NvBlockSwComponentTypeNVBlockDescriptor_BsRt_CusDlt.SetDataIndex
        OpEventSetDataIndex_SetDataIndex_PS_NvBlockSwComponentTypeNVBlockDescriptor_BsRt_FuelGauge: start-on-event=SetDataIndex, operation=PS_NvBlockSwComponentTypeNVBlockDescriptor_BsRt_FuelGauge.SetDataIndex
        OpEventSetDataIndex_SetDataIndex_PS_NvBlockSwComponentTypeNVBlockDescriptor_BsRt_Illumination: start-on-event=SetDataIndex, operation=PS_NvBlockSwComponentTypeNVBlockDescriptor_BsRt_Illumination.SetDataIndex
        OpEventSetDataIndex_SetDataIndex_PS_NvBlockSwComponentTypeNVBlockDescriptor_BsRt_Odometer: start-on-event=SetDataIndex, operation=PS_NvBlockSwComponentTypeNVBlockDescriptor_BsRt_Odometer.SetDataIndex
        OpEventSetDataIndex_SetDataIndex_PS_NvBlockSwComponentTypeNVBlockDescriptor_BsRt_OilGauge: start-on-event=SetDataIndex, operation=PS_NvBlockSwComponentTypeNVBlockDescriptor_BsRt_OilGauge.SetDataIndex
        OpEventSetDataIndex_SetDataIndex_PS_NvBlockSwComponentTypeNVBlockDescriptor_BsRt_Personalization: start-on-event=SetDataIndex, operation=PS_NvBlockSwComponentTypeNVBlockDescriptor_BsRt_Personalization.SetDataIndex
        OpEventSetDataIndex_SetDataIndex_PS_NvBlockSwComponentTypeNVBlockDescriptor_BsRt_PowerGauge: start-on-event=SetDataIndex, operation=PS_NvBlockSwComponentTypeNVBlockDescriptor_BsRt_PowerGauge.SetDataIndex
        OpEventSetDataIndex_SetDataIndex_PS_NvBlockSwComponentTypeNVBlockDescriptor_BsRt_RealTimeClock: start-on-event=SetDataIndex, operation=PS_NvBlockSwComponentTypeNVBlockDescriptor_BsRt_RealTimeClock.SetDataIndex
        OpEventSetDataIndex_SetDataIndex_PS_NvBlockSwComponentTypeNVBlockDescriptor_BsRt_SpeedoGauge: start-on-event=SetDataIndex, operation=PS_NvBlockSwComponentTypeNVBlockDescriptor_BsRt_SpeedoGauge.SetDataIndex
        OpEventSetDataIndex_SetDataIndex_PS_NvBlockSwComponentTypeNVBlockDescriptor_BsRt_TachoGauge: start-on-event=SetDataIndex, operation=PS_NvBlockSwComponentTypeNVBlockDescriptor_BsRt_TachoGauge.SetDataIndex
        OpEventSetDataIndex_SetDataIndex_PS_NvBlockSwComponentTypeNVBlockDescriptor_BsRt_TempGauge: start-on-event=SetDataIndex, operation=PS_NvBlockSwComponentTypeNVBlockDescriptor_BsRt_TempGauge.SetDataIndex
        OpEventSetDataIndex_SetDataIndex_PS_NvBlockSwComponentTypeNVBlockDescriptor_BsRt_TripComputer: start-on-event=SetDataIndex, operation=PS_NvBlockSwComponentTypeNVBlockDescriptor_BsRt_TripComputer.SetDataIndex
        OpEventSetDataIndex_SetDataIndex_PS_NvBlockSwComponentTypeNVBlockDescriptor_BsRt_Warning: start-on-event=SetDataIndex, operation=PS_NvBlockSwComponentTypeNVBlockDescriptor_BsRt_Warning.SetDataIndex
        OpEventSetDataIndex_SetDataIndex_PS_NvBlockSwComponentTypeNVBlockDescriptor_BsShare_EcuPartNumber: start-on-event=SetDataIndex, operation=PS_NvBlockSwComponentTypeNVBlockDescriptor_BsShare_EcuPartNumber.SetDataIndex
        OpEventSetDataIndex_SetDataIndex_PS_NvBlockSwComponentTypeNVBlockDescriptor_BsShare_SwUpdFotaFinPrint: start-on-event=SetDataIndex, operation=PS_NvBlockSwComponentTypeNVBlockDescriptor_BsShare_SwUpdFotaFinPrint.SetDataIndex
        OpEventSetDataIndex_SetDataIndex_PS_NvBlockSwComponentTypeNVBlockDescriptor_BsShare_SwUpdFotaMode: start-on-event=SetDataIndex, operation=PS_NvBlockSwComponentTypeNVBlockDescriptor_BsShare_SwUpdFotaMode.SetDataIndex
        OpEventSetDataIndex_SetDataIndex_PS_NvBlockSwComponentTypeNVBlockDescriptor_BsShare_SwUpdFotaStatus: start-on-event=SetDataIndex, operation=PS_NvBlockSwComponentTypeNVBlockDescriptor_BsShare_SwUpdFotaStatus.SetDataIndex
        OpEventSetDataIndex_SetDataIndex_PS_NvBlockSwComponentTypeNVBlockDescriptor_BsShare_SwUpdFotadecrypt: start-on-event=SetDataIndex, operation=PS_NvBlockSwComponentTypeNVBlockDescriptor_BsShare_SwUpdFotadecrypt.SetDataIndex
        OpEventSetDataIndex_SetDataIndex_PS_NvBlockSwComponentTypeNVBlockDescriptor_BsShare_SwUpdReflash: start-on-event=SetDataIndex, operation=PS_NvBlockSwComponentTypeNVBlockDescriptor_BsShare_SwUpdReflash.SetDataIndex
        OpEventSetDataIndex_SetDataIndex_PS_NvBlockSwComponentTypeNVBlockDescriptor_BsShare_VehicleConfig: start-on-event=SetDataIndex, operation=PS_NvBlockSwComponentTypeNVBlockDescriptor_BsShare_VehicleConfig.SetDataIndex
        OpEventSetDataIndex_SetDataIndex_PS_NvBlockSwComponentTypeNVBlockDescriptor_BsShare_VisMeet: start-on-event=SetDataIndex, operation=PS_NvBlockSwComponentTypeNVBlockDescriptor_BsShare_VisMeet.SetDataIndex
        OpEventSetDataIndex_SetDataIndex_PS_NvBlockSwComponentTypeNVBlockDescriptor_RefCys_Certicificate: start-on-event=SetDataIndex, operation=PS_NvBlockSwComponentTypeNVBlockDescriptor_RefCys_Certicificate.SetDataIndex
        OpEventSetDataIndex_SetDataIndex_PS_NvBlockSwComponentTypeNVBlockDescriptor_RefCys_Certicificate1: start-on-event=SetDataIndex, operation=PS_NvBlockSwComponentTypeNVBlockDescriptor_RefCys_Certicificate1.SetDataIndex
        OpEventGetDataIndex_GetDataIndex_PS_NvBlockSwComponentTypeNVBlockDescriptor_BsConst_Audio: start-on-event=GetDataIndex, operation=PS_NvBlockSwComponentTypeNVBlockDescriptor_BsConst_Audio.GetDataIndex
        OpEventGetDataIndex_GetDataIndex_PS_NvBlockSwComponentTypeNVBlockDescriptor_BsConst_Communication: start-on-event=GetDataIndex, operation=PS_NvBlockSwComponentTypeNVBlockDescriptor_BsConst_Communication.GetDataIndex
        OpEventGetDataIndex_GetDataIndex_PS_NvBlockSwComponentTypeNVBlockDescriptor_BsConst_EngOffTimer: start-on-event=GetDataIndex, operation=PS_NvBlockSwComponentTypeNVBlockDescriptor_BsConst_EngOffTimer.GetDataIndex
        OpEventGetDataIndex_GetDataIndex_PS_NvBlockSwComponentTypeNVBlockDescriptor_BsConst_FuelGauge: start-on-event=GetDataIndex, operation=PS_NvBlockSwComponentTypeNVBlockDescriptor_BsConst_FuelGauge.GetDataIndex
        OpEventGetDataIndex_GetDataIndex_PS_NvBlockSwComponentTypeNVBlockDescriptor_BsConst_Illumination: start-on-event=GetDataIndex, operation=PS_NvBlockSwComponentTypeNVBlockDescriptor_BsConst_Illumination.GetDataIndex
        OpEventGetDataIndex_GetDataIndex_PS_NvBlockSwComponentTypeNVBlockDescriptor_BsConst_Illumination_Copy1: start-on-event=GetDataIndex, operation=PS_NvBlockSwComponentTypeNVBlockDescriptor_BsConst_Illumination_Copy1.GetDataIndex
        OpEventGetDataIndex_GetDataIndex_PS_NvBlockSwComponentTypeNVBlockDescriptor_BsConst_Illumination_Copy2: start-on-event=GetDataIndex, operation=PS_NvBlockSwComponentTypeNVBlockDescriptor_BsConst_Illumination_Copy2.GetDataIndex
        OpEventGetDataIndex_GetDataIndex_PS_NvBlockSwComponentTypeNVBlockDescriptor_BsConst_OilGauge: start-on-event=GetDataIndex, operation=PS_NvBlockSwComponentTypeNVBlockDescriptor_BsConst_OilGauge.GetDataIndex
        OpEventGetDataIndex_GetDataIndex_PS_NvBlockSwComponentTypeNVBlockDescriptor_BsConst_Power: start-on-event=GetDataIndex, operation=PS_NvBlockSwComponentTypeNVBlockDescriptor_BsConst_Power.GetDataIndex
        OpEventGetDataIndex_GetDataIndex_PS_NvBlockSwComponentTypeNVBlockDescriptor_BsConst_PowerGauge: start-on-event=GetDataIndex, operation=PS_NvBlockSwComponentTypeNVBlockDescriptor_BsConst_PowerGauge.GetDataIndex
        OpEventGetDataIndex_GetDataIndex_PS_NvBlockSwComponentTypeNVBlockDescriptor_BsConst_RealTimeClock: start-on-event=GetDataIndex, operation=PS_NvBlockSwComponentTypeNVBlockDescriptor_BsConst_RealTimeClock.GetDataIndex
        OpEventGetDataIndex_GetDataIndex_PS_NvBlockSwComponentTypeNVBlockDescriptor_BsConst_ServiceReminder: start-on-event=GetDataIndex, operation=PS_NvBlockSwComponentTypeNVBlockDescriptor_BsConst_ServiceReminder.GetDataIndex
        OpEventGetDataIndex_GetDataIndex_PS_NvBlockSwComponentTypeNVBlockDescriptor_BsConst_SpeedoGauge: start-on-event=GetDataIndex, operation=PS_NvBlockSwComponentTypeNVBlockDescriptor_BsConst_SpeedoGauge.GetDataIndex
        OpEventGetDataIndex_GetDataIndex_PS_NvBlockSwComponentTypeNVBlockDescriptor_BsConst_TachoGauge: start-on-event=GetDataIndex, operation=PS_NvBlockSwComponentTypeNVBlockDescriptor_BsConst_TachoGauge.GetDataIndex
        OpEventGetDataIndex_GetDataIndex_PS_NvBlockSwComponentTypeNVBlockDescriptor_BsConst_TempGauge: start-on-event=GetDataIndex, operation=PS_NvBlockSwComponentTypeNVBlockDescriptor_BsConst_TempGauge.GetDataIndex
        OpEventGetDataIndex_GetDataIndex_PS_NvBlockSwComponentTypeNVBlockDescriptor_BsConst_TripComputer: start-on-event=GetDataIndex, operation=PS_NvBlockSwComponentTypeNVBlockDescriptor_BsConst_TripComputer.GetDataIndex
        OpEventGetDataIndex_GetDataIndex_PS_NvBlockSwComponentTypeNVBlockDescriptor_BsConst_Warning: start-on-event=GetDataIndex, operation=PS_NvBlockSwComponentTypeNVBlockDescriptor_BsConst_Warning.GetDataIndex
        OpEventGetDataIndex_GetDataIndex_PS_NvBlockSwComponentTypeNVBlockDescriptor_BsCys_Certicificate: start-on-event=GetDataIndex, operation=PS_NvBlockSwComponentTypeNVBlockDescriptor_BsCys_Certicificate.GetDataIndex
        OpEventGetDataIndex_GetDataIndex_PS_NvBlockSwComponentTypeNVBlockDescriptor_BsDiag_Dtc: start-on-event=GetDataIndex, operation=PS_NvBlockSwComponentTypeNVBlockDescriptor_BsDiag_Dtc.GetDataIndex
        OpEventGetDataIndex_GetDataIndex_PS_NvBlockSwComponentTypeNVBlockDescriptor_BsDiag_ErrorRecord: start-on-event=GetDataIndex, operation=PS_NvBlockSwComponentTypeNVBlockDescriptor_BsDiag_ErrorRecord.GetDataIndex
        OpEventGetDataIndex_GetDataIndex_PS_NvBlockSwComponentTypeNVBlockDescriptor_BsReten_Audio: start-on-event=GetDataIndex, operation=PS_NvBlockSwComponentTypeNVBlockDescriptor_BsReten_Audio.GetDataIndex
        OpEventGetDataIndex_GetDataIndex_PS_NvBlockSwComponentTypeNVBlockDescriptor_BsReten_Communication: start-on-event=GetDataIndex, operation=PS_NvBlockSwComponentTypeNVBlockDescriptor_BsReten_Communication.GetDataIndex
        OpEventGetDataIndex_GetDataIndex_PS_NvBlockSwComponentTypeNVBlockDescriptor_BsReten_Display: start-on-event=GetDataIndex, operation=PS_NvBlockSwComponentTypeNVBlockDescriptor_BsReten_Display.GetDataIndex
        OpEventGetDataIndex_GetDataIndex_PS_NvBlockSwComponentTypeNVBlockDescriptor_BsReten_Gauges: start-on-event=GetDataIndex, operation=PS_NvBlockSwComponentTypeNVBlockDescriptor_BsReten_Gauges.GetDataIndex
        OpEventGetDataIndex_GetDataIndex_PS_NvBlockSwComponentTypeNVBlockDescriptor_BsReten_Illumination: start-on-event=GetDataIndex, operation=PS_NvBlockSwComponentTypeNVBlockDescriptor_BsReten_Illumination.GetDataIndex
        OpEventGetDataIndex_GetDataIndex_PS_NvBlockSwComponentTypeNVBlockDescriptor_BsReten_Odometer: start-on-event=GetDataIndex, operation=PS_NvBlockSwComponentTypeNVBlockDescriptor_BsReten_Odometer.GetDataIndex
        OpEventGetDataIndex_GetDataIndex_PS_NvBlockSwComponentTypeNVBlockDescriptor_BsReten_Personalization: start-on-event=GetDataIndex, operation=PS_NvBlockSwComponentTypeNVBlockDescriptor_BsReten_Personalization.GetDataIndex
        OpEventGetDataIndex_GetDataIndex_PS_NvBlockSwComponentTypeNVBlockDescriptor_BsReten_Power: start-on-event=GetDataIndex, operation=PS_NvBlockSwComponentTypeNVBlockDescriptor_BsReten_Power.GetDataIndex
        OpEventGetDataIndex_GetDataIndex_PS_NvBlockSwComponentTypeNVBlockDescriptor_BsReten_RealTimeClock: start-on-event=GetDataIndex, operation=PS_NvBlockSwComponentTypeNVBlockDescriptor_BsReten_RealTimeClock.GetDataIndex
        OpEventGetDataIndex_GetDataIndex_PS_NvBlockSwComponentTypeNVBlockDescriptor_BsReten_Tripcomputer: start-on-event=GetDataIndex, operation=PS_NvBlockSwComponentTypeNVBlockDescriptor_BsReten_Tripcomputer.GetDataIndex
        OpEventGetDataIndex_GetDataIndex_PS_NvBlockSwComponentTypeNVBlockDescriptor_BsReten_Warning: start-on-event=GetDataIndex, operation=PS_NvBlockSwComponentTypeNVBlockDescriptor_BsReten_Warning.GetDataIndex
        OpEventGetDataIndex_GetDataIndex_PS_NvBlockSwComponentTypeNVBlockDescriptor_BsRt_CusDlt: start-on-event=GetDataIndex, operation=PS_NvBlockSwComponentTypeNVBlockDescriptor_BsRt_CusDlt.GetDataIndex
        OpEventGetDataIndex_GetDataIndex_PS_NvBlockSwComponentTypeNVBlockDescriptor_BsRt_FuelGauge: start-on-event=GetDataIndex, operation=PS_NvBlockSwComponentTypeNVBlockDescriptor_BsRt_FuelGauge.GetDataIndex
        OpEventGetDataIndex_GetDataIndex_PS_NvBlockSwComponentTypeNVBlockDescriptor_BsRt_Illumination: start-on-event=GetDataIndex, operation=PS_NvBlockSwComponentTypeNVBlockDescriptor_BsRt_Illumination.GetDataIndex
        OpEventGetDataIndex_GetDataIndex_PS_NvBlockSwComponentTypeNVBlockDescriptor_BsRt_Odometer: start-on-event=GetDataIndex, operation=PS_NvBlockSwComponentTypeNVBlockDescriptor_BsRt_Odometer.GetDataIndex
        OpEventGetDataIndex_GetDataIndex_PS_NvBlockSwComponentTypeNVBlockDescriptor_BsRt_OilGauge: start-on-event=GetDataIndex, operation=PS_NvBlockSwComponentTypeNVBlockDescriptor_BsRt_OilGauge.GetDataIndex
        OpEventGetDataIndex_GetDataIndex_PS_NvBlockSwComponentTypeNVBlockDescriptor_BsRt_Personalization: start-on-event=GetDataIndex, operation=PS_NvBlockSwComponentTypeNVBlockDescriptor_BsRt_Personalization.GetDataIndex
        OpEventGetDataIndex_GetDataIndex_PS_NvBlockSwComponentTypeNVBlockDescriptor_BsRt_PowerGauge: start-on-event=GetDataIndex, operation=PS_NvBlockSwComponentTypeNVBlockDescriptor_BsRt_PowerGauge.GetDataIndex
        OpEventGetDataIndex_GetDataIndex_PS_NvBlockSwComponentTypeNVBlockDescriptor_BsRt_RealTimeClock: start-on-event=GetDataIndex, operation=PS_NvBlockSwComponentTypeNVBlockDescriptor_BsRt_RealTimeClock.GetDataIndex
        OpEventGetDataIndex_GetDataIndex_PS_NvBlockSwComponentTypeNVBlockDescriptor_BsRt_SpeedoGauge: start-on-event=GetDataIndex, operation=PS_NvBlockSwComponentTypeNVBlockDescriptor_BsRt_SpeedoGauge.GetDataIndex
        OpEventGetDataIndex_GetDataIndex_PS_NvBlockSwComponentTypeNVBlockDescriptor_BsRt_TachoGauge: start-on-event=GetDataIndex, operation=PS_NvBlockSwComponentTypeNVBlockDescriptor_BsRt_TachoGauge.GetDataIndex
        OpEventGetDataIndex_GetDataIndex_PS_NvBlockSwComponentTypeNVBlockDescriptor_BsRt_TempGauge: start-on-event=GetDataIndex, operation=PS_NvBlockSwComponentTypeNVBlockDescriptor_BsRt_TempGauge.GetDataIndex
        OpEventGetDataIndex_GetDataIndex_PS_NvBlockSwComponentTypeNVBlockDescriptor_BsRt_TripComputer: start-on-event=GetDataIndex, operation=PS_NvBlockSwComponentTypeNVBlockDescriptor_BsRt_TripComputer.GetDataIndex
        OpEventGetDataIndex_GetDataIndex_PS_NvBlockSwComponentTypeNVBlockDescriptor_BsRt_Warning: start-on-event=GetDataIndex, operation=PS_NvBlockSwComponentTypeNVBlockDescriptor_BsRt_Warning.GetDataIndex
        OpEventGetDataIndex_GetDataIndex_PS_NvBlockSwComponentTypeNVBlockDescriptor_BsShare_EcuPartNumber: start-on-event=GetDataIndex, operation=PS_NvBlockSwComponentTypeNVBlockDescriptor_BsShare_EcuPartNumber.GetDataIndex
        OpEventGetDataIndex_GetDataIndex_PS_NvBlockSwComponentTypeNVBlockDescriptor_BsShare_SwUpdFotaFinPrint: start-on-event=GetDataIndex, operation=PS_NvBlockSwComponentTypeNVBlockDescriptor_BsShare_SwUpdFotaFinPrint.GetDataIndex
        OpEventGetDataIndex_GetDataIndex_PS_NvBlockSwComponentTypeNVBlockDescriptor_BsShare_SwUpdFotaMode: start-on-event=GetDataIndex, operation=PS_NvBlockSwComponentTypeNVBlockDescriptor_BsShare_SwUpdFotaMode.GetDataIndex
        OpEventGetDataIndex_GetDataIndex_PS_NvBlockSwComponentTypeNVBlockDescriptor_BsShare_SwUpdFotaStatus: start-on-event=GetDataIndex, operation=PS_NvBlockSwComponentTypeNVBlockDescriptor_BsShare_SwUpdFotaStatus.GetDataIndex
        OpEventGetDataIndex_GetDataIndex_PS_NvBlockSwComponentTypeNVBlockDescriptor_BsShare_SwUpdFotadecrypt: start-on-event=GetDataIndex, operation=PS_NvBlockSwComponentTypeNVBlockDescriptor_BsShare_SwUpdFotadecrypt.GetDataIndex
        OpEventGetDataIndex_GetDataIndex_PS_NvBlockSwComponentTypeNVBlockDescriptor_BsShare_SwUpdReflash: start-on-event=GetDataIndex, operation=PS_NvBlockSwComponentTypeNVBlockDescriptor_BsShare_SwUpdReflash.GetDataIndex
        OpEventGetDataIndex_GetDataIndex_PS_NvBlockSwComponentTypeNVBlockDescriptor_BsShare_VehicleConfig: start-on-event=GetDataIndex, operation=PS_NvBlockSwComponentTypeNVBlockDescriptor_BsShare_VehicleConfig.GetDataIndex
        OpEventGetDataIndex_GetDataIndex_PS_NvBlockSwComponentTypeNVBlockDescriptor_BsShare_VisMeet: start-on-event=GetDataIndex, operation=PS_NvBlockSwComponentTypeNVBlockDescriptor_BsShare_VisMeet.GetDataIndex
        OpEventGetDataIndex_GetDataIndex_PS_NvBlockSwComponentTypeNVBlockDescriptor_RefCys_Certicificate: start-on-event=GetDataIndex, operation=PS_NvBlockSwComponentTypeNVBlockDescriptor_RefCys_Certicificate.GetDataIndex
        OpEventGetDataIndex_GetDataIndex_PS_NvBlockSwComponentTypeNVBlockDescriptor_RefCys_Certicificate1: start-on-event=GetDataIndex, operation=PS_NvBlockSwComponentTypeNVBlockDescriptor_RefCys_Certicificate1.GetDataIndex
      port-api-options:
        {enable-take-address=true, indirect-api=false, port-defined-argument-value{value=2, value-type=NvM_BlockIdType}, port=PAdmin_NvBlockSwComponentTypeNVBlockDescriptor_BsShare_SwUpdReflash}
        {enable-take-address=true, indirect-api=false, port-defined-argument-value{value=21, value-type=NvM_BlockIdType}, port=PAdmin_NvBlockSwComponentTypeNVBlockDescriptor_BsConst_Audio}
        {enable-take-address=true, indirect-api=false, port-defined-argument-value{value=24, value-type=NvM_BlockIdType}, port=PAdmin_NvBlockSwComponentTypeNVBlockDescriptor_BsConst_Communication}
        {enable-take-address=true, indirect-api=false, port-defined-argument-value{value=27, value-type=NvM_BlockIdType}, port=PAdmin_NvBlockSwComponentTypeNVBlockDescriptor_BsConst_EngOffTimer}
        {enable-take-address=true, indirect-api=false, port-defined-argument-value{value=25, value-type=NvM_BlockIdType}, port=PAdmin_NvBlockSwComponentTypeNVBlockDescriptor_BsConst_Power}
        {enable-take-address=true, indirect-api=false, port-defined-argument-value{value=23, value-type=NvM_BlockIdType}, port=PAdmin_NvBlockSwComponentTypeNVBlockDescriptor_BsConst_RealTimeClock}
        {enable-take-address=true, indirect-api=false, port-defined-argument-value{value=26, value-type=NvM_BlockIdType}, port=PAdmin_NvBlockSwComponentTypeNVBlockDescriptor_BsConst_ServiceReminder}
        {enable-take-address=true, indirect-api=false, port-defined-argument-value{value=22, value-type=NvM_BlockIdType}, port=PAdmin_NvBlockSwComponentTypeNVBlockDescriptor_BsConst_Warning}
        {enable-take-address=true, indirect-api=false, port-defined-argument-value{value=28, value-type=NvM_BlockIdType}, port=PAdmin_NvBlockSwComponentTypeNVBlockDescriptor_BsCys_Certicificate}
        {enable-take-address=true, indirect-api=false, port-defined-argument-value{value=48, value-type=NvM_BlockIdType}, port=PAdmin_NvBlockSwComponentTypeNVBlockDescriptor_BsReten_Audio}
        {enable-take-address=true, indirect-api=false, port-defined-argument-value{value=51, value-type=NvM_BlockIdType}, port=PAdmin_NvBlockSwComponentTypeNVBlockDescriptor_BsReten_Communication}
        {enable-take-address=true, indirect-api=false, port-defined-argument-value{value=45, value-type=NvM_BlockIdType}, port=PAdmin_NvBlockSwComponentTypeNVBlockDescriptor_BsReten_Gauges}
        {enable-take-address=true, indirect-api=false, port-defined-argument-value{value=47, value-type=NvM_BlockIdType}, port=PAdmin_NvBlockSwComponentTypeNVBlockDescriptor_BsReten_Illumination}
        {enable-take-address=true, indirect-api=false, port-defined-argument-value{value=44, value-type=NvM_BlockIdType}, port=PAdmin_NvBlockSwComponentTypeNVBlockDescriptor_BsReten_Odometer}
        {enable-take-address=true, indirect-api=false, port-defined-argument-value{value=52, value-type=NvM_BlockIdType}, port=PAdmin_NvBlockSwComponentTypeNVBlockDescriptor_BsReten_Personalization}
        {enable-take-address=true, indirect-api=false, port-defined-argument-value{value=50, value-type=NvM_BlockIdType}, port=PAdmin_NvBlockSwComponentTypeNVBlockDescriptor_BsReten_RealTimeClock}
        {enable-take-address=true, indirect-api=false, port-defined-argument-value{value=46, value-type=NvM_BlockIdType}, port=PAdmin_NvBlockSwComponentTypeNVBlockDescriptor_BsReten_Tripcomputer}
        {enable-take-address=true, indirect-api=false, port-defined-argument-value{value=49, value-type=NvM_BlockIdType}, port=PAdmin_NvBlockSwComponentTypeNVBlockDescriptor_BsReten_Warning}
        {enable-take-address=true, indirect-api=false, port-defined-argument-value{value=43, value-type=NvM_BlockIdType}, port=PAdmin_NvBlockSwComponentTypeNVBlockDescriptor_BsRt_CusDlt}
        {enable-take-address=true, indirect-api=false, port-defined-argument-value{value=34, value-type=NvM_BlockIdType}, port=PAdmin_NvBlockSwComponentTypeNVBlockDescriptor_BsRt_FuelGauge}
        {enable-take-address=true, indirect-api=false, port-defined-argument-value{value=42, value-type=NvM_BlockIdType}, port=PAdmin_NvBlockSwComponentTypeNVBlockDescriptor_BsRt_Illumination}
        {enable-take-address=true, indirect-api=false, port-defined-argument-value{value=31, value-type=NvM_BlockIdType}, port=PAdmin_NvBlockSwComponentTypeNVBlockDescriptor_BsRt_Odometer}
        {enable-take-address=true, indirect-api=false, port-defined-argument-value{value=37, value-type=NvM_BlockIdType}, port=PAdmin_NvBlockSwComponentTypeNVBlockDescriptor_BsRt_OilGauge}
        {enable-take-address=true, indirect-api=false, port-defined-argument-value{value=41, value-type=NvM_BlockIdType}, port=PAdmin_NvBlockSwComponentTypeNVBlockDescriptor_BsRt_Personalization}
        {enable-take-address=true, indirect-api=false, port-defined-argument-value{value=36, value-type=NvM_BlockIdType}, port=PAdmin_NvBlockSwComponentTypeNVBlockDescriptor_BsRt_PowerGauge}
        {enable-take-address=true, indirect-api=false, port-defined-argument-value{value=40, value-type=NvM_BlockIdType}, port=PAdmin_NvBlockSwComponentTypeNVBlockDescriptor_BsRt_RealTimeClock}
        {enable-take-address=true, indirect-api=false, port-defined-argument-value{value=32, value-type=NvM_BlockIdType}, port=PAdmin_NvBlockSwComponentTypeNVBlockDescriptor_BsRt_SpeedoGauge}
        {enable-take-address=true, indirect-api=false, port-defined-argument-value{value=33, value-type=NvM_BlockIdType}, port=PAdmin_NvBlockSwComponentTypeNVBlockDescriptor_BsRt_TachoGauge}
        {enable-take-address=true, indirect-api=false, port-defined-argument-value{value=35, value-type=NvM_BlockIdType}, port=PAdmin_NvBlockSwComponentTypeNVBlockDescriptor_BsRt_TempGauge}
        {enable-take-address=true, indirect-api=false, port-defined-argument-value{value=38, value-type=NvM_BlockIdType}, port=PAdmin_NvBlockSwComponentTypeNVBlockDescriptor_BsRt_TripComputer}
        {enable-take-address=true, indirect-api=false, port-defined-argument-value{value=39, value-type=NvM_BlockIdType}, port=PAdmin_NvBlockSwComponentTypeNVBlockDescriptor_BsRt_Warning}
        {enable-take-address=true, indirect-api=false, port-defined-argument-value{value=29, value-type=NvM_BlockIdType}, port=PAdmin_NvBlockSwComponentTypeNVBlockDescriptor_RefCys_Certicificate}
        {enable-take-address=true, indirect-api=false, port-defined-argument-value{value=30, value-type=NvM_BlockIdType}, port=PAdmin_NvBlockSwComponentTypeNVBlockDescriptor_RefCys_Certicificate1}
        {enable-take-address=true, indirect-api=false, port-defined-argument-value{value=13, value-type=NvM_BlockIdType}, port=PAdmin_NvBlockSwComponentTypeNVBlockDescriptor_BsConst_FuelGauge}
        {enable-take-address=true, indirect-api=false, port-defined-argument-value{value=18, value-type=NvM_BlockIdType}, port=PAdmin_NvBlockSwComponentTypeNVBlockDescriptor_BsConst_Illumination}
        {enable-take-address=true, indirect-api=false, port-defined-argument-value{value=19, value-type=NvM_BlockIdType}, port=PAdmin_NvBlockSwComponentTypeNVBlockDescriptor_BsConst_Illumination_Copy1}
        {enable-take-address=true, indirect-api=false, port-defined-argument-value{value=20, value-type=NvM_BlockIdType}, port=PAdmin_NvBlockSwComponentTypeNVBlockDescriptor_BsConst_Illumination_Copy2}
        {enable-take-address=true, indirect-api=false, port-defined-argument-value{value=16, value-type=NvM_BlockIdType}, port=PAdmin_NvBlockSwComponentTypeNVBlockDescriptor_BsConst_OilGauge}
        {enable-take-address=true, indirect-api=false, port-defined-argument-value{value=15, value-type=NvM_BlockIdType}, port=PAdmin_NvBlockSwComponentTypeNVBlockDescriptor_BsConst_PowerGauge}
        {enable-take-address=true, indirect-api=false, port-defined-argument-value{value=11, value-type=NvM_BlockIdType}, port=PAdmin_NvBlockSwComponentTypeNVBlockDescriptor_BsConst_SpeedoGauge}
        {enable-take-address=true, indirect-api=false, port-defined-argument-value{value=12, value-type=NvM_BlockIdType}, port=PAdmin_NvBlockSwComponentTypeNVBlockDescriptor_BsConst_TachoGauge}
        {enable-take-address=true, indirect-api=false, port-defined-argument-value{value=14, value-type=NvM_BlockIdType}, port=PAdmin_NvBlockSwComponentTypeNVBlockDescriptor_BsConst_TempGauge}
        {enable-take-address=true, indirect-api=false, port-defined-argument-value{value=17, value-type=NvM_BlockIdType}, port=PAdmin_NvBlockSwComponentTypeNVBlockDescriptor_BsConst_TripComputer}
        {enable-take-address=true, indirect-api=false, port-defined-argument-value{value=8, value-type=NvM_BlockIdType}, port=PAdmin_NvBlockSwComponentTypeNVBlockDescriptor_BsShare_EcuPartNumber}
        {enable-take-address=true, indirect-api=false, port-defined-argument-value{value=5, value-type=NvM_BlockIdType}, port=PAdmin_NvBlockSwComponentTypeNVBlockDescriptor_BsShare_SwUpdFotaFinPrint}
        {enable-take-address=true, indirect-api=false, port-defined-argument-value{value=4, value-type=NvM_BlockIdType}, port=PAdmin_NvBlockSwComponentTypeNVBlockDescriptor_BsShare_SwUpdFotaMode}
        {enable-take-address=true, indirect-api=false, port-defined-argument-value{value=6, value-type=NvM_BlockIdType}, port=PAdmin_NvBlockSwComponentTypeNVBlockDescriptor_BsShare_SwUpdFotaStatus}
        {enable-take-address=true, indirect-api=false, port-defined-argument-value{value=7, value-type=NvM_BlockIdType}, port=PAdmin_NvBlockSwComponentTypeNVBlockDescriptor_BsShare_SwUpdFotadecrypt}
        {enable-take-address=true, indirect-api=false, port-defined-argument-value{value=10, value-type=NvM_BlockIdType}, port=PAdmin_NvBlockSwComponentTypeNVBlockDescriptor_BsShare_VehicleConfig}
        {enable-take-address=true, indirect-api=false, port-defined-argument-value{value=9, value-type=NvM_BlockIdType}, port=PAdmin_NvBlockSwComponentTypeNVBlockDescriptor_BsShare_VisMeet}
        {enable-take-address=true, indirect-api=false, port-defined-argument-value{value=56, value-type=NvM_BlockIdType}, port=PAdmin_NvBlockSwComponentTypeNVBlockDescriptor_BsDiag_Dtc}
        {enable-take-address=true, indirect-api=false, port-defined-argument-value{value=55, value-type=NvM_BlockIdType}, port=PAdmin_NvBlockSwComponentTypeNVBlockDescriptor_BsDiag_ErrorRecord}
        {enable-take-address=true, indirect-api=false, port-defined-argument-value{value=54, value-type=NvM_BlockIdType}, port=PAdmin_NvBlockSwComponentTypeNVBlockDescriptor_BsReten_Display}
        {enable-take-address=true, indirect-api=false, port-defined-argument-value{value=53, value-type=NvM_BlockIdType}, port=PAdmin_NvBlockSwComponentTypeNVBlockDescriptor_BsReten_Power}
        {enable-take-address=true, indirect-api=false, port-defined-argument-value{value=21, value-type=NvM_BlockIdType}, port=PS_NvBlockSwComponentTypeNVBlockDescriptor_BsConst_Audio}
        {enable-take-address=true, indirect-api=false, port-defined-argument-value{value=24, value-type=NvM_BlockIdType}, port=PS_NvBlockSwComponentTypeNVBlockDescriptor_BsConst_Communication}
        {enable-take-address=true, indirect-api=false, port-defined-argument-value{value=27, value-type=NvM_BlockIdType}, port=PS_NvBlockSwComponentTypeNVBlockDescriptor_BsConst_EngOffTimer}
        {enable-take-address=true, indirect-api=false, port-defined-argument-value{value=13, value-type=NvM_BlockIdType}, port=PS_NvBlockSwComponentTypeNVBlockDescriptor_BsConst_FuelGauge}
        {enable-take-address=true, indirect-api=false, port-defined-argument-value{value=18, value-type=NvM_BlockIdType}, port=PS_NvBlockSwComponentTypeNVBlockDescriptor_BsConst_Illumination}
        {enable-take-address=true, indirect-api=false, port-defined-argument-value{value=19, value-type=NvM_BlockIdType}, port=PS_NvBlockSwComponentTypeNVBlockDescriptor_BsConst_Illumination_Copy1}
        {enable-take-address=true, indirect-api=false, port-defined-argument-value{value=20, value-type=NvM_BlockIdType}, port=PS_NvBlockSwComponentTypeNVBlockDescriptor_BsConst_Illumination_Copy2}
        {enable-take-address=true, indirect-api=false, port-defined-argument-value{value=16, value-type=NvM_BlockIdType}, port=PS_NvBlockSwComponentTypeNVBlockDescriptor_BsConst_OilGauge}
        {enable-take-address=true, indirect-api=false, port-defined-argument-value{value=25, value-type=NvM_BlockIdType}, port=PS_NvBlockSwComponentTypeNVBlockDescriptor_BsConst_Power}
        {enable-take-address=true, indirect-api=false, port-defined-argument-value{value=15, value-type=NvM_BlockIdType}, port=PS_NvBlockSwComponentTypeNVBlockDescriptor_BsConst_PowerGauge}
        {enable-take-address=true, indirect-api=false, port-defined-argument-value{value=23, value-type=NvM_BlockIdType}, port=PS_NvBlockSwComponentTypeNVBlockDescriptor_BsConst_RealTimeClock}
        {enable-take-address=true, indirect-api=false, port-defined-argument-value{value=26, value-type=NvM_BlockIdType}, port=PS_NvBlockSwComponentTypeNVBlockDescriptor_BsConst_ServiceReminder}
        {enable-take-address=true, indirect-api=false, port-defined-argument-value{value=11, value-type=NvM_BlockIdType}, port=PS_NvBlockSwComponentTypeNVBlockDescriptor_BsConst_SpeedoGauge}
        {enable-take-address=true, indirect-api=false, port-defined-argument-value{value=12, value-type=NvM_BlockIdType}, port=PS_NvBlockSwComponentTypeNVBlockDescriptor_BsConst_TachoGauge}
        {enable-take-address=true, indirect-api=false, port-defined-argument-value{value=14, value-type=NvM_BlockIdType}, port=PS_NvBlockSwComponentTypeNVBlockDescriptor_BsConst_TempGauge}
        {enable-take-address=true, indirect-api=false, port-defined-argument-value{value=17, value-type=NvM_BlockIdType}, port=PS_NvBlockSwComponentTypeNVBlockDescriptor_BsConst_TripComputer}
        {enable-take-address=true, indirect-api=false, port-defined-argument-value{value=22, value-type=NvM_BlockIdType}, port=PS_NvBlockSwComponentTypeNVBlockDescriptor_BsConst_Warning}
        {enable-take-address=true, indirect-api=false, port-defined-argument-value{value=28, value-type=NvM_BlockIdType}, port=PS_NvBlockSwComponentTypeNVBlockDescriptor_BsCys_Certicificate}
        {enable-take-address=true, indirect-api=false, port-defined-argument-value{value=56, value-type=NvM_BlockIdType}, port=PS_NvBlockSwComponentTypeNVBlockDescriptor_BsDiag_Dtc}
        {enable-take-address=true, indirect-api=false, port-defined-argument-value{value=55, value-type=NvM_BlockIdType}, port=PS_NvBlockSwComponentTypeNVBlockDescriptor_BsDiag_ErrorRecord}
        {enable-take-address=true, indirect-api=false, port-defined-argument-value{value=48, value-type=NvM_BlockIdType}, port=PS_NvBlockSwComponentTypeNVBlockDescriptor_BsReten_Audio}
        {enable-take-address=true, indirect-api=false, port-defined-argument-value{value=51, value-type=NvM_BlockIdType}, port=PS_NvBlockSwComponentTypeNVBlockDescriptor_BsReten_Communication}
        {enable-take-address=true, indirect-api=false, port-defined-argument-value{value=54, value-type=NvM_BlockIdType}, port=PS_NvBlockSwComponentTypeNVBlockDescriptor_BsReten_Display}
        {enable-take-address=true, indirect-api=false, port-defined-argument-value{value=45, value-type=NvM_BlockIdType}, port=PS_NvBlockSwComponentTypeNVBlockDescriptor_BsReten_Gauges}
        {enable-take-address=true, indirect-api=false, port-defined-argument-value{value=47, value-type=NvM_BlockIdType}, port=PS_NvBlockSwComponentTypeNVBlockDescriptor_BsReten_Illumination}
        {enable-take-address=true, indirect-api=false, port-defined-argument-value{value=44, value-type=NvM_BlockIdType}, port=PS_NvBlockSwComponentTypeNVBlockDescriptor_BsReten_Odometer}
        {enable-take-address=true, indirect-api=false, port-defined-argument-value{value=52, value-type=NvM_BlockIdType}, port=PS_NvBlockSwComponentTypeNVBlockDescriptor_BsReten_Personalization}
        {enable-take-address=true, indirect-api=false, port-defined-argument-value{value=53, value-type=NvM_BlockIdType}, port=PS_NvBlockSwComponentTypeNVBlockDescriptor_BsReten_Power}
        {enable-take-address=true, indirect-api=false, port-defined-argument-value{value=50, value-type=NvM_BlockIdType}, port=PS_NvBlockSwComponentTypeNVBlockDescriptor_BsReten_RealTimeClock}
        {enable-take-address=true, indirect-api=false, port-defined-argument-value{value=46, value-type=NvM_BlockIdType}, port=PS_NvBlockSwComponentTypeNVBlockDescriptor_BsReten_Tripcomputer}
        {enable-take-address=true, indirect-api=false, port-defined-argument-value{value=49, value-type=NvM_BlockIdType}, port=PS_NvBlockSwComponentTypeNVBlockDescriptor_BsReten_Warning}
        {enable-take-address=true, indirect-api=false, port-defined-argument-value{value=43, value-type=NvM_BlockIdType}, port=PS_NvBlockSwComponentTypeNVBlockDescriptor_BsRt_CusDlt}
        {enable-take-address=true, indirect-api=false, port-defined-argument-value{value=34, value-type=NvM_BlockIdType}, port=PS_NvBlockSwComponentTypeNVBlockDescriptor_BsRt_FuelGauge}
        {enable-take-address=true, indirect-api=false, port-defined-argument-value{value=42, value-type=NvM_BlockIdType}, port=PS_NvBlockSwComponentTypeNVBlockDescriptor_BsRt_Illumination}
        {enable-take-address=true, indirect-api=false, port-defined-argument-value{value=31, value-type=NvM_BlockIdType}, port=PS_NvBlockSwComponentTypeNVBlockDescriptor_BsRt_Odometer}
        {enable-take-address=true, indirect-api=false, port-defined-argument-value{value=37, value-type=NvM_BlockIdType}, port=PS_NvBlockSwComponentTypeNVBlockDescriptor_BsRt_OilGauge}
        {enable-take-address=true, indirect-api=false, port-defined-argument-value{value=41, value-type=NvM_BlockIdType}, port=PS_NvBlockSwComponentTypeNVBlockDescriptor_BsRt_Personalization}
        {enable-take-address=true, indirect-api=false, port-defined-argument-value{value=36, value-type=NvM_BlockIdType}, port=PS_NvBlockSwComponentTypeNVBlockDescriptor_BsRt_PowerGauge}
        {enable-take-address=true, indirect-api=false, port-defined-argument-value{value=40, value-type=NvM_BlockIdType}, port=PS_NvBlockSwComponentTypeNVBlockDescriptor_BsRt_RealTimeClock}
        {enable-take-address=true, indirect-api=false, port-defined-argument-value{value=32, value-type=NvM_BlockIdType}, port=PS_NvBlockSwComponentTypeNVBlockDescriptor_BsRt_SpeedoGauge}
        {enable-take-address=true, indirect-api=false, port-defined-argument-value{value=33, value-type=NvM_BlockIdType}, port=PS_NvBlockSwComponentTypeNVBlockDescriptor_BsRt_TachoGauge}
        {enable-take-address=true, indirect-api=false, port-defined-argument-value{value=35, value-type=NvM_BlockIdType}, port=PS_NvBlockSwComponentTypeNVBlockDescriptor_BsRt_TempGauge}
        {enable-take-address=true, indirect-api=false, port-defined-argument-value{value=38, value-type=NvM_BlockIdType}, port=PS_NvBlockSwComponentTypeNVBlockDescriptor_BsRt_TripComputer}
        {enable-take-address=true, indirect-api=false, port-defined-argument-value{value=39, value-type=NvM_BlockIdType}, port=PS_NvBlockSwComponentTypeNVBlockDescriptor_BsRt_Warning}
        {enable-take-address=true, indirect-api=false, port-defined-argument-value{value=8, value-type=NvM_BlockIdType}, port=PS_NvBlockSwComponentTypeNVBlockDescriptor_BsShare_EcuPartNumber}
        {enable-take-address=true, indirect-api=false, port-defined-argument-value{value=5, value-type=NvM_BlockIdType}, port=PS_NvBlockSwComponentTypeNVBlockDescriptor_BsShare_SwUpdFotaFinPrint}
        {enable-take-address=true, indirect-api=false, port-defined-argument-value{value=4, value-type=NvM_BlockIdType}, port=PS_NvBlockSwComponentTypeNVBlockDescriptor_BsShare_SwUpdFotaMode}
        {enable-take-address=true, indirect-api=false, port-defined-argument-value{value=6, value-type=NvM_BlockIdType}, port=PS_NvBlockSwComponentTypeNVBlockDescriptor_BsShare_SwUpdFotaStatus}
        {enable-take-address=true, indirect-api=false, port-defined-argument-value{value=7, value-type=NvM_BlockIdType}, port=PS_NvBlockSwComponentTypeNVBlockDescriptor_BsShare_SwUpdFotadecrypt}
        {enable-take-address=true, indirect-api=false, port-defined-argument-value{value=2, value-type=NvM_BlockIdType}, port=PS_NvBlockSwComponentTypeNVBlockDescriptor_BsShare_SwUpdReflash}
        {enable-take-address=true, indirect-api=false, port-defined-argument-value{value=10, value-type=NvM_BlockIdType}, port=PS_NvBlockSwComponentTypeNVBlockDescriptor_BsShare_VehicleConfig}
        {enable-take-address=true, indirect-api=false, port-defined-argument-value{value=9, value-type=NvM_BlockIdType}, port=PS_NvBlockSwComponentTypeNVBlockDescriptor_BsShare_VisMeet}
        {enable-take-address=true, indirect-api=false, port-defined-argument-value{value=29, value-type=NvM_BlockIdType}, port=PS_NvBlockSwComponentTypeNVBlockDescriptor_RefCys_Certicificate}
        {enable-take-address=true, indirect-api=false, port-defined-argument-value{value=30, value-type=NvM_BlockIdType}, port=PS_NvBlockSwComponentTypeNVBlockDescriptor_RefCys_Certicificate1}
        enable-take-address=true, indirect-api=false, port=NvM_RpNotifyJobEnd_NvBlockSwComponentTypeNVBlockDescriptor_BsConst_Audio
        enable-take-address=true, indirect-api=false, port=NvM_RpNotifyJobEnd_NvBlockSwComponentTypeNVBlockDescriptor_BsConst_Communication
        enable-take-address=true, indirect-api=false, port=NvM_RpNotifyJobEnd_NvBlockSwComponentTypeNVBlockDescriptor_BsConst_EngOffTimer
        enable-take-address=true, indirect-api=false, port=NvM_RpNotifyJobEnd_NvBlockSwComponentTypeNVBlockDescriptor_BsConst_FuelGauge
        enable-take-address=true, indirect-api=false, port=NvM_RpNotifyJobEnd_NvBlockSwComponentTypeNVBlockDescriptor_BsConst_Illumination
        enable-take-address=true, indirect-api=false, port=NvM_RpNotifyJobEnd_NvBlockSwComponentTypeNVBlockDescriptor_BsConst_Illumination_Copy1
        enable-take-address=true, indirect-api=false, port=NvM_RpNotifyJobEnd_NvBlockSwComponentTypeNVBlockDescriptor_BsConst_Illumination_Copy2
        enable-take-address=true, indirect-api=false, port=NvM_RpNotifyJobEnd_NvBlockSwComponentTypeNVBlockDescriptor_BsConst_OilGauge
        enable-take-address=true, indirect-api=false, port=NvM_RpNotifyJobEnd_NvBlockSwComponentTypeNVBlockDescriptor_BsConst_Power
        enable-take-address=true, indirect-api=false, port=NvM_RpNotifyJobEnd_NvBlockSwComponentTypeNVBlockDescriptor_BsConst_PowerGauge
        enable-take-address=true, indirect-api=false, port=NvM_RpNotifyJobEnd_NvBlockSwComponentTypeNVBlockDescriptor_BsConst_RealTimeClock
        enable-take-address=true, indirect-api=false, port=NvM_RpNotifyJobEnd_NvBlockSwComponentTypeNVBlockDescriptor_BsConst_ServiceReminder
        enable-take-address=true, indirect-api=false, port=NvM_RpNotifyJobEnd_NvBlockSwComponentTypeNVBlockDescriptor_BsConst_SpeedoGauge
        enable-take-address=true, indirect-api=false, port=NvM_RpNotifyJobEnd_NvBlockSwComponentTypeNVBlockDescriptor_BsConst_TachoGauge
        enable-take-address=true, indirect-api=false, port=NvM_RpNotifyJobEnd_NvBlockSwComponentTypeNVBlockDescriptor_BsConst_TempGauge
        enable-take-address=true, indirect-api=false, port=NvM_RpNotifyJobEnd_NvBlockSwComponentTypeNVBlockDescriptor_BsConst_TripComputer
        enable-take-address=true, indirect-api=false, port=NvM_RpNotifyJobEnd_NvBlockSwComponentTypeNVBlockDescriptor_BsConst_Warning
        enable-take-address=true, indirect-api=false, port=NvM_RpNotifyJobEnd_NvBlockSwComponentTypeNVBlockDescriptor_BsCys_Certicificate
        enable-take-address=true, indirect-api=false, port=NvM_RpNotifyJobEnd_NvBlockSwComponentTypeNVBlockDescriptor_BsDiag_Dtc
        enable-take-address=true, indirect-api=false, port=NvM_RpNotifyJobEnd_NvBlockSwComponentTypeNVBlockDescriptor_BsDiag_ErrorRecord
        enable-take-address=true, indirect-api=false, port=NvM_RpNotifyJobEnd_NvBlockSwComponentTypeNVBlockDescriptor_BsReten_Audio
        enable-take-address=true, indirect-api=false, port=NvM_RpNotifyJobEnd_NvBlockSwComponentTypeNVBlockDescriptor_BsReten_Communication
        enable-take-address=true, indirect-api=false, port=NvM_RpNotifyJobEnd_NvBlockSwComponentTypeNVBlockDescriptor_BsReten_Display
        enable-take-address=true, indirect-api=false, port=NvM_RpNotifyJobEnd_NvBlockSwComponentTypeNVBlockDescriptor_BsReten_Gauges
        enable-take-address=true, indirect-api=false, port=NvM_RpNotifyJobEnd_NvBlockSwComponentTypeNVBlockDescriptor_BsReten_Illumination
        enable-take-address=true, indirect-api=false, port=NvM_RpNotifyJobEnd_NvBlockSwComponentTypeNVBlockDescriptor_BsReten_Odometer
        enable-take-address=true, indirect-api=false, port=NvM_RpNotifyJobEnd_NvBlockSwComponentTypeNVBlockDescriptor_BsReten_Personalization
        enable-take-address=true, indirect-api=false, port=NvM_RpNotifyJobEnd_NvBlockSwComponentTypeNVBlockDescriptor_BsReten_Power
        enable-take-address=true, indirect-api=false, port=NvM_RpNotifyJobEnd_NvBlockSwComponentTypeNVBlockDescriptor_BsReten_RealTimeClock
        enable-take-address=true, indirect-api=false, port=NvM_RpNotifyJobEnd_NvBlockSwComponentTypeNVBlockDescriptor_BsReten_Tripcomputer
        enable-take-address=true, indirect-api=false, port=NvM_RpNotifyJobEnd_NvBlockSwComponentTypeNVBlockDescriptor_BsReten_Warning
        enable-take-address=true, indirect-api=false, port=NvM_RpNotifyJobEnd_NvBlockSwComponentTypeNVBlockDescriptor_BsRt_CusDlt
        enable-take-address=true, indirect-api=false, port=NvM_RpNotifyJobEnd_NvBlockSwComponentTypeNVBlockDescriptor_BsRt_FuelGauge
        enable-take-address=true, indirect-api=false, port=NvM_RpNotifyJobEnd_NvBlockSwComponentTypeNVBlockDescriptor_BsRt_Illumination
        enable-take-address=true, indirect-api=false, port=NvM_RpNotifyJobEnd_NvBlockSwComponentTypeNVBlockDescriptor_BsRt_Odometer
        enable-take-address=true, indirect-api=false, port=NvM_RpNotifyJobEnd_NvBlockSwComponentTypeNVBlockDescriptor_BsRt_OilGauge
        enable-take-address=true, indirect-api=false, port=NvM_RpNotifyJobEnd_NvBlockSwComponentTypeNVBlockDescriptor_BsRt_Personalization
        enable-take-address=true, indirect-api=false, port=NvM_RpNotifyJobEnd_NvBlockSwComponentTypeNVBlockDescriptor_BsRt_PowerGauge
        enable-take-address=true, indirect-api=false, port=NvM_RpNotifyJobEnd_NvBlockSwComponentTypeNVBlockDescriptor_BsRt_RealTimeClock
        enable-take-address=true, indirect-api=false, port=NvM_RpNotifyJobEnd_NvBlockSwComponentTypeNVBlockDescriptor_BsRt_SpeedoGauge
        enable-take-address=true, indirect-api=false, port=NvM_RpNotifyJobEnd_NvBlockSwComponentTypeNVBlockDescriptor_BsRt_TachoGauge
        enable-take-address=true, indirect-api=false, port=NvM_RpNotifyJobEnd_NvBlockSwComponentTypeNVBlockDescriptor_BsRt_TempGauge
        enable-take-address=true, indirect-api=false, port=NvM_RpNotifyJobEnd_NvBlockSwComponentTypeNVBlockDescriptor_BsRt_TripComputer
        enable-take-address=true, indirect-api=false, port=NvM_RpNotifyJobEnd_NvBlockSwComponentTypeNVBlockDescriptor_BsRt_Warning
        enable-take-address=true, indirect-api=false, port=NvM_RpNotifyJobEnd_NvBlockSwComponentTypeNVBlockDescriptor_BsShare_EcuPartNumber
        enable-take-address=true, indirect-api=false, port=NvM_RpNotifyJobEnd_NvBlockSwComponentTypeNVBlockDescriptor_BsShare_SwUpdFotaFinPrint
        enable-take-address=true, indirect-api=false, port=NvM_RpNotifyJobEnd_NvBlockSwComponentTypeNVBlockDescriptor_BsShare_SwUpdFotaMode
        enable-take-address=true, indirect-api=false, port=NvM_RpNotifyJobEnd_NvBlockSwComponentTypeNVBlockDescriptor_BsShare_SwUpdFotaStatus
        enable-take-address=true, indirect-api=false, port=NvM_RpNotifyJobEnd_NvBlockSwComponentTypeNVBlockDescriptor_BsShare_SwUpdFotadecrypt
        enable-take-address=true, indirect-api=false, port=NvM_RpNotifyJobEnd_NvBlockSwComponentTypeNVBlockDescriptor_BsShare_SwUpdReflash
        enable-take-address=true, indirect-api=false, port=NvM_RpNotifyJobEnd_NvBlockSwComponentTypeNVBlockDescriptor_BsShare_VehicleConfig
        enable-take-address=true, indirect-api=false, port=NvM_RpNotifyJobEnd_NvBlockSwComponentTypeNVBlockDescriptor_BsShare_VisMeet
        enable-take-address=true, indirect-api=false, port=NvM_RpNotifyJobEnd_NvBlockSwComponentTypeNVBlockDescriptor_RefCys_Certicificate
        enable-take-address=true, indirect-api=false, port=NvM_RpNotifyJobEnd_NvBlockSwComponentTypeNVBlockDescriptor_RefCys_Certicificate1
      11 x runnable:
        NvM_MainFunction
          54 x sync call, all with timeout=0:
            OpServerCallNvM_MainFunction_JobFinished_NvM_RpNotifyJobEnd_NvBlockSwComponentTypeNVBlockDescriptor_BsConst_Audio: operation=NvM_RpNotifyJobEnd_NvBlockSwComponentTypeNVBlockDescriptor_BsConst_Audio.JobFinished
            OpServerCallNvM_MainFunction_JobFinished_NvM_RpNotifyJobEnd_NvBlockSwComponentTypeNVBlockDescriptor_BsConst_Communication: operation=NvM_RpNotifyJobEnd_NvBlockSwComponentTypeNVBlockDescriptor_BsConst_Communication.JobFinished
            OpServerCallNvM_MainFunction_JobFinished_NvM_RpNotifyJobEnd_NvBlockSwComponentTypeNVBlockDescriptor_BsConst_EngOffTimer: operation=NvM_RpNotifyJobEnd_NvBlockSwComponentTypeNVBlockDescriptor_BsConst_EngOffTimer.JobFinished
            OpServerCallNvM_MainFunction_JobFinished_NvM_RpNotifyJobEnd_NvBlockSwComponentTypeNVBlockDescriptor_BsConst_FuelGauge: operation=NvM_RpNotifyJobEnd_NvBlockSwComponentTypeNVBlockDescriptor_BsConst_FuelGauge.JobFinished
            OpServerCallNvM_MainFunction_JobFinished_NvM_RpNotifyJobEnd_NvBlockSwComponentTypeNVBlockDescriptor_BsConst_Illumination: operation=NvM_RpNotifyJobEnd_NvBlockSwComponentTypeNVBlockDescriptor_BsConst_Illumination.JobFinished
            OpServerCallNvM_MainFunction_JobFinished_NvM_RpNotifyJobEnd_NvBlockSwComponentTypeNVBlockDescriptor_BsConst_Illumination_Copy1: operation=NvM_RpNotifyJobEnd_NvBlockSwComponentTypeNVBlockDescriptor_BsConst_Illumination_Copy1.JobFinished
            OpServerCallNvM_MainFunction_JobFinished_NvM_RpNotifyJobEnd_NvBlockSwComponentTypeNVBlockDescriptor_BsConst_Illumination_Copy2: operation=NvM_RpNotifyJobEnd_NvBlockSwComponentTypeNVBlockDescriptor_BsConst_Illumination_Copy2.JobFinished
            OpServerCallNvM_MainFunction_JobFinished_NvM_RpNotifyJobEnd_NvBlockSwComponentTypeNVBlockDescriptor_BsConst_OilGauge: operation=NvM_RpNotifyJobEnd_NvBlockSwComponentTypeNVBlockDescriptor_BsConst_OilGauge.JobFinished
            OpServerCallNvM_MainFunction_JobFinished_NvM_RpNotifyJobEnd_NvBlockSwComponentTypeNVBlockDescriptor_BsConst_Power: operation=NvM_RpNotifyJobEnd_NvBlockSwComponentTypeNVBlockDescriptor_BsConst_Power.JobFinished
            OpServerCallNvM_MainFunction_JobFinished_NvM_RpNotifyJobEnd_NvBlockSwComponentTypeNVBlockDescriptor_BsConst_PowerGauge: operation=NvM_RpNotifyJobEnd_NvBlockSwComponentTypeNVBlockDescriptor_BsConst_PowerGauge.JobFinished
            OpServerCallNvM_MainFunction_JobFinished_NvM_RpNotifyJobEnd_NvBlockSwComponentTypeNVBlockDescriptor_BsConst_RealTimeClock: operation=NvM_RpNotifyJobEnd_NvBlockSwComponentTypeNVBlockDescriptor_BsConst_RealTimeClock.JobFinished
            OpServerCallNvM_MainFunction_JobFinished_NvM_RpNotifyJobEnd_NvBlockSwComponentTypeNVBlockDescriptor_BsConst_ServiceReminder: operation=NvM_RpNotifyJobEnd_NvBlockSwComponentTypeNVBlockDescriptor_BsConst_ServiceReminder.JobFinished
            OpServerCallNvM_MainFunction_JobFinished_NvM_RpNotifyJobEnd_NvBlockSwComponentTypeNVBlockDescriptor_BsConst_SpeedoGauge: operation=NvM_RpNotifyJobEnd_NvBlockSwComponentTypeNVBlockDescriptor_BsConst_SpeedoGauge.JobFinished
            OpServerCallNvM_MainFunction_JobFinished_NvM_RpNotifyJobEnd_NvBlockSwComponentTypeNVBlockDescriptor_BsConst_TachoGauge: operation=NvM_RpNotifyJobEnd_NvBlockSwComponentTypeNVBlockDescriptor_BsConst_TachoGauge.JobFinished
            OpServerCallNvM_MainFunction_JobFinished_NvM_RpNotifyJobEnd_NvBlockSwComponentTypeNVBlockDescriptor_BsConst_TempGauge: operation=NvM_RpNotifyJobEnd_NvBlockSwComponentTypeNVBlockDescriptor_BsConst_TempGauge.JobFinished
            OpServerCallNvM_MainFunction_JobFinished_NvM_RpNotifyJobEnd_NvBlockSwComponentTypeNVBlockDescriptor_BsConst_TripComputer: operation=NvM_RpNotifyJobEnd_NvBlockSwComponentTypeNVBlockDescriptor_BsConst_TripComputer.JobFinished
            OpServerCallNvM_MainFunction_JobFinished_NvM_RpNotifyJobEnd_NvBlockSwComponentTypeNVBlockDescriptor_BsConst_Warning: operation=NvM_RpNotifyJobEnd_NvBlockSwComponentTypeNVBlockDescriptor_BsConst_Warning.JobFinished
            OpServerCallNvM_MainFunction_JobFinished_NvM_RpNotifyJobEnd_NvBlockSwComponentTypeNVBlockDescriptor_BsCys_Certicificate: operation=NvM_RpNotifyJobEnd_NvBlockSwComponentTypeNVBlockDescriptor_BsCys_Certicificate.JobFinished
            OpServerCallNvM_MainFunction_JobFinished_NvM_RpNotifyJobEnd_NvBlockSwComponentTypeNVBlockDescriptor_BsDiag_Dtc: operation=NvM_RpNotifyJobEnd_NvBlockSwComponentTypeNVBlockDescriptor_BsDiag_Dtc.JobFinished
            OpServerCallNvM_MainFunction_JobFinished_NvM_RpNotifyJobEnd_NvBlockSwComponentTypeNVBlockDescriptor_BsDiag_ErrorRecord: operation=NvM_RpNotifyJobEnd_NvBlockSwComponentTypeNVBlockDescriptor_BsDiag_ErrorRecord.JobFinished
            OpServerCallNvM_MainFunction_JobFinished_NvM_RpNotifyJobEnd_NvBlockSwComponentTypeNVBlockDescriptor_BsReten_Audio: operation=NvM_RpNotifyJobEnd_NvBlockSwComponentTypeNVBlockDescriptor_BsReten_Audio.JobFinished
            OpServerCallNvM_MainFunction_JobFinished_NvM_RpNotifyJobEnd_NvBlockSwComponentTypeNVBlockDescriptor_BsReten_Communication: operation=NvM_RpNotifyJobEnd_NvBlockSwComponentTypeNVBlockDescriptor_BsReten_Communication.JobFinished
            OpServerCallNvM_MainFunction_JobFinished_NvM_RpNotifyJobEnd_NvBlockSwComponentTypeNVBlockDescriptor_BsReten_Display: operation=NvM_RpNotifyJobEnd_NvBlockSwComponentTypeNVBlockDescriptor_BsReten_Display.JobFinished
            OpServerCallNvM_MainFunction_JobFinished_NvM_RpNotifyJobEnd_NvBlockSwComponentTypeNVBlockDescriptor_BsReten_Gauges: operation=NvM_RpNotifyJobEnd_NvBlockSwComponentTypeNVBlockDescriptor_BsReten_Gauges.JobFinished
            OpServerCallNvM_MainFunction_JobFinished_NvM_RpNotifyJobEnd_NvBlockSwComponentTypeNVBlockDescriptor_BsReten_Illumination: operation=NvM_RpNotifyJobEnd_NvBlockSwComponentTypeNVBlockDescriptor_BsReten_Illumination.JobFinished
            OpServerCallNvM_MainFunction_JobFinished_NvM_RpNotifyJobEnd_NvBlockSwComponentTypeNVBlockDescriptor_BsReten_Odometer: operation=NvM_RpNotifyJobEnd_NvBlockSwComponentTypeNVBlockDescriptor_BsReten_Odometer.JobFinished
            OpServerCallNvM_MainFunction_JobFinished_NvM_RpNotifyJobEnd_NvBlockSwComponentTypeNVBlockDescriptor_BsReten_Personalization: operation=NvM_RpNotifyJobEnd_NvBlockSwComponentTypeNVBlockDescriptor_BsReten_Personalization.JobFinished
            OpServerCallNvM_MainFunction_JobFinished_NvM_RpNotifyJobEnd_NvBlockSwComponentTypeNVBlockDescriptor_BsReten_Power: operation=NvM_RpNotifyJobEnd_NvBlockSwComponentTypeNVBlockDescriptor_BsReten_Power.JobFinished
            OpServerCallNvM_MainFunction_JobFinished_NvM_RpNotifyJobEnd_NvBlockSwComponentTypeNVBlockDescriptor_BsReten_RealTimeClock: operation=NvM_RpNotifyJobEnd_NvBlockSwComponentTypeNVBlockDescriptor_BsReten_RealTimeClock.JobFinished
            OpServerCallNvM_MainFunction_JobFinished_NvM_RpNotifyJobEnd_NvBlockSwComponentTypeNVBlockDescriptor_BsReten_Tripcomputer: operation=NvM_RpNotifyJobEnd_NvBlockSwComponentTypeNVBlockDescriptor_BsReten_Tripcomputer.JobFinished
            OpServerCallNvM_MainFunction_JobFinished_NvM_RpNotifyJobEnd_NvBlockSwComponentTypeNVBlockDescriptor_BsReten_Warning: operation=NvM_RpNotifyJobEnd_NvBlockSwComponentTypeNVBlockDescriptor_BsReten_Warning.JobFinished
            OpServerCallNvM_MainFunction_JobFinished_NvM_RpNotifyJobEnd_NvBlockSwComponentTypeNVBlockDescriptor_BsRt_CusDlt: operation=NvM_RpNotifyJobEnd_NvBlockSwComponentTypeNVBlockDescriptor_BsRt_CusDlt.JobFinished
            OpServerCallNvM_MainFunction_JobFinished_NvM_RpNotifyJobEnd_NvBlockSwComponentTypeNVBlockDescriptor_BsRt_FuelGauge: operation=NvM_RpNotifyJobEnd_NvBlockSwComponentTypeNVBlockDescriptor_BsRt_FuelGauge.JobFinished
            OpServerCallNvM_MainFunction_JobFinished_NvM_RpNotifyJobEnd_NvBlockSwComponentTypeNVBlockDescriptor_BsRt_Illumination: operation=NvM_RpNotifyJobEnd_NvBlockSwComponentTypeNVBlockDescriptor_BsRt_Illumination.JobFinished
            OpServerCallNvM_MainFunction_JobFinished_NvM_RpNotifyJobEnd_NvBlockSwComponentTypeNVBlockDescriptor_BsRt_Odometer: operation=NvM_RpNotifyJobEnd_NvBlockSwComponentTypeNVBlockDescriptor_BsRt_Odometer.JobFinished
            OpServerCallNvM_MainFunction_JobFinished_NvM_RpNotifyJobEnd_NvBlockSwComponentTypeNVBlockDescriptor_BsRt_OilGauge: operation=NvM_RpNotifyJobEnd_NvBlockSwComponentTypeNVBlockDescriptor_BsRt_OilGauge.JobFinished
            OpServerCallNvM_MainFunction_JobFinished_NvM_RpNotifyJobEnd_NvBlockSwComponentTypeNVBlockDescriptor_BsRt_Personalization: operation=NvM_RpNotifyJobEnd_NvBlockSwComponentTypeNVBlockDescriptor_BsRt_Personalization.JobFinished
            OpServerCallNvM_MainFunction_JobFinished_NvM_RpNotifyJobEnd_NvBlockSwComponentTypeNVBlockDescriptor_BsRt_PowerGauge: operation=NvM_RpNotifyJobEnd_NvBlockSwComponentTypeNVBlockDescriptor_BsRt_PowerGauge.JobFinished
            OpServerCallNvM_MainFunction_JobFinished_NvM_RpNotifyJobEnd_NvBlockSwComponentTypeNVBlockDescriptor_BsRt_RealTimeClock: operation=NvM_RpNotifyJobEnd_NvBlockSwComponentTypeNVBlockDescriptor_BsRt_RealTimeClock.JobFinished
            OpServerCallNvM_MainFunction_JobFinished_NvM_RpNotifyJobEnd_NvBlockSwComponentTypeNVBlockDescriptor_BsRt_SpeedoGauge: operation=NvM_RpNotifyJobEnd_NvBlockSwComponentTypeNVBlockDescriptor_BsRt_SpeedoGauge.JobFinished
            OpServerCallNvM_MainFunction_JobFinished_NvM_RpNotifyJobEnd_NvBlockSwComponentTypeNVBlockDescriptor_BsRt_TachoGauge: operation=NvM_RpNotifyJobEnd_NvBlockSwComponentTypeNVBlockDescriptor_BsRt_TachoGauge.JobFinished
            OpServerCallNvM_MainFunction_JobFinished_NvM_RpNotifyJobEnd_NvBlockSwComponentTypeNVBlockDescriptor_BsRt_TempGauge: operation=NvM_RpNotifyJobEnd_NvBlockSwComponentTypeNVBlockDescriptor_BsRt_TempGauge.JobFinished
            OpServerCallNvM_MainFunction_JobFinished_NvM_RpNotifyJobEnd_NvBlockSwComponentTypeNVBlockDescriptor_BsRt_TripComputer: operation=NvM_RpNotifyJobEnd_NvBlockSwComponentTypeNVBlockDescriptor_BsRt_TripComputer.JobFinished
            OpServerCallNvM_MainFunction_JobFinished_NvM_RpNotifyJobEnd_NvBlockSwComponentTypeNVBlockDescriptor_BsRt_Warning: operation=NvM_RpNotifyJobEnd_NvBlockSwComponentTypeNVBlockDescriptor_BsRt_Warning.JobFinished
            OpServerCallNvM_MainFunction_JobFinished_NvM_RpNotifyJobEnd_NvBlockSwComponentTypeNVBlockDescriptor_BsShare_EcuPartNumber: operation=NvM_RpNotifyJobEnd_NvBlockSwComponentTypeNVBlockDescriptor_BsShare_EcuPartNumber.JobFinished
            OpServerCallNvM_MainFunction_JobFinished_NvM_RpNotifyJobEnd_NvBlockSwComponentTypeNVBlockDescriptor_BsShare_SwUpdFotaFinPrint: operation=NvM_RpNotifyJobEnd_NvBlockSwComponentTypeNVBlockDescriptor_BsShare_SwUpdFotaFinPrint.JobFinished
            OpServerCallNvM_MainFunction_JobFinished_NvM_RpNotifyJobEnd_NvBlockSwComponentTypeNVBlockDescriptor_BsShare_SwUpdFotaMode: operation=NvM_RpNotifyJobEnd_NvBlockSwComponentTypeNVBlockDescriptor_BsShare_SwUpdFotaMode.JobFinished
            OpServerCallNvM_MainFunction_JobFinished_NvM_RpNotifyJobEnd_NvBlockSwComponentTypeNVBlockDescriptor_BsShare_SwUpdFotaStatus: operation=NvM_RpNotifyJobEnd_NvBlockSwComponentTypeNVBlockDescriptor_BsShare_SwUpdFotaStatus.JobFinished
            OpServerCallNvM_MainFunction_JobFinished_NvM_RpNotifyJobEnd_NvBlockSwComponentTypeNVBlockDescriptor_BsShare_SwUpdFotadecrypt: operation=NvM_RpNotifyJobEnd_NvBlockSwComponentTypeNVBlockDescriptor_BsShare_SwUpdFotadecrypt.JobFinished
            OpServerCallNvM_MainFunction_JobFinished_NvM_RpNotifyJobEnd_NvBlockSwComponentTypeNVBlockDescriptor_BsShare_SwUpdReflash: operation=NvM_RpNotifyJobEnd_NvBlockSwComponentTypeNVBlockDescriptor_BsShare_SwUpdReflash.JobFinished
            OpServerCallNvM_MainFunction_JobFinished_NvM_RpNotifyJobEnd_NvBlockSwComponentTypeNVBlockDescriptor_BsShare_VehicleConfig: operation=NvM_RpNotifyJobEnd_NvBlockSwComponentTypeNVBlockDescriptor_BsShare_VehicleConfig.JobFinished
            OpServerCallNvM_MainFunction_JobFinished_NvM_RpNotifyJobEnd_NvBlockSwComponentTypeNVBlockDescriptor_BsShare_VisMeet: operation=NvM_RpNotifyJobEnd_NvBlockSwComponentTypeNVBlockDescriptor_BsShare_VisMeet.JobFinished
            OpServerCallNvM_MainFunction_JobFinished_NvM_RpNotifyJobEnd_NvBlockSwComponentTypeNVBlockDescriptor_RefCys_Certicificate: operation=NvM_RpNotifyJobEnd_NvBlockSwComponentTypeNVBlockDescriptor_RefCys_Certicificate.JobFinished
            OpServerCallNvM_MainFunction_JobFinished_NvM_RpNotifyJobEnd_NvBlockSwComponentTypeNVBlockDescriptor_RefCys_Certicificate1: operation=NvM_RpNotifyJobEnd_NvBlockSwComponentTypeNVBlockDescriptor_RefCys_Certicificate1.JobFinished
        GetErrorStatus: can-be-invoked-concurrently=true, symbol=NvM_GetErrorStatus
        SetRamBlockStatus: can-be-invoked-concurrently=true, symbol=NvM_SetRamBlockStatus
        ReadBlock: can-be-invoked-concurrently=true, symbol=NvM_ReadBlock
        WriteBlock: can-be-invoked-concurrently=true, symbol=NvM_WriteBlock
        RestoreBlockDefaults: can-be-invoked-concurrently=true, symbol=NvM_RestoreBlockDefaults
        InvalidateNvBlock: can-be-invoked-concurrently=true, symbol=NvM_InvalidateNvBlock
        EraseBlock: can-be-invoked-concurrently=true, symbol=NvM_EraseNvBlock
        SetBlockProtection: can-be-invoked-concurrently=true, symbol=NvM_SetBlockProtection
        SetDataIndex: can-be-invoked-concurrently=true, symbol=NvM_SetDataIndex
        GetDataIndex: can-be-invoked-concurrently=true, symbol=NvM_GetDataIndex
  swc implementation NvMImplementation: programming-language=C, behavior=NvMInternalBehavior
